VERSION ""

NS_ :

BS_:

BU_: APIM_CISM APIM ESPM DSP FCIMB RACM_RCIM HUD_ADV WCM TRM_ITRM ACM GWM _delete IPC GENERIC TSTR
VAL_TABLE_ AwdRnge_D_Actl 7 "Unknown" 6 "High_Range_2wd" 5 "High_Range_Auto" 4 "High_Range_Locked" 3 "Neutral" 2 "Low_Range_2wd" 1 "Low_Range_Auto" 0 "Low_Range_Locked" ;
VAL_TABLE_ AwdLck_D_Stat 9 "Undefined" 8 "Under_External_Torque_Ctrl" 7 "Torque_Limited_by_Cmd" 6 "Fully_Locked_by_Cmd" 5 "Disabled" 4 "Warning" 3 "Fault" 2 "Inactive" 1 "Completely_Opened_by_Cmd" 0 "OK" ;
VAL_TABLE_ Unknown_Fault_3FE_3FF 1023 "Fault" 1022 "Unknown" ;
VAL_TABLE_ LockSwStat 3 "Invalid" 2 "Unlock" 1 "Lock" 0 "Null" ;
VAL_TABLE_ Null_Override 1 "Override" 0 "Null" ;
VAL_TABLE_ Off_On_Flash 3 "Not_Used" 2 "Flash" 1 "On" 0 "Off" ;
VAL_TABLE_ BeltBuckle 3 "Unknown" 2 "Unbelted" 1 "Belted" 0 "Faulty" ;
VAL_TABLE_ RILStat 3 "Fault" 2 "Plant_Mode" 1 "On" 0 "Off" ;
VAL_TABLE_ RILReqCoding 3 "Not_Used" 2 "Plant_Mode" 1 "On" 0 "Off" ;
VAL_TABLE_ Update_Bit 1 "Fresh_data" 0 "Unchanged_data" ;
VAL_TABLE_ Tire_Pressure_Stat 4 "Alert" 15 "Not_Supported" 3 "Fault" 2 "Low" 1 "Normal" 0 "Unknown" ;
VAL_TABLE_ Tire_Pressure_System2 13 "Training_Complete" 12 "Train_InsideLeftRear_tire" 11 "Train_OutsideLeftRear_tire" 10 "Train_LeftRear_tire" 9 "Train_InsideRtRear_tire" 8 "Train_OutsideRtRear_tire" 7 "Train_RightRear_tire" 14 "Tires_not_trained" 6 "Train_RightFront_tire" 5 "Train_LeftFront_tire" 4 "Systm_Activ_Composite_Stat" 3 "Low_Composite_Stat" 2 "Sensr_Fault_Composite_Stat" 1 "Systm_Fault_Composite_Stat" 0 "Unknown_Composite_Stat" ;
VAL_TABLE_ Running_Board 3 "Unused" 2 "Manually_Deployed" 1 "All_Enabled" 0 "All_Disabled" ;
VAL_TABLE_ Turn_Seq 3 "Seq" 2 "On" 1 "Off" 0 "Null" ;
VAL_TABLE_ Invalid_Active_Inactive 3 "Not_Used" 2 "Inactive" 1 "Active" 0 "Invalid" ;
VAL_TABLE_ Rvc_Zoom 7 "Unknown" 6 "Invalid" 5 "Zoom_Level_V" 4 "Zoom_Level_IV" 3 "Zoom_Level_III" 2 "Zoom_Level_II" 1 "Zoom_Level_I" 0 "Off" ;
VAL_TABLE_ NotPark 1 "Park" 0 "Not_Park" ;
VAL_TABLE_ Electric_EOH 1 "Electric_Over_Hydraulic" 0 "Electric" ;
VAL_TABLE_ PersOptIn 1 "OPTED_IN" 0 "NOT_OPTED_IN" ;
VAL_TABLE_ PersonalSetUp 3 "Non_Moveable_Person" 2 "Moveable_Person" 1 "Vehicle" 0 "Factory" ;
VAL_TABLE_ Full_Limited 1 "Limited" 0 "Full" ;
VAL_TABLE_ NoConflict_Conflict 1 "Conflict" 0 "No_Conflict" ;
VAL_TABLE_ Assoc_Confirm 0 "None" 7 "Associate" 6 "Keycode_Rejected" 5 "Keycode_Accepted" 4 "In_Progress" 3 "Erase" 2 "Duplicate" 1 "Disassociate" ;
VAL_TABLE_ Check_KeyCode 7 "Unused_2" 6 "Cancel" 5 "Set_Keycode" 4 "RKE" 3 "Null" 2 "Key" 1 "Erase_KeyCode" 0 "Check_KeyCode" ;
VAL_TABLE_ Complete_Inprogress 3 "Unused" 2 "Null" 1 "InProgress" 0 "Complete" ;
VAL_TABLE_ Null_Pers1_4 7 "Unused_3" 6 "Unused_2" 5 "Unused_1" 4 "PERS_4" 3 "PERS_3" 2 "PERS_2" 1 "PERS_1" 0 "Null" ;
VAL_TABLE_ Pers1_4 7 "Unused_3" 6 "Unused_2" 5 "Unused_1" 4 "Vehicle" 3 "PERS_4" 2 "PERS_3" 1 "PERS_2" 0 "PERS_1" ;
VAL_TABLE_ Null_Query 7 "Unused_2" 6 "Unused_1" 5 "Copy" 4 "Restore" 3 "Upload" 2 "Set" 1 "Query" 0 "Null" ;
VAL_TABLE_ EngExhBrkMde_D_Actl 6 "ExhBrkDisable_NoError" 5 "ExhBrkActive_AUTO" 4 "ExhBrkActive_ON" 3 "ExhBrkRequest_AUTO" 2 "ExhBrkRequest_ON" 1 "ExhBrkNoRequest_OFF" 0 "ExhBrkUnavailable_Error" ;
VAL_TABLE_ UreaLvlTxt_D_RqDsply 15 "NotUsed_4" 14 "NotUsed_3" 13 "NotUsed_2" 12 "NotUsed_1" 11 "System_Error" 10 "Engine_Idled_See_Manual" 9 "Engine_Idled_Upon_Refuel" 8 "Speed_Limited_To_XX_mph" 7 "XXmph_Max_Upon_Restart" 6 "Speed_Limited_To_YY_mph" 5 "YYmph_Max_Upon_Restart" 4 "SpdLimtd_YYmph_In_XXmiles" 3 "ExFlRange_XXMiles_ScndWarn" 2 "Exh_Fluid_Range_XX_Miles" 1 "Exh_Fluid_Under_Half_Full" 0 "Exh_Fluid_Over_Half_Full" ;
VAL_TABLE_ RearDiffFalt_D_Stat 3 "Diff_Failed_Closed" 2 "Diff_Failed_Open" 1 "Fault_Non_Specific" 0 "No_Fault" ;
VAL_TABLE_ CCOverridden 1 "Cruise_Overridden" 0 "Cruise_Req_Not_Overridden" ;
VAL_TABLE_ Ign_Key_Device_Type 15 "Invalid" 14 "Unknown" 3 "Key_Not_Prgrm_Read_Failure" 2 "Key_In_Ign_My_Key" 1 "Key_In_Ign_Standard_Key" 0 "Key_Read_In_Progress" ;
VAL_TABLE_ Off_No_Eff_Unknown_Invalid 3 "Invalid" 2 "Unknown" 1 "No_Effect" 0 "Off" ;
VAL_TABLE_ Null_Out 1 "Out" 0 "Null" ;
VAL_TABLE_ FUEL_SENSORS 1 "Dual_Sensors" 0 "Single_Sensor" ;

BO_ 1204 HEV_EngineData2_HS3: 8 GWM
 SG_ DcacElPwScnd_D_Stat : 7|2@0+ (1,0) [0|3] "SED"  APIM
 SG_ DcacEngOnMsgTxt_D2_Rq : 5|4@0+ (1,0) [0|15] "SED"  APIM
 SG_ DcacOutScnd_Pw_DsplyMx : 15|10@0+ (10,0) [0|10220] "watts"  APIM
 SG_ DcacOutScnd_Pw2_Dsply : 21|13@0+ (1,0) [0|8189] "watts"  APIM
 SG_ DcacZone3Pw_B_Stat : 0|1@0+ (1,0) [0|1] "SED"  APIM
 SG_ DcacZone2Pw_B_Stat : 1|1@0+ (1,0) [0|1] "SED"  APIM

BO_ 826 Memory_Sw_StatM_HS3: 8 GWM
 SG_ Memory_3_Sw_Stat : 4|1@0+ (1,0) [0|1] "SED" Vector__XXX
 SG_ Memory_2_Sw_Stat : 5|1@0+ (1,0) [0|1] "SED" Vector__XXX
 SG_ Memory_1_Sw_Stat : 6|1@0+ (1,0) [0|1] "SED" Vector__XXX
 SG_ Mirror_Manual_Override : 0|1@0+ (1,0) [0|1] "SED"  APIM_CISM

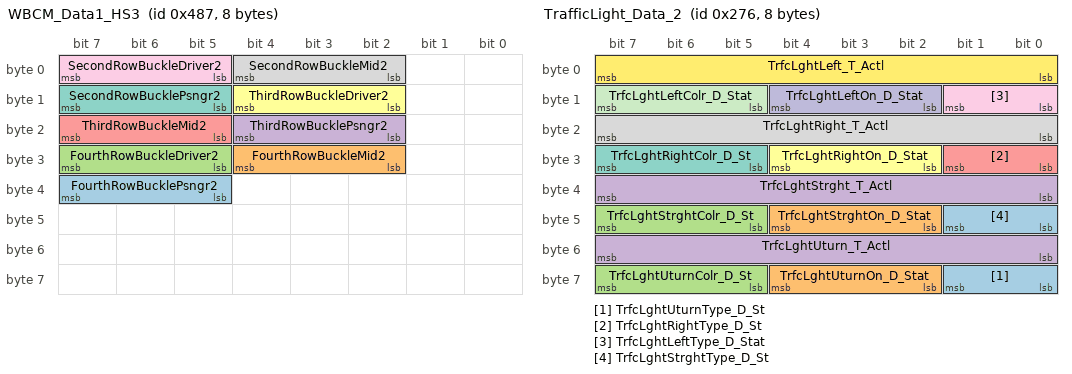
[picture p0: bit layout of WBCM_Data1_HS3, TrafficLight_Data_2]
BO_ 1159 WBCM_Data1_HS3: 8 GWM
 SG_ FourthRowBucklePsngr2 : 39|3@0+ (1,0) [0|7] "SED"  IPC
 SG_ FourthRowBuckleMid2 : 28|3@0+ (1,0) [0|7] "SED"  IPC
 SG_ FourthRowBuckleDriver2 : 31|3@0+ (1,0) [0|7] "SED"  IPC
 SG_ ThirdRowBucklePsngr2 : 20|3@0+ (1,0) [0|7] "SED"  IPC
 SG_ ThirdRowBuckleMid2 : 23|3@0+ (1,0) [0|7] "SED"  IPC
 SG_ ThirdRowBuckleDriver2 : 12|3@0+ (1,0) [0|7] "SED"  IPC
 SG_ SecondRowBucklePsngr2 : 15|3@0+ (1,0) [0|7] "SED"  IPC
 SG_ SecondRowBuckleMid2 : 4|3@0+ (1,0) [0|7] "SED"  IPC
 SG_ SecondRowBuckleDriver2 : 7|3@0+ (1,0) [0|7] "SED"  IPC

BO_ 667 APIM_NFAM_Word_Rx_HS3: 8 GWM
 SG_ APIM_NFAM_Word_Rx : 7|64@0+ (1,0) [0|1.84467440737096E+019] "unitless"  APIM,APIM_CISM

BO_ 659 APIM_NFAM_Word_Tx: 8 APIM
 SG_ APIM_NFAM_Word_Tx : 7|64@0+ (1,0) [0|1.84467440737096E+019] "unitless"  GWM

BO_ 645 ECG_Data5_HS3: 8 GWM
 SG_ VehImpactCode_No2_Actl : 7|16@0+ (1,0) [0|65535] "unitless"  APIM,APIM_CISM

BO_ 1040 AC_Compressor_Req_HS3: 8 GWM
 SG_ VehSimSnd_Pc_Rq : 33|10@0+ (0.2,-102.2) [-102.2|102.4] "percent"  APIM_CISM,ACM
 SG_ ElCmpr2Enbl_B_Rq : 36|1@0+ (1,0) [0|1] "SED" Vector__XXX
 SG_ ElCmpr2_N_Rq : 7|8@0+ (50,0) [0|12750] "RPM" Vector__XXX
 SG_ BattTrac_I2_EstVsc : 22|18@0+ (0.05,-6553.52) [-6553.52|6553.53] "ampere" Vector__XXX
 SG_ ElCmprEnbl_B_Rq : 23|1@0+ (1,0) [0|1] "SED" Vector__XXX
 SG_ ElCmpr_N_Rq : 15|8@0+ (50,0) [0|12750] "RPM" Vector__XXX

BO_ 630 TrafficLight_Data_2: 8 APIM
 SG_ TrfcLghtUturnType_D_St : 57|2@0+ (1,0) [0|3] "SED"  IPC,GWM
 SG_ TrfcLghtUturnOn_D_Stat : 60|3@0+ (1,0) [0|7] "SED"  IPC,GWM
 SG_ TrfcLghtUturnColr_D_St : 63|3@0+ (1,0) [0|7] "SED"  IPC,GWM
 SG_ TrfcLghtUturn_T_Actl : 55|8@0+ (1,0) [0|253] "second"  IPC,GWM
 SG_ TrfcLghtRightType_D_St : 25|2@0+ (1,0) [0|3] "SED"  IPC,GWM
 SG_ TrfcLghtRightOn_D_Stat : 28|3@0+ (1,0) [0|7] "SED"  IPC,GWM
 SG_ TrfcLghtRightColr_D_St : 31|3@0+ (1,0) [0|7] "SED"  IPC,GWM
 SG_ TrfcLghtRight_T_Actl : 23|8@0+ (1,0) [0|253] "second"  IPC,GWM
 SG_ TrfcLghtLeftType_D_Stat : 9|2@0+ (1,0) [0|3] "SED"  IPC,GWM
 SG_ TrfcLghtLeftOn_D_Stat : 12|3@0+ (1,0) [0|7] "SED"  IPC,GWM
 SG_ TrfcLghtLeftColr_D_Stat : 15|3@0+ (1,0) [0|7] "SED"  IPC,GWM
 SG_ TrfcLghtLeft_T_Actl : 7|8@0+ (1,0) [0|253] "second"  IPC,GWM
 SG_ TrfcLghtStrghtType_D_St : 41|2@0+ (1,0) [0|3] "SED"  IPC,GWM
 SG_ TrfcLghtStrghtOn_D_Stat : 44|3@0+ (1,0) [0|7] "SED"  IPC,GWM
 SG_ TrfcLghtStrghtColr_D_St : 47|3@0+ (1,0) [0|7] "SED"  IPC,GWM
 SG_ TrfcLghtStrght_T_Actl : 39|8@0+ (1,0) [0|253] "second"  IPC,GWM

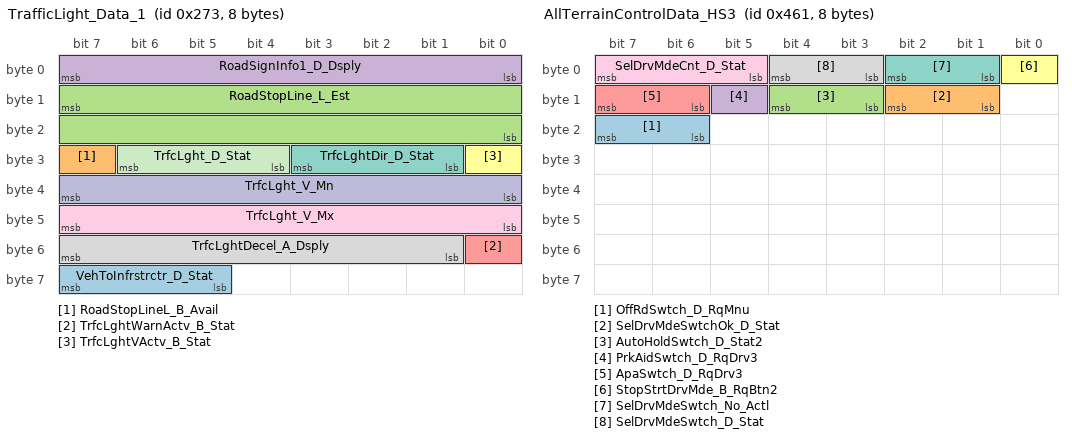
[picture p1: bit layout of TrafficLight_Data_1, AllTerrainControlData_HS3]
BO_ 627 TrafficLight_Data_1: 8 APIM
 SG_ VehToInfrstrctr_D_Stat : 63|3@0+ (1,0) [0|7] "SED"  IPC,GWM
 SG_ RoadStopLineL_B_Avail : 31|1@0+ (1,0) [0|1] "SED"  IPC,GWM
 SG_ RoadStopLine_L_Est : 15|16@0+ (1,0) [0|65533] "cm"  IPC,GWM
 SG_ RoadSignInfo1_D_Dsply : 7|8@0+ (1,0) [0|255] "SED"  IPC,GWM
 SG_ TrfcLghtWarnActv_B_Stat : 48|1@0+ (1,0) [0|1] "SED"  IPC,GWM
 SG_ TrfcLghtVActv_B_Stat : 24|1@0+ (1,0) [0|1] "SED"  IPC,GWM
 SG_ TrfcLghtDir_D_Stat : 27|3@0+ (1,0) [0|7] "SED"  IPC,GWM
 SG_ TrfcLghtDecel_A_Dsply : 55|7@0+ (1,0) [0|125] "km/hour"  IPC,GWM
 SG_ TrfcLght_V_Mx : 47|8@0+ (1,0) [0|253] "km/hour"  IPC,GWM
 SG_ TrfcLght_V_Mn : 39|8@0+ (1,0) [0|253] "km/hour"  IPC,GWM
 SG_ TrfcLght_D_Stat : 30|3@0+ (1,0) [0|7] "SED"  IPC,GWM

BO_ 874 RemoteClimate_Data_HS3: 8 FCIMB
 SG_ E_Rr_Btn_Status_2nd : 55|5@0+ (1,0) [0|31] "SED"  APIM,GWM,APIM_CISM
 SG_ E_Rr_Btn_Status_1st : 47|5@0+ (1,0) [0|31] "SED"  APIM,GWM,APIM_CISM
 SG_ E_Frt_Btn_Status_2nd : 39|6@0+ (1,0) [0|63] "SED"  APIM,GWM,APIM_CISM
 SG_ E_Frt_Btn_Status_1st : 30|6@0+ (1,0) [0|63] "SED"  APIM,GWM,APIM_CISM

BO_ 663 PowerTransferData_HS3: 8 GWM
 SG_ BptDchrg_Pw_Dsply : 49|10@0+ (0.1,0) [0|102.1] "kilowatt"  APIM,APIM_CISM
 SG_ Bpt_I_Est : 43|10@0+ (1,-510) [-510|511] "ampere"  APIM_CISM
 SG_ Bpt_Pw_Allw : 7|16@0+ (0.1,0) [0|6553.3] "kilowatt"  APIM,APIM_CISM
 SG_ BptDchrg_T_Rmng : 26|15@0+ (1,0) [0|32765] "minute"  APIM,APIM_CISM
 SG_ BptMnSoc_L_Actl : 23|13@0+ (0.1,0) [0|818.9] "kilometer"  APIM,APIM_CISM

BO_ 1161 HEV_Data_Monitor_22_HS3: 8 GWM
 SG_ BattTracUMxArry_No_Actl : 52|5@0+ (1,0) [0|30] "unitless" Vector__XXX
 SG_ BattTracCellUMx_No_Actl : 63|8@0+ (1,0) [0|253] "unitless" Vector__XXX
 SG_ BattChrgUMx_B_Falt : 53|1@0+ (1,0) [0|1] "SED" Vector__XXX
 SG_ BattTracCellUMn_No_Actl : 15|8@0+ (1,0) [0|253] "unitless" Vector__XXX
 SG_ BattTracCellCnt_No_Actl : 7|8@0+ (1,0) [0|253] "unitless" Vector__XXX
 SG_ BattChrgIsltn_B_Falt : 47|1@0+ (1,0) [0|1] "SED" Vector__XXX
 SG_ BattTracCellDiff_B_Falt : 43|1@0+ (1,0) [0|1] "SED" Vector__XXX
 SG_ BattChrgSocMx_B_Falt : 44|1@0+ (1,0) [0|1] "SED"  APIM,APIM_CISM
 SG_ BattChrgSocMn_B_Falt : 45|1@0+ (1,0) [0|1] "SED"  APIM,APIM_CISM
 SG_ BattChrgSocErrtc_B_Falt : 46|1@0+ (1,0) [0|1] "SED" Vector__XXX
 SG_ BattTracUMx_B_Falt : 54|1@0+ (1,0) [0|1] "SED" Vector__XXX
 SG_ BattTracUMn_B_Falt : 55|1@0+ (1,0) [0|1] "SED" Vector__XXX
 SG_ BattTracTeMx_No_Actl : 39|8@0+ (1,0) [0|253] "unitless" Vector__XXX
 SG_ BattTracTeMx_B_Falt : 40|1@0+ (1,0) [0|1] "SED" Vector__XXX
 SG_ BattTracTeMn_No_Actl : 31|8@0+ (1,0) [0|253] "unitless" Vector__XXX
 SG_ BattTracTeDelta_B_Falt : 41|1@0+ (1,0) [0|1] "SED" Vector__XXX
 SG_ BattTracTeCnt_No_Actl : 23|8@0+ (1,0) [0|253] "unitless" Vector__XXX
 SG_ BattTracSoftware_B_Falt : 42|1@0+ (1,0) [0|1] "SED" Vector__XXX

BO_ 1121 AllTerrainControlData_HS3: 8 GWM
 SG_ OffRdSwtch_D_RqMnu : 23|2@0+ (1,0) [0|3] "SED"  APIM,APIM_CISM
 SG_ SelDrvMdeSwtchOk_D_Stat : 10|2@0+ (1,0) [0|3] "SED" Vector__XXX
 SG_ AutoHoldSwtch_D_Stat2 : 12|2@0+ (1,0) [0|3] "SED" Vector__XXX
 SG_ PrkAidSwtch_D_RqDrv3 : 13|1@0+ (1,0) [0|1] "SED" Vector__XXX
 SG_ ApaSwtch_D_RqDrv3 : 15|2@0+ (1,0) [0|3] "SED" Vector__XXX
 SG_ StopStrtDrvMde_B_RqBtn2 : 0|1@0+ (1,0) [0|1] "SED" Vector__XXX
 SG_ SelDrvMdeSwtch_No_Actl : 2|2@0+ (1,0) [0|3] "unitless" Vector__XXX
 SG_ SelDrvMdeSwtch_D_Stat : 4|2@0+ (1,0) [0|3] "SED" Vector__XXX
 SG_ SelDrvMdeCnt_D_Stat : 7|3@0+ (1,0) [0|7] "Counts" Vector__XXX

BO_ 669 Pass_Dr_Stat2_HS3: 8 GWM
 SG_ DrHandleOuterRr_D_Stat : 4|3@0+ (1,0) [0|7] "SED"  IPC
 SG_ DrHandleOuterFr_D_Stat : 7|3@0+ (1,0) [0|7] "SED"  IPC

BO_ 571 OBS_Load_Data_HS3: 8 GWM
 SG_ VehFalr_Pc_Est : 47|7@0+ (1,0) [0|125] "percent"  APIM,APIM_CISM
 SG_ TrlrTngLoad_Pc_Est : 39|7@0+ (1,0) [0|125] "percent"  APIM,APIM_CISM
 SG_ TrlrTngLoad_M_Est : 7|11@0+ (10,-10240) [-10240|10210] "kilogram"  APIM,APIM_CISM
 SG_ VehPayloadAdd_M_Est : 12|11@0+ (5,-5115) [-5115|5110] "kilogram"  APIM,APIM_CISM
 SG_ VehPayload_Pc_Est : 55|7@0+ (1,0) [0|125] "percent"  APIM,APIM_CISM
 SG_ VehPayload_M_Est : 17|10@0+ (5,0) [0|5105] "kilogram"  APIM,APIM_CISM

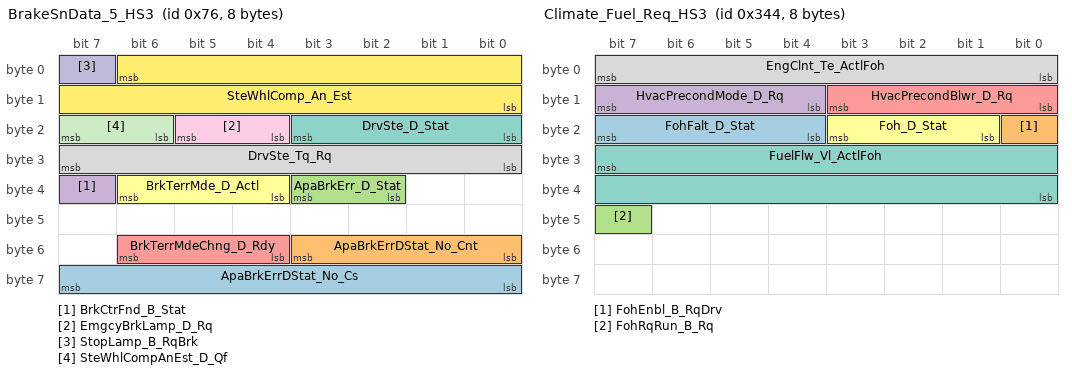
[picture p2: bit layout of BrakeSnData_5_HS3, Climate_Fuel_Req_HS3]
BO_ 118 BrakeSnData_5_HS3: 8 GWM
 SG_ ApaBrkErrDStat_No_Cs : 63|8@0+ (1,0) [0|255] "Unitless" Vector__XXX
 SG_ ApaBrkErrDStat_No_Cnt : 51|4@0+ (1,0) [0|15] "Unitless" Vector__XXX
 SG_ ApaBrkErr_D_Stat : 35|2@0+ (1,0) [0|3] "SED" Vector__XXX
 SG_ BrkCtrFnd_B_Stat : 39|1@0+ (1,0) [0|1] "SED" Vector__XXX
 SG_ BrkTerrMdeChng_D_Rdy : 54|3@0+ (1,0) [0|7] "SED" Vector__XXX
 SG_ BrkTerrMde_D_Actl : 38|3@0+ (1,0) [0|7] "SED" Vector__XXX
 SG_ DrvSte_D_Stat : 19|4@0+ (1,0) [0|15] "SED" Vector__XXX
 SG_ DrvSte_Tq_Rq : 31|8@0+ (0.0625,-8) [-8|7.8125] "Nm" Vector__XXX
 SG_ EmgcyBrkLamp_D_Rq : 21|2@0+ (1,0) [0|3] "SED" Vector__XXX
 SG_ StopLamp_B_RqBrk : 7|1@0+ (1,0) [0|1] "SED" Vector__XXX
 SG_ SteWhlCompAnEst_D_Qf : 23|2@0+ (1,0) [0|3] "SED"  APIM_CISM,IPC
 SG_ SteWhlComp_An_Est : 6|15@0+ (0.1,-1600) [-1600|1676.7] "degrees"  APIM,APIM_CISM,IPC

BO_ 868 Clmt_Button_Stat6_HS3: 8 GWM
 SG_ E_Frt_Btn_Status_2nd : 23|6@0+ (1,0) [0|63] "SED"  APIM,APIM_CISM
 SG_ E_Frt_Btn_Status_1st : 15|6@0+ (1,0) [0|63] "SED"  APIM,APIM_CISM
 SG_ Rr_Blower_Indicate_Stat : 7|4@0+ (1,0) [0|15] "SED" Vector__XXX

BO_ 836 Climate_Fuel_Req_HS3: 8 GWM
 SG_ FohFalt_D_Stat : 23|4@0+ (1,0) [0|15] "SED" Vector__XXX
 SG_ FohEnbl_B_RqDrv : 16|1@0+ (1,0) [0|1] "SED" Vector__XXX
 SG_ FohRqRun_B_Rq : 47|1@0+ (1,0) [0|1] "SED" Vector__XXX
 SG_ HvacPrecondMode_D_Rq : 15|4@0+ (1,0) [0|15] "SED" Vector__XXX
 SG_ HvacPrecondBlwr_D_Rq : 11|4@0+ (1,0) [0|15] "SED" Vector__XXX
 SG_ Foh_D_Stat : 19|3@0+ (1,0) [0|7] "SED" Vector__XXX
 SG_ FuelFlw_Vl_ActlFoh : 31|16@0+ (25,0) [0|1638375] "microlitre"  APIM,APIM_CISM,IPC
 SG_ EngClnt_Te_ActlFoh : 7|8@0+ (1,-50) [-50|204] "degC" Vector__XXX

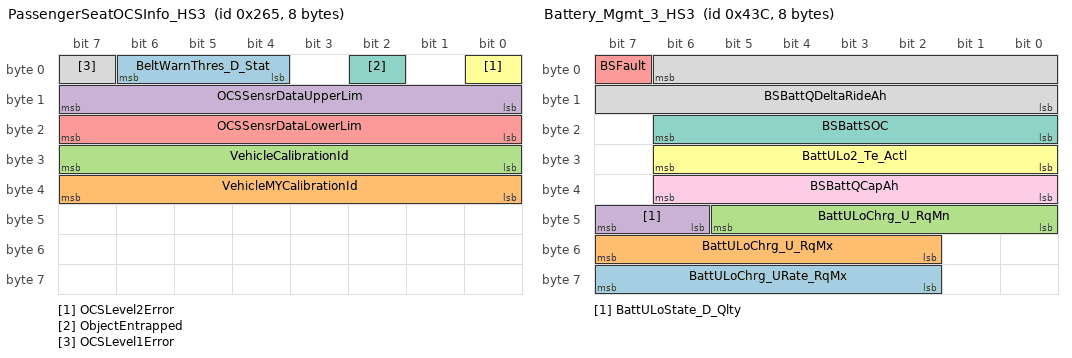
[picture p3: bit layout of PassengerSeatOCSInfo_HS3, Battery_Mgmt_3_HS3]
BO_ 613 PassengerSeatOCSInfo_HS3: 8 GWM
 SG_ BeltWarnThres_D_Stat : 6|3@0+ (1,0) [0|7] "SED" Vector__XXX
 SG_ VehicleMYCalibrationId : 39|8@0+ (1,0) [0|254] "SED" Vector__XXX
 SG_ VehicleCalibrationId : 31|8@0+ (1,0) [0|254] "SED" Vector__XXX
 SG_ OCSSensrDataUpperLim : 15|8@0+ (1,0) [0|254] "SED" Vector__XXX
 SG_ OCSSensrDataLowerLim : 23|8@0+ (1,0) [0|254] "SED" Vector__XXX
 SG_ OCSLevel2Error : 0|1@0+ (1,0) [0|1] "SED" Vector__XXX
 SG_ ObjectEntrapped : 2|1@0+ (1,0) [0|1] "SED"  IPC
 SG_ OCSLevel1Error : 7|1@0+ (1,0) [0|1] "SED" Vector__XXX

BO_ 1084 Battery_Mgmt_3_HS3: 8 GWM
 SG_ BattULoChrg_URate_RqMx : 63|6@0+ (0.1,0) [0|6.3] "volts/second" Vector__XXX
 SG_ BattULoChrg_U_RqMx : 55|6@0+ (0.1,10.6) [10.6|16.9] "volt" Vector__XXX
 SG_ BattULoChrg_U_RqMn : 45|6@0+ (0.1,10.6) [10.6|16.9] "volt" Vector__XXX
 SG_ BattULoState_D_Qlty : 47|2@0+ (1,0) [0|3] "SED" Vector__XXX
 SG_ BSFault : 7|1@0+ (1,0) [0|1] "SED" Vector__XXX
 SG_ BattULo2_Te_Actl : 30|7@0+ (1,-40) [-40|86] "degC" Vector__XXX
 SG_ BSBattSOC : 22|7@0+ (1,0) [0|127] "%"  APIM,APIM_CISM
 SG_ BSBattQDeltaRideAh : 6|15@0+ (0.0078125,-100) [-100|155.9921875] "ampere*hour" Vector__XXX
 SG_ BSBattQCapAh : 38|7@0+ (1,0) [0|127] "ampere*hour" Vector__XXX

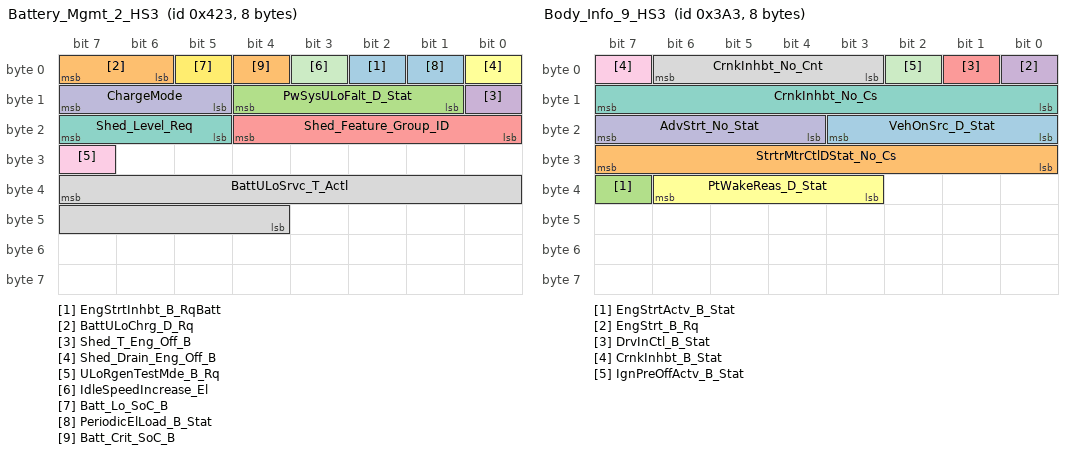
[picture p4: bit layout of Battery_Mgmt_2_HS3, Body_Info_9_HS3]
BO_ 1059 Battery_Mgmt_2_HS3: 8 GWM
 SG_ EngStrtInhbt_B_RqBatt : 2|1@0+ (1,0) [0|1] "SED" Vector__XXX
 SG_ BattULoChrg_D_Rq : 7|2@0+ (1,0) [0|3] "SED" Vector__XXX
 SG_ PwSysULoFalt_D_Stat : 12|4@0+ (1,0) [0|15] "SED"  IPC
 SG_ Shed_T_Eng_Off_B : 8|1@0+ (1,0) [0|1] "SED"  APIM,APIM_CISM,TRM_ITRM
 SG_ Shed_Feature_Group_ID : 20|5@0+ (1,0) [0|31] "SED"  TRM_ITRM
 SG_ Shed_Drain_Eng_Off_B : 0|1@0+ (1,0) [0|1] "SED"  APIM,APIM_CISM,TRM_ITRM
 SG_ Shed_Level_Req : 23|3@0+ (1,0) [0|7] "SED"  APIM,APIM_CISM,TRM_ITRM,IPC
 SG_ BattULoSrvc_T_Actl : 39|12@0+ (1,0) [0|4095] "day" Vector__XXX
 SG_ ULoRgenTestMde_B_Rq : 31|1@0+ (1,0) [0|1] "SED" Vector__XXX
 SG_ ChargeMode : 15|3@0+ (1,0) [0|7] "SED" Vector__XXX
 SG_ IdleSpeedIncrease_El : 3|1@0+ (1,0) [0|1] "SED" Vector__XXX
 SG_ Batt_Lo_SoC_B : 5|1@0+ (1,0) [0|1] "SED"  APIM,APIM_CISM,TRM_ITRM,IPC
 SG_ PeriodicElLoad_B_Stat : 1|1@0+ (1,0) [0|1] "SED" Vector__XXX
 SG_ Batt_Crit_SoC_B : 4|1@0+ (1,0) [0|1] "SED"  APIM,APIM_CISM,TRM_ITRM,IPC

BO_ 131 Steering_Data_HS3: 8 GWM
 SG_ HeadLghtHiCtrl_D_RqAhb : 43|3@0+ (1,0) [0|7] "SED" Vector__XXX
 SG_ AhbStat_B_Dsply : 33|1@0+ (1,0) [0|1] "SED"  IPC
 SG_ WiprFrontSwtch_D_Stat : 47|4@0+ (1,0) [0|15] "SED" Vector__XXX
 SG_ HeadLghtHiOn_B_StatAhb : 34|1@0+ (1,0) [0|1] "SED"  APIM,APIM_CISM,IPC
 SG_ HeadLghtHiFlash_D_Actl : 36|2@0+ (1,0) [0|3] "SED" Vector__XXX
 SG_ TjaButtnOnOffPress : 40|1@0+ (1,0) [0|1] "SED" Vector__XXX
 SG_ AccButtnGapTogglePress : 32|1@0+ (1,0) [0|1] "SED" Vector__XXX
 SG_ WiprFront_D_Stat : 3|4@0+ (1,0) [0|15] "SED"  APIM,APIM_CISM
 SG_ TurnLghtSwtch_D_Stat : 5|2@0+ (1,0) [0|3] "SED"  APIM,APIM_CISM,IPC
 SG_ LghtAmb_D_Sns : 15|3@0+ (1,0) [0|7] "SED" Vector__XXX
 SG_ AccButtnGapIncPress : 11|1@0+ (1,0) [0|1] "SED" Vector__XXX
 SG_ AccButtnGapDecPress : 12|1@0+ (1,0) [0|1] "SED" Vector__XXX
 SG_ AslButtnOnOffPress : 9|1@0+ (1,0) [0|1] "SED" Vector__XXX
 SG_ AslButtnOnOffCnclPress : 10|1@0+ (1,0) [0|1] "SED" Vector__XXX
 SG_ CcButtnOnPress : 37|1@0+ (1,0) [0|1] "SED" Vector__XXX
 SG_ CcButtnOnOffPress : 38|1@0+ (1,0) [0|1] "SED" Vector__XXX
 SG_ CcButtnOnOffCnclPress : 39|1@0+ (1,0) [0|1] "SED" Vector__XXX
 SG_ CcButtnOffPress : 24|1@0+ (1,0) [0|1] "SED" Vector__XXX
 SG_ CcAsllButtnResPress : 25|1@0+ (1,0) [0|1] "SED" Vector__XXX
 SG_ CcAslButtnSetPress : 26|1@0+ (1,0) [0|1] "SED" Vector__XXX
 SG_ CcAslButtnSetIncPress : 27|1@0+ (1,0) [0|1] "SED" Vector__XXX
 SG_ CcAslButtnSetDecPress : 28|1@0+ (1,0) [0|1] "SED" Vector__XXX
 SG_ CcAslButtnResIncPress : 29|1@0+ (1,0) [0|1] "SED" Vector__XXX
 SG_ CcAslButtnResDecPress : 30|1@0+ (1,0) [0|1] "SED" Vector__XXX
 SG_ CcAslButtnOnPress : 31|1@0+ (1,0) [0|1] "SED" Vector__XXX
 SG_ CcAslButtnOnOffCncl : 16|1@0+ (1,0) [0|1] "SED" Vector__XXX
 SG_ CcAslButtnOffCnclPress : 17|1@0+ (1,0) [0|1] "SED" Vector__XXX
 SG_ CcAslButtnIndxIncPress : 18|1@0+ (1,0) [0|1] "SED" Vector__XXX
 SG_ CcAslButtnIndxDecPress : 19|1@0+ (1,0) [0|1] "SED" Vector__XXX
 SG_ CcAslButtnDeny_B_Actl : 20|1@0+ (1,0) [0|1] "SED" Vector__XXX
 SG_ CcAslButtnCnclResPress : 21|1@0+ (1,0) [0|1] "SED" Vector__XXX
 SG_ CcAslButtnCnclPress : 8|1@0+ (1,0) [0|1] "SED" Vector__XXX
 SG_ LaSwtchPos_D_Stat : 23|2@0+ (1,0) [0|3] "SED" Vector__XXX

BO_ 931 Body_Info_9_HS3: 8 GWM
 SG_ VehOnSrc_D_Stat : 19|4@0+ (1,0) [0|15] "SED"  APIM,APIM_CISM,IPC
 SG_ StrtrMtrCtlDStat_No_Cs : 31|8@0+ (1,0) [0|255] "unitless" Vector__XXX
 SG_ EngStrtActv_B_Stat : 39|1@0+ (1,0) [0|1] "SED" Vector__XXX
 SG_ EngStrt_B_Rq : 0|1@0+ (1,0) [0|1] "SED" Vector__XXX
 SG_ DrvInCtl_B_Stat : 1|1@0+ (1,0) [0|1] "SED" Vector__XXX
 SG_ PtWakeReas_D_Stat : 38|4@0+ (1,0) [0|15] "SED" Vector__XXX
 SG_ CrnkInhbt_No_Cs : 15|8@0+ (1,0) [0|255] "unitless" Vector__XXX
 SG_ CrnkInhbt_No_Cnt : 6|4@0+ (1,0) [0|15] "unitless" Vector__XXX
 SG_ CrnkInhbt_B_Stat : 7|1@0+ (1,0) [0|1] "SED" Vector__XXX
 SG_ AdvStrt_No_Stat : 23|4@0+ (1,0) [0|15] "unitless" Vector__XXX
 SG_ IgnPreOffActv_B_Stat : 2|1@0+ (1,0) [0|1] "SED" Vector__XXX

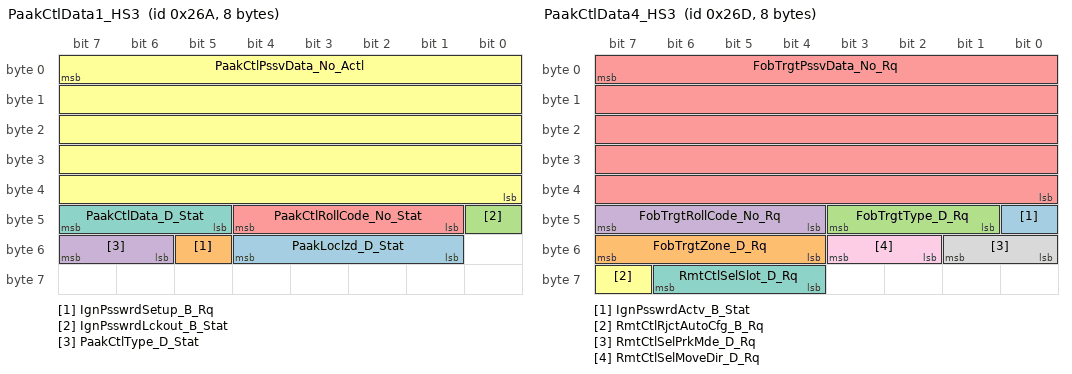
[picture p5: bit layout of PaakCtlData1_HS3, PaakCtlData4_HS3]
BO_ 618 PaakCtlData1_HS3: 8 GWM
 SG_ PaakLoclzd_D_Stat : 52|4@0+ (1,0) [0|15] "SED" Vector__XXX
 SG_ IgnPsswrdSetup_B_Rq : 53|1@0+ (1,0) [0|1] "SED"  APIM,APIM_CISM
 SG_ IgnPsswrdLckout_B_Stat : 40|1@0+ (1,0) [0|1] "SED"  APIM,APIM_CISM
 SG_ PaakCtlType_D_Stat : 55|2@0+ (1,0) [0|3] "SED" Vector__XXX
 SG_ PaakCtlRollCode_No_Stat : 44|4@0+ (1,0) [0|15] "unitless" Vector__XXX
 SG_ PaakCtlPssvData_No_Actl : 7|40@0+ (1,0) [0|1099511627775] "unitless" Vector__XXX
 SG_ PaakCtlData_D_Stat : 47|3@0+ (1,0) [0|7] "SED" Vector__XXX

BO_ 621 PaakCtlData4_HS3: 8 GWM
 SG_ IgnPsswrdActv_B_Stat : 40|1@0+ (1,0) [0|1] "SED"  APIM,APIM_CISM
 SG_ FobTrgtZone_D_Rq : 55|4@0+ (1,0) [0|15] "SED" Vector__XXX
 SG_ FobTrgtType_D_Rq : 43|3@0+ (1,0) [0|7] "SED" Vector__XXX
 SG_ FobTrgtRollCode_No_Rq : 47|4@0+ (1,0) [0|15] "unitless" Vector__XXX
 SG_ FobTrgtPssvData_No_Rq : 7|40@0+ (1,0) [0|1099511627775] "Encrypted" Vector__XXX
 SG_ RmtCtlRjctAutoCfg_B_Rq : 63|1@0+ (1,0) [0|1] "SED" Vector__XXX
 SG_ RmtCtlSelSlot_D_Rq : 62|3@0+ (1,0) [0|7] "SED" Vector__XXX
 SG_ RmtCtlSelPrkMde_D_Rq : 49|2@0+ (1,0) [0|3] "SED" Vector__XXX
 SG_ RmtCtlSelMoveDir_D_Rq : 51|2@0+ (1,0) [0|3] "SED" Vector__XXX

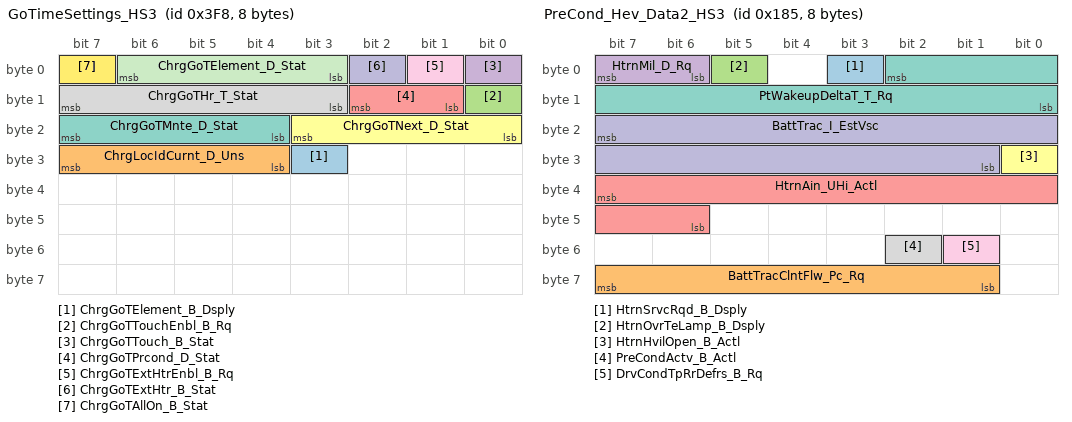
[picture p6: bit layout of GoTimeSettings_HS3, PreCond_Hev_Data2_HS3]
BO_ 1016 GoTimeSettings_HS3: 8 GWM
 SG_ ChrgGoTElement_B_Dsply : 27|1@0+ (1,0) [0|1] "SED"  APIM,APIM_CISM
 SG_ ChrgLocIdCurnt_D_Uns : 31|4@0+ (1,0) [0|15] "unitless"  APIM,APIM_CISM
 SG_ ChrgGoTTouchEnbl_B_Rq : 8|1@0+ (1,0) [0|1] "SED" Vector__XXX
 SG_ ChrgGoTTouch_B_Stat : 0|1@0+ (1,0) [0|1] "SED"  APIM,APIM_CISM
 SG_ ChrgGoTPrcond_D_Stat : 10|2@0+ (1,0) [0|3] "SED"  APIM,APIM_CISM
 SG_ ChrgGoTNext_D_Stat : 19|4@0+ (1,0) [0|15] "unitless"  APIM,APIM_CISM
 SG_ ChrgGoTMnte_D_Stat : 23|4@0+ (1,0) [0|15] "SED"  APIM,APIM_CISM
 SG_ ChrgGoTHr_T_Stat : 15|5@0+ (1,0) [0|29] "hour"  APIM,APIM_CISM
 SG_ ChrgGoTExtHtrEnbl_B_Rq : 1|1@0+ (1,0) [0|1] "SED" Vector__XXX
 SG_ ChrgGoTExtHtr_B_Stat : 2|1@0+ (1,0) [0|1] "SED"  APIM,APIM_CISM
 SG_ ChrgGoTElement_D_Stat : 6|4@0+ (1,0) [0|15] "unitless"  APIM,APIM_CISM
 SG_ ChrgGoTAllOn_B_Stat : 7|1@0+ (1,0) [0|1] "SED"  APIM,APIM_CISM

BO_ 773 PassengerSeat_Data_HS3: 8 GWM
 SG_ StmsScrnPsngrOn_B_Rq : 1|1@0+ (1,0) [0|1] "SED"  APIM,APIM_CISM
 SG_ SeatScrnPsngrOn_B_Rq : 6|1@0+ (1,0) [0|1] "SED"  APIM,APIM_CISM
 SG_ SeatPsngrMem_D_Cmd : 5|4@0+ (1,0) [0|15] "SED" Vector__XXX
 SG_ MemSwtchPsngrFdbck_B_Rq : 7|1@0+ (1,0) [0|1] "SED" Vector__XXX

BO_ 389 PreCond_Hev_Data2_HS3: 8 GWM
 SG_ HtrnSrvcRqd_B_Dsply : 3|1@0+ (1,0) [0|1] "SED"  APIM_CISM,IPC
 SG_ BattTracClntFlw_Pc_Rq : 63|7@0+ (1,0) [0|127] "percent" Vector__XXX
 SG_ HtrnOvrTeLamp_B_Dsply : 5|1@0+ (1,0) [0|1] "SED"  IPC,APIM_CISM
 SG_ HtrnMil_D_Rq : 7|2@0+ (1,0) [0|3] "SED" Vector__XXX
 SG_ HtrnAin_UHi_Actl : 39|10@0+ (0.5,0) [0|510.5] "volt" Vector__XXX
 SG_ HtrnHvilOpen_B_Actl : 24|1@0+ (1,0) [0|1] "SED" Vector__XXX
 SG_ PtWakeupDeltaT_T_Rq : 2|11@0+ (1,0) [0|2045] "minute" Vector__XXX
 SG_ PreCondActv_B_Actl : 50|1@0+ (1,0) [0|1] "SED" Vector__XXX
 SG_ DrvCondTpRrDefrs_B_Rq : 49|1@0+ (1,0) [0|1] "SED" Vector__XXX
 SG_ BattTrac_I_EstVsc : 23|15@0+ (0.05,-750) [-750|888.25] "Amps" Vector__XXX

BO_ 1128 BatteryCharge_Data2_HS3: 8 GWM
 SG_ DgtlCommGtwyMde_D_Rq : 48|4@0+ (1,0) [0|15] "SED" Vector__XXX
 SG_ ChrgrDcOvrVolt_B_Falt : 50|1@0+ (1,0) [0|1] "SED" Vector__XXX
 SG_ ChrgrDcOvrCurnt_B_Falt : 56|1@0+ (1,0) [0|1] "SED" Vector__XXX
 SG_ ExtChrgNowButtn_B_Rq : 49|1@0+ (1,0) [0|1] "SED" Vector__XXX
 SG_ CoolFanChrgr_D_Rq : 45|2@0+ (1,0) [0|3] "SED" Vector__XXX
 SG_ ChrgrPncEnbl_D_Stat : 58|2@0+ (1,0) [0|3] "SED" Vector__XXX
 SG_ ChrgrClntFlw_D_Rq : 31|2@0+ (1,0) [0|3] "SED" Vector__XXX
 SG_ PlgStatEvnt_B_Stat : 46|1@0+ (1,0) [0|1] "SED" Vector__XXX
 SG_ ChrgrCnnctPwr_B_Stat : 47|1@0+ (1,0) [0|1] "SED" Vector__XXX
 SG_ ChrgrAvailEvnt_B_Stat : 32|1@0+ (1,0) [0|1] "SED" Vector__XXX
 SG_ ChrgrSrvcRqd_B_Rq : 0|1@0+ (1,0) [0|1] "SED"  IPC
 SG_ ChrgrS2Swtch_B_Stat : 42|1@0+ (1,0) [0|1] "SED" Vector__XXX
 SG_ ChrgChngEvnt_B_Stat : 33|1@0+ (1,0) [0|1] "SED" Vector__XXX
 SG_ ChrgrCc2Cnnct_B_Falt : 59|1@0+ (1,0) [0|1] "SED" Vector__XXX
 SG_ ChrgPortDcTeMx_B_Falt : 60|1@0+ (1,0) [0|1] "SED" Vector__XXX
 SG_ ChrgCordLck_D_Stat : 7|3@0+ (1,0) [0|7] "SED"  APIM,APIM_CISM
 SG_ ChrgrInPwMde_D_Actl : 4|4@0+ (1,0) [0|15] "SED" Vector__XXX
 SG_ ChrgPortDrOpen_B_Stat : 43|1@0+ (1,0) [0|1] "SED"  IPC
 SG_ ChrgCordChlng2_No_Actl : 23|8@0+ (1,0) [0|255] "unitless" Vector__XXX
 SG_ AcChrgRdy_B_Stat : 51|1@0+ (1,0) [0|1] "SED" Vector__XXX
 SG_ BptTgl_B_Complt : 29|1@0+ (1,0) [0|1] "SED" Vector__XXX
 SG_ ChrgCordChlng1_No_Actl : 15|8@0+ (1,0) [0|255] "unitless" Vector__XXX
 SG_ ChrgCrdLck_D_Falt : 41|2@0+ (1,0) [0|3] "SED"  APIM,APIM_CISM,IPC

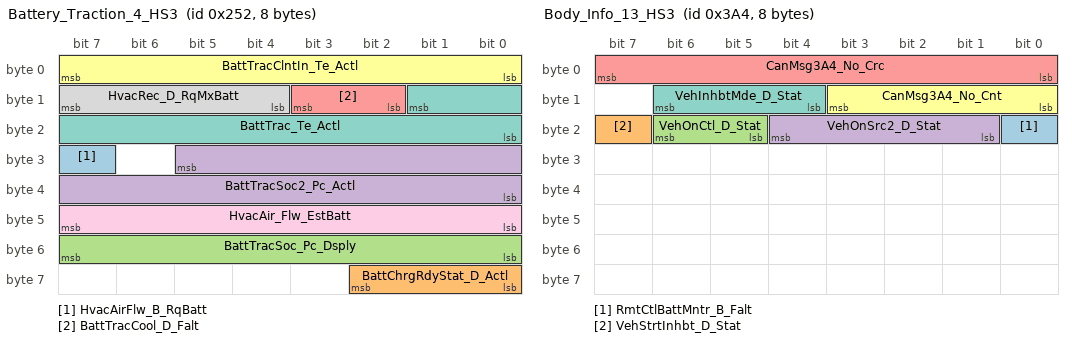
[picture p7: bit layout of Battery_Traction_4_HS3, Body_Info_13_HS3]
BO_ 594 Battery_Traction_4_HS3: 8 GWM
 SG_ HvacAirFlw_B_RqBatt : 31|1@0+ (1,0) [0|1] "SED" Vector__XXX
 SG_ BattChrgRdyStat_D_Actl : 58|3@0+ (1,0) [0|7] "SED" Vector__XXX
 SG_ BattTracSoc_Pc_Dsply : 55|8@0+ (0.5,0) [0|126.5] "Percent"  APIM,HUD_ADV,IPC,APIM_CISM
 SG_ BattTracSoc2_Pc_Actl : 29|14@0+ (0.01,0) [0|163.81] "%" Vector__XXX
 SG_ BattTracCool_D_Falt : 11|2@0+ (1,0) [0|3] "SED" Vector__XXX
 SG_ BattTracClntIn_Te_Actl : 7|8@0+ (1,-50) [-50|204] "degC" Vector__XXX
 SG_ BattTrac_Te_Actl : 9|10@0+ (0.5,-50) [-50|460.5] "degC" Vector__XXX
 SG_ HvacRec_D_RqMxBatt : 15|4@0+ (1,0) [0|15] "SED" Vector__XXX
 SG_ HvacAir_Flw_EstBatt : 47|8@0+ (0.5,0) [0|127] "liter/second" Vector__XXX

BO_ 2614099160 SymKeyFuncGWM_ECG_HS3: 8 GWM
 SG_ SymKeyFuncGWM_ECG : 7|29@0+ (1,0) [0|536870911] "unitless"  WCM,IPC,ESPM

BO_ 2610117848 OTAPhysGWM_ECGtoESPM: 8 GWM
 SG_ OTAPhysGWM_ECGtoESPM : 7|29@0+ (1,0) [0|536870911] "unitless"  ESPM

BO_ 2610127055 OTAPhysESPMtoGWM_ECG: 8 ESPM
 SG_ OTAPhysESPMtoGWM_ECG : 7|29@0+ (1,0) [0|536870911] "unitless"  GWM

BO_ 2611175631 PARSEDPhysESPMtoGWM_ECG: 8 ESPM
 SG_ PARSEDPhysESPMtoGWM_ECG : 7|29@0+ (1,0) [0|536870911] "unitless"  GWM

BO_ 2612215000 PARSEDPushFcGWM_ECGtoESPM: 8 GWM
 SG_ PARSEDPushFcGWM_ECGtoESPM : 7|29@0+ (1,0) [0|536870911] "unitless"  ESPM

BO_ 2612224207 PARSEDPushESPMoGWM_ECG: 8 ESPM
 SG_ PARSEDPushESPMoGWM_ECG : 7|29@0+ (1,0) [0|536870911] "unitless"  ESPM

BO_ 2613263576 SymKeyPhysGWM_ECGtoESPM: 8 GWM
 SG_ SymKeyPhysGWM_ECGtoESPM : 7|29@0+ (1,0) [0|536870911] "unitless"  ESPM

BO_ 2613272783 SymKeyPhysESPMtoGWM_ECG: 8 ESPM
 SG_ SymKeyPhysESPMtoGWM_ECG : 7|29@0+ (1,0) [0|536870911] "unitless"  GWM

BO_ 932 Body_Info_13_HS3: 8 GWM
 SG_ RmtCtlBattMntr_B_Falt : 16|1@0+ (1,0) [0|1] "SED" Vector__XXX
 SG_ VehStrtInhbt_D_Stat : 23|1@0+ (1,0) [0|1] "SED"  ESPM
 SG_ VehOnCtl_D_Stat : 22|2@0+ (1,0) [0|3] "SED" Vector__XXX
 SG_ VehOnSrc2_D_Stat : 20|4@0+ (1,0) [0|15] "SED"  ESPM
 SG_ CanMsg3A4_No_Crc : 7|8@0+ (1,0) [0|255] "unitless" Vector__XXX
 SG_ CanMsg3A4_No_Cnt : 11|4@0+ (1,0) [0|15] "unitless" Vector__XXX
 SG_ VehInhbtMde_D_Stat : 14|3@0+ (1,0) [0|7] "SED" Vector__XXX

BO_ 1388 ESPM_AutoSar_Network_Mgmt: 8 ESPM
 SG_ ESPM_GWOnBoardTester : 39|8@0+ (1,0) [0|255] "unitless"  GENERIC
 SG_ ESPM_GWNMProxy : 47|8@0+ (1,0) [0|255] "unitless"  GENERIC
 SG_ ESPM_AutoSarNMReserved4 : 63|8@0+ (1,0) [0|255] "unitless"  GENERIC
 SG_ ESPM_AutoSarNMReserved3 : 55|8@0+ (1,0) [0|255] "unitless"  GENERIC
 SG_ ESPM_AutoSarNMReserved2 : 31|8@0+ (1,0) [0|255] "unitless"  GENERIC
 SG_ ESPM_AutoSarNMReserved1 : 23|8@0+ (1,0) [0|255] "unitless"  GENERIC
 SG_ ESPM_AutoSarNMNodeId : 7|8@0+ (1,0) [0|255] "unitless"  GENERIC
 SG_ ESPM_AutoSarNMControl : 15|8@0+ (1,0) [0|255] "unitless"  GENERIC

BO_ 1769 TesterPhysicalResESPM: 8 ESPM
 SG_ TesterPhysicalResESPM : 7|64@0+ (1,0) [0|1.84467E+019] "unitless"  TSTR

BO_ 1761 TesterPhysicalReqESPM: 8 TSTR
 SG_ TesterPhysicalReqESPM : 7|64@0+ (1,0) [0|1.84467E+019] "unitless"  ESPM

BO_ 528 Body_Info_17_HS3: 8 GWM
 SG_ TireRear_P_OffRoad2 : 31|8@0+ (1,0) [0|255] "pounds/inch^2"  IPC
 SG_ TireRear_P_OffRoad1 : 23|8@0+ (1,0) [0|255] "pounds/inch^2"  IPC
 SG_ TireFront_P_OffRoad2 : 15|8@0+ (1,0) [0|255] "pounds/inch^2"  IPC
 SG_ TireFront_P_OffRoad1 : 7|8@0+ (1,0) [0|255] "pounds/inch^2"  IPC
 SG_ TireInflateMsgTxt_B_Rq : 39|1@0+ (1,0) [0|1] "SED"  IPC
 SG_ OffRoadMde_D_Stat : 38|3@0+ (1,0) [0|7] "SED"  IPC

BO_ 591 Battery_Traction_8_HS3: 8 GWM
 SG_ BattTrac_U_Nom : 11|10@0+ (0.5,0) [0|510.5] "volt" Vector__XXX
 SG_ BattTrac_E_Nom : 7|12@0+ (50,0) [0|204650] "watt*hr"  APIM,APIM_CISM
 SG_ BattTrac_Ah_Nom : 31|12@0+ (0.1,0) [0|409.4] "ampere*hour" Vector__XXX
 SG_ BattTracType_D_Actl : 35|4@0+ (1,0) [0|15] "SED" Vector__XXX
 SG_ BattChrgRqd_E_Actl : 47|12@0+ (50,0) [0|204650] "watt*hour" Vector__XXX

BO_ 595 APIM_Send_Signals_7: 8 APIM
 SG_ DrvIdMde_D_Rq : 7|3@0+ (1,0) [0|7] "SED"  GWM
 SG_ DrvIdDelete_No_Rq : 15|32@0+ (1,0) [0|4294967295] "Unitless"  GWM

BO_ 596 DrvStat_Data_HS3: 8 GWM
 SG_ DrvIdMde_D_Stat : 2|3@0+ (1,0) [0|7] "SED"  APIM,APIM_CISM
 SG_ DrvIdMatch_No_Actl : 31|32@0+ (1,0) [0|4294967295] "Unitless"  APIM,APIM_CISM
 SG_ DrvIdActn_D_Stat : 7|2@0+ (1,0) [0|3] "SED"  APIM,APIM_CISM
 SG_ DrvId_No_Cs : 23|8@0+ (1,0) [0|255] "unitless"  APIM,APIM_CISM
 SG_ DrvId_D_Stat : 5|3@0+ (1,0) [0|7] "SED"  APIM,APIM_CISM
 SG_ DrvExpression_D_Stat : 15|4@0+ (1,0) [0|15] "SED"  APIM,APIM_CISM

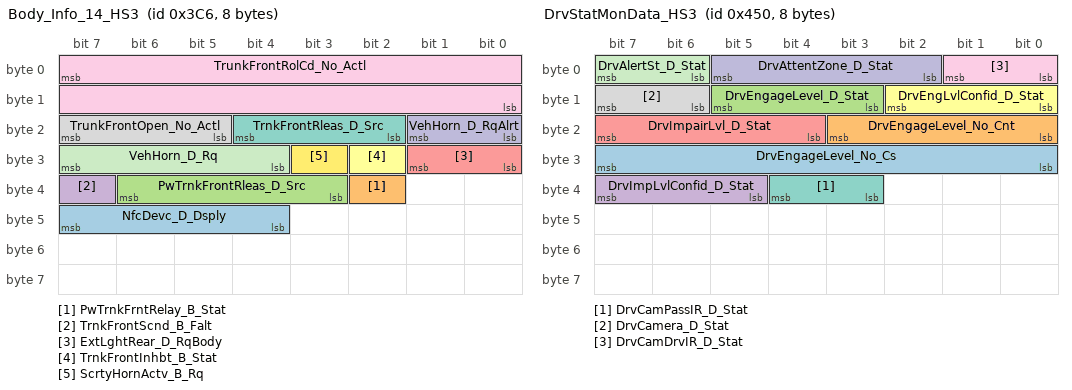
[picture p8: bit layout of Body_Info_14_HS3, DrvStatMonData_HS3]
BO_ 966 Body_Info_14_HS3: 8 GWM
 SG_ NfcDevc_D_Dsply : 47|4@0+ (1,0) [0|15] "SED"  IPC
 SG_ PwTrnkFrntRelay_B_Stat : 34|1@0+ (1,0) [0|1] "SED" Vector__XXX
 SG_ PwTrnkFrontRleas_D_Src : 38|4@0+ (1,0) [0|15] "SED" Vector__XXX
 SG_ TrnkFrontScnd_B_Falt : 39|1@0+ (1,0) [0|1] "SED"  IPC
 SG_ ExtLghtRear_D_RqBody : 25|2@0+ (1,0) [0|3] "SED" Vector__XXX
 SG_ TrnkFrontInhbt_B_Stat : 26|1@0+ (1,0) [0|1] "SED" Vector__XXX
 SG_ TrnkFrontRleas_D_Src : 20|3@0+ (1,0) [0|7] "SED" Vector__XXX
 SG_ TrunkFrontOpen_No_Actl : 23|3@0+ (1,0) [0|7] "unitless" Vector__XXX
 SG_ TrunkFrontRolCd_No_Actl : 7|16@0+ (1,0) [0|65535] "unitless" Vector__XXX
 SG_ VehHorn_D_RqAlrt : 17|2@0+ (1,0) [0|3] "SED" Vector__XXX
 SG_ VehHorn_D_Rq : 31|4@0+ (1,0) [0|15] "SED" Vector__XXX
 SG_ ScrtyHornActv_B_Rq : 27|1@0+ (1,0) [0|1] "SED" Vector__XXX

BO_ 1104 DrvStatMonData_HS3: 8 GWM
 SG_ DrvEngageLevel_No_Cs : 31|8@0+ (1,0) [0|255] "unitless" Vector__XXX
 SG_ DrvEngageLevel_No_Cnt : 19|4@0+ (1,0) [0|15] "unitless" Vector__XXX
 SG_ DrvEngageLevel_D_Stat : 13|3@0+ (1,0) [0|7] "SED" Vector__XXX
 SG_ DrvImpLvlConfid_D_Stat : 39|3@0+ (1,0) [0|7] "SED" Vector__XXX
 SG_ DrvImpairLvl_D_Stat : 23|4@0+ (1,0) [0|15] "SED" Vector__XXX
 SG_ DrvEngLvlConfid_D_Stat : 10|3@0+ (1,0) [0|7] "SED" Vector__XXX
 SG_ DrvCamPassIR_D_Stat : 36|2@0+ (1,0) [0|3] "SED"  APIM,APIM_CISM
 SG_ DrvCamera_D_Stat : 15|2@0+ (1,0) [0|3] "SED"  APIM,APIM_CISM
 SG_ DrvCamDrvIR_D_Stat : 1|2@0+ (1,0) [0|3] "SED"  APIM,APIM_CISM
 SG_ DrvAttentZone_D_Stat : 5|4@0+ (1,0) [0|15] "SED" Vector__XXX
 SG_ DrvAlertSt_D_Stat : 7|2@0+ (1,0) [0|3] "SED" Vector__XXX

BO_ 303 Body_Info_16_HS3: 8 GWM
 SG_ CanMsg12F_No_Crc : 7|8@0+ (1,0) [0|255] "Unitless" Vector__XXX
 SG_ CanMsg12F_No_Cnt : 11|4@0+ (1,0) [0|15] "Unitless" Vector__XXX
 SG_ DrStatHood_D2_Actl : 23|3@0+ (1,0) [0|7] "SED"  IPC

BO_ 2612224006 PARSEDPushHUDtoGWM_ECG: 8 HUD_ADV
 SG_ PARSEDPushHUDtoGWM_ECG : 7|29@0+ (1,0) [0|536870911] "unitless"  GWM

BO_ 2612009176 PARSEDPushFcGWM_ECGtoHUD: 8 GWM
 SG_ PARSEDPushFcGWM_ECGtoHUD : 7|29@0+ (1,0) [0|536870911] "unitless"  HUD_ADV

BO_ 2611175430 PARSEDPhysHUDtoGWM_ECG: 8 HUD_ADV
 SG_ PARSEDPhysHUDtoGWM_ECG : 7|29@0+ (1,0) [0|536870911] "Unitless"  GWM

BO_ 2610960600 PARSEDPhysGWM_ECGtoHUD: 8 GWM
 SG_ PARSEDPhysGWM_ECGtoHUD : 7|29@0+ (1,0) [0|536870911] "unitless"  HUD_ADV

BO_ 2610126854 OTAPhysHUDtoGWM_ECG: 8 HUD_ADV
 SG_ OTAPhysHUDtoGWM_ECG : 7|29@0+ (1,0) [0|536870911] "unitless"  GWM

BO_ 2609912024 OTAPhysGWM_ECGtoHUD: 8 GWM
 SG_ OTAPhysGWM_ECGtoHUD : 7|29@0+ (1,0) [0|536870911] "unitless"  HUD_ADV

BO_ 662 APIM_Send_Signals_6: 8 APIM
 SG_ Third_Rear_Set_Temp : 31|5@0+ (1,0) [0|31] "SED"  GWM
 SG_ Third_Rear_Blower_Speed : 23|4@0+ (1,0) [0|15] "SED"  GWM
 SG_ Rear_Temp : 3|4@0+ (1,0) [0|15] "SED"  GWM
 SG_ Rear_Set_Temp : 15|5@0+ (1,0) [0|31] "SED"  GWM
 SG_ Rear_Blower_Speed : 7|4@0+ (1,0) [0|15] "SED"  GWM
 SG_ Running_Board_Cmd2 : 10|2@0+ (1,0) [0|3] "SED"  GWM

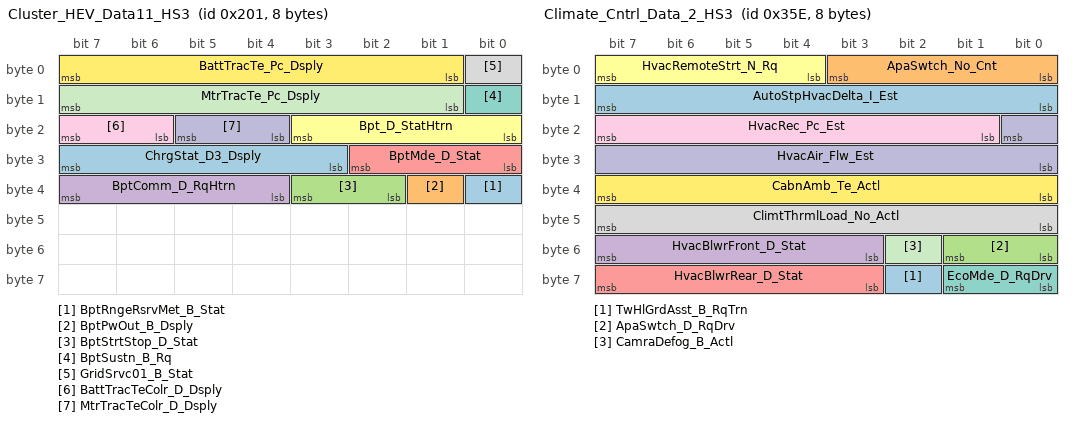
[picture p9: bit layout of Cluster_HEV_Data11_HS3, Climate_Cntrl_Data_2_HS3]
BO_ 513 Cluster_HEV_Data11_HS3: 8 GWM
 SG_ BptRngeRsrvMet_B_Stat : 32|1@0+ (1,0) [0|1] "SED"  APIM,APIM_CISM
 SG_ BptPwOut_B_Dsply : 33|1@0+ (1,0) [0|1] "SED"  APIM,APIM_CISM
 SG_ BptStrtStop_D_Stat : 35|2@0+ (1,0) [0|3] "SED"  APIM,APIM_CISM
 SG_ BptComm_D_RqHtrn : 39|4@0+ (1,0) [0|15] "SED"  APIM,APIM_CISM
 SG_ BptMde_D_Stat : 26|3@0+ (1,0) [0|7] "SED"  APIM,APIM_CISM
 SG_ Bpt_D_StatHtrn : 19|4@0+ (1,0) [0|15] "SED"  APIM,APIM_CISM
 SG_ BptSustn_B_Rq : 8|1@0+ (1,0) [0|1] "SED"  APIM,APIM_CISM
 SG_ GridSrvc01_B_Stat : 0|1@0+ (1,0) [0|1] "SED"  APIM,APIM_CISM
 SG_ BattTracTeColr_D_Dsply : 23|2@0+ (1,0) [0|3] "SED"  IPC
 SG_ MtrTracTeColr_D_Dsply : 21|2@0+ (1,0) [0|3] "SED"  IPC
 SG_ MtrTracTe_Pc_Dsply : 15|7@0+ (1,0) [0|127] "percent"  IPC
 SG_ BattTracTe_Pc_Dsply : 7|7@0+ (1,0) [0|127] "percent"  IPC
 SG_ ChrgStat_D3_Dsply : 31|5@0+ (1,0) [0|31] "SED"  APIM,IPC,APIM_CISM

BO_ 148 Yaw_Data_HS3: 8 GWM
 SG_ VehYawWActl_D_Qf : 53|2@0+ (1,0) [0|3] "SED" Vector__XXX
 SG_ VehRolWActl_D_Qf : 55|2@0+ (1,0) [0|3] "SED" Vector__XXX
 SG_ VehRollYawW_No_Cs : 39|8@0+ (1,0) [0|255] "unitless" Vector__XXX
 SG_ VehRollYaw_No_Cnt : 47|8@0+ (1,0) [0|255] "unitless" Vector__XXX
 SG_ VehYaw_W_Actl : 23|16@0+ (0.0002,-6.5) [-6.5|6.6066] "rad/s"  APIM,APIM_CISM,ACM
 SG_ VehRol_W_Actl : 7|16@0+ (0.0002,-6.5) [-6.5|6.6066] "rad/s" Vector__XXX

BO_ 1042 TrailerBrakeData_HS3: 8 GWM
 SG_ VehRol_An_Dsply : 31|7@0+ (1,-64) [-64|61] "degrees"  APIM,APIM_CISM,IPC
 SG_ RearDiffLck_Tq_RqMn : 39|12@0+ (4,0) [0|16376] "Nm" Vector__XXX
 SG_ VehPtch_An_Dsply : 23|7@0+ (1,-64) [-64|61] "degrees"  APIM,APIM_CISM,IPC
 SG_ TrlrBrk_Pc_Rq : 14|7@0+ (1,0) [0|127] "percent"  TRM_ITRM,IPC

BO_ 828 Pass_Window_Stat_HS3: 8 GWM
 SG_ DrvSpotLight_B_Rq : 15|1@0+ (1,0) [0|1] "SED" Vector__XXX
 SG_ SpotLghtRight_D_Stat : 0|1@0+ (1,0) [0|1] "SED"  APIM,APIM_CISM
 SG_ RearPassWindowPos : 4|3@0+ (1,0) [0|7] "SED"  APIM,APIM_CISM,ACM,WCM
 SG_ PassWindowPosition : 7|3@0+ (1,0) [0|7] "SED"  APIM,APIM_CISM,ACM,WCM
 SG_ SpotLghtLeft_D_Stat : 1|1@0+ (1,0) [0|1] "SED"  APIM,APIM_CISM

BO_ 330 TransData_3_HS3: 8 GWM
 SG_ TrnFaltOpenClu_B_Stat : 5|1@0+ (1,0) [0|1] "SED" Vector__XXX
 SG_ TrnAout_W_ActlUnfilt : 22|15@0+ (0.1,0) [0|3276.5] "rad/s"  APIM_CISM,ACM

BO_ 512 TorqueDataEngFlags_HS3: 8 GWM
 SG_ PtDrvMde_D_Stat : 55|4@0+ (1,0) [0|15] "SED"  APIM_CISM,ACM,IPC
 SG_ PrplWhlTotTqRq_No_Cs : 63|8@0+ (1,0) [0|255] "unitless" Vector__XXX
 SG_ PrplWhlTotTqRq_No_Cnt : 51|4@0+ (1,0) [0|15] "unitless" Vector__XXX
 SG_ EngAout_Tq_MxMxN : 2|11@0+ (1,-500) [-500|1547] "Nm" Vector__XXX
 SG_ PrplWhlTot_Tq_Rq : 39|16@0+ (4,-131072) [-131072|131068] "Nm" Vector__XXX
 SG_ PrplWhlTot_Tq_LimMn : 23|16@0+ (4,-131072) [-131072|131068] "Nm" Vector__XXX

BO_ 862 Climate_Cntrl_Data_2_HS3: 8 GWM
 SG_ TwHlGrdAsst_B_RqTrn : 58|1@0+ (1,0) [0|1] "SED" Vector__XXX
 SG_ ApaSwtch_No_Cnt : 3|4@0+ (1,0) [0|15] "unitless" Vector__XXX
 SG_ ApaSwtch_D_RqDrv : 49|2@0+ (1,0) [0|3] "SED" Vector__XXX
 SG_ HvacBlwrFront_D_Stat : 55|5@0+ (1,0) [0|31] "SED"  APIM,APIM_CISM,WCM
 SG_ HvacBlwrRear_D_Stat : 63|5@0+ (1,0) [0|31] "SED"  APIM,APIM_CISM,WCM
 SG_ HvacRemoteStrt_N_Rq : 7|4@0+ (100,450) [450|1950] "RPM" Vector__XXX
 SG_ EcoMde_D_RqDrv : 57|2@0+ (1,0) [0|3] "SED" Vector__XXX
 SG_ ClimtThrmlLoad_No_Actl : 47|8@0+ (1,0) [0|254] "unitless" Vector__XXX
 SG_ HvacRec_Pc_Est : 23|7@0+ (1,0) [0|127] "percent" Vector__XXX
 SG_ HvacAir_Flw_Est : 16|9@0+ (0.5,0) [0|255.5] "liter/second" Vector__XXX
 SG_ CamraDefog_B_Actl : 50|1@0+ (1,0) [0|1] "SED" Vector__XXX
 SG_ CabnAmb_Te_Actl : 39|8@0+ (0.5,-57) [-57|70] "degC"  APIM,APIM_CISM,GWM,ACM,WCM
 SG_ AutoStpHvacDelta_I_Est : 15|8@0+ (1,-192) [-192|62] "ampere" Vector__XXX

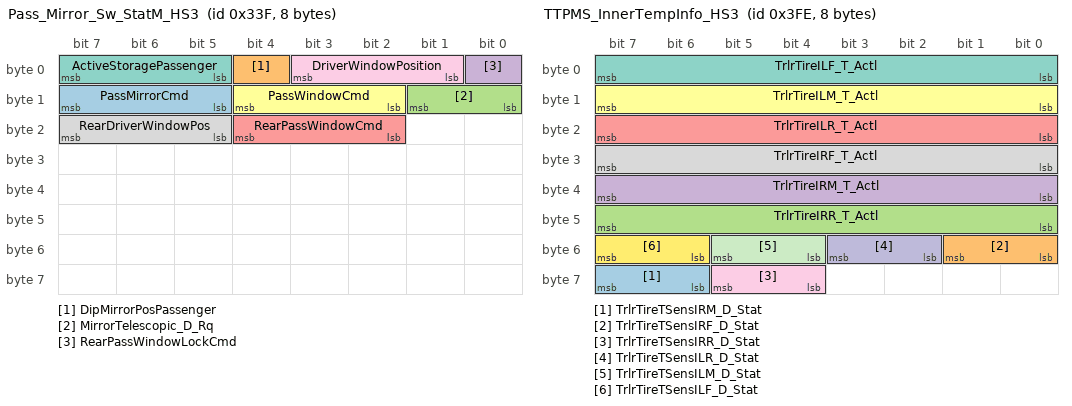
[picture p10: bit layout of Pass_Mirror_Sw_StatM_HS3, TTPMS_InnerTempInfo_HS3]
BO_ 831 Pass_Mirror_Sw_StatM_HS3: 8 GWM
 SG_ PassMirrorCmd : 15|3@0+ (1,0) [0|7] "SED" Vector__XXX
 SG_ DipMirrorPosPassenger : 4|1@0+ (1,0) [0|1] "SED" Vector__XXX
 SG_ MirrorTelescopic_D_Rq : 9|2@0+ (1,0) [0|3] "SED" Vector__XXX
 SG_ RearPassWindowLockCmd : 0|1@0+ (1,0) [0|1] "SED" Vector__XXX
 SG_ RearPassWindowCmd : 20|3@0+ (1,0) [0|7] "SED" Vector__XXX
 SG_ PassWindowCmd : 12|3@0+ (1,0) [0|7] "SED" Vector__XXX
 SG_ ActiveStoragePassenger : 7|3@0+ (1,0) [0|7] "SED" Vector__XXX
 SG_ RearDriverWindowPos : 23|3@0+ (1,0) [0|7] "SED"  APIM,APIM_CISM,ACM,WCM
 SG_ DriverWindowPosition : 3|3@0+ (1,0) [0|7] "SED"  APIM,APIM_CISM,ACM,WCM

BO_ 331 HEV_Powertrain_Data5_HS3: 8 GWM
 SG_ TrnAout2ActUflt_No_Cnt : 15|4@0+ (1,0) [0|15] "unitless" Vector__XXX
 SG_ TrnAout2ActlUflt_No_Cs : 7|8@0+ (1,0) [0|255] "unitless" Vector__XXX
 SG_ TrnAout2_W_ActlUnfilt : 23|16@0+ (0.1,-3276.5) [-3276.5|3276.8] "rad/s"  APIM_CISM,ACM
 SG_ HtrnAin_N_RqMnPrtct : 36|13@0+ (2,0) [0|16382] "RPM" Vector__XXX
 SG_ CmbbEngTqMn_B_ActlHtrn : 37|1@0+ (1,0) [0|1] "SED" Vector__XXX
 SG_ CmbbDeny_B_ActlHtrn : 38|1@0+ (1,0) [0|1] "SED" Vector__XXX

BO_ 965 FrontTrunk_Data_HS3: 8 GWM
 SG_ TrnkFrontPrim_B_Falt : 18|1@0+ (1,0) [0|1] "SED"  IPC
 SG_ TrnkFrontEmgcy_D_Stat : 20|2@0+ (1,0) [0|0] "SED"  IPC
 SG_ PtWakeupActv4_B_Rq : 21|1@0+ (1,0) [0|1] "SED" Vector__XXX
 SG_ TrunkFrontOpen_D_Stat : 23|2@0+ (1,0) [0|3] "SED"  APIM,APIM_CISM
 SG_ TrunkFrontRolCd_No_Locl : 7|16@0+ (1,0) [0|65535] "unitless" Vector__XXX

BO_ 1242 PowertrainCstmData_HS3: 8 GWM
 SG_ EngExhMdeQuietCstm_D_Rq : 7|3@0+ (1,0) [0|7] "SED"  IPC
 SG_ StopStrtCstm_D_Rq : 15|2@0+ (1,0) [0|3] "SED"  IPC
 SG_ SelDrvMdeCstmPt_D_Rq : 4|5@0+ (1,0) [0|31] "SED" Vector__XXX

BO_ 1245 DrivelineCstmFeatures_HS3: 8 GWM
 SG_ RearDiffLckLamp_D_Cstm : 13|2@0+ (1,0) [0|3] "SED"  IPC
 SG_ FrontDiffLckLamp_D_Cstm : 15|2@0+ (1,0) [0|3] "SED"  IPC
 SG_ AwdMdeCstm_D_RqDrv : 7|3@0+ (1,0) [0|7] "SED"  IPC
 SG_ SelDrvMdeAwd2_D_Cstm : 4|5@0+ (1,0) [0|31] "SED" Vector__XXX

BO_ 781 TrailerTire_Status_HS3: 8 GWM
 SG_ TrlrTireDual_D_Stat : 31|4@0+ (1,0) [0|15] "SED"  APIM,APIM_CISM,IPC
 SG_ TrlrTireThresh_D_Stat : 7|8@0+ (1,0) [0|255] "unitless"  APIM,APIM_CISM,IPC
 SG_ TrlrTireSys_D_Stat : 15|4@0+ (1,0) [0|15] "SED"  APIM,APIM_CISM,IPC
 SG_ TrlrTireCnt_D_Stat : 23|3@0+ (1,0) [0|6] "SED"  APIM,APIM_CISM,IPC
 SG_ ChirpRq_No_ActlTrlr : 11|4@0+ (1,0) [0|15] "unitless"  APIM_CISM,IPC
 SG_ Chirp_D_RqTrlr : 20|2@0+ (1,0) [0|3] "SED"  APIM_CISM,IPC

BO_ 1022 TTPMS_InnerTempInfo_HS3: 8 GWM
 SG_ TrlrTireTSensIRM_D_Stat : 63|2@0+ (1,0) [0|3] "SED"  APIM,APIM_CISM,IPC
 SG_ TrlrTireTSensIRF_D_Stat : 49|2@0+ (1,0) [0|3] "SED"  APIM,APIM_CISM,IPC
 SG_ TrlrTireIRR_T_Actl : 47|8@0+ (1,-60) [-60|193] "degC"  APIM,APIM_CISM,IPC
 SG_ TrlrTireIRM_T_Actl : 39|8@0+ (1,-60) [-60|193] "degC"  APIM,APIM_CISM,IPC
 SG_ TrlrTireILR_T_Actl : 23|8@0+ (1,-60) [-60|193] "degC"  APIM,APIM_CISM,IPC
 SG_ TrlrTireILM_T_Actl : 15|8@0+ (1,-60) [-60|193] "degC"  APIM,APIM_CISM,IPC
 SG_ TrlrTireILF_T_Actl : 7|8@0+ (1,-60) [-60|193] "degC"  APIM,APIM_CISM,IPC
 SG_ TrlrTireIRF_T_Actl : 31|8@0+ (1,-60) [-60|193] "degC"  APIM,APIM_CISM,IPC
 SG_ TrlrTireTSensIRR_D_Stat : 61|2@0+ (1,0) [0|3] "SED"  APIM,APIM_CISM,IPC
 SG_ TrlrTireTSensILR_D_Stat : 51|2@0+ (1,0) [0|3] "SED"  APIM,APIM_CISM,IPC
 SG_ TrlrTireTSensILM_D_Stat : 53|2@0+ (1,0) [0|3] "SED"  APIM,APIM_CISM,IPC
 SG_ TrlrTireTSensILF_D_Stat : 55|2@0+ (1,0) [0|3] "SED"  APIM,APIM_CISM,IPC

BO_ 903 Av_RDAPM_Data2_HS3: 8 GWM
 SG_ AprSnd_D_Rq : 7|6@0+ (1,0) [0|63] "SED"  APIM,APIM_CISM

BO_ 901 Av_LDAPM_Data2_HS3: 8 GWM
 SG_ AplSnd_D_Rq : 7|6@0+ (1,0) [0|63] "SED"  APIM,APIM_CISM

BO_ 1112 Battery_Traction_6_HS3: 8 GWM
 SG_ BattTracIsoDis_B_Stat : 0|1@0+ (1,0) [0|1] "SED" Vector__XXX
 SG_ BattTrac2_E_Max : 47|12@0+ (50,0) [0|204650] "watt*hour"  APIM,APIM_CISM
 SG_ BattTracHeat_D_Rq : 35|2@0+ (1,0) [0|3] "SED" Vector__XXX
 SG_ BattTracDcFstSustn_B_Rq : 51|1@0+ (1,0) [0|1] "SED" Vector__XXX
 SG_ BattDcCnnct_D_Cmd : 14|3@0+ (1,0) [0|7] "SED" Vector__XXX
 SG_ BattTrac2_E_Avail : 31|12@0+ (50,0) [0|204650] "watt*hour"  APIM,APIM_CISM
 SG_ BattTracCnnct_D_Cmd : 18|3@0+ (1,0) [0|7] "SED" Vector__XXX
 SG_ BattTracHvilOpen_B_Stat : 8|1@0+ (1,0) [0|1] "SED" Vector__XXX
 SG_ BattTracCoolLvl_D_Rq : 11|3@0+ (1,0) [0|7] "SED" Vector__XXX
 SG_ CoolFanBatt_D_Rq : 23|5@0+ (1,0) [0|31] "unitless" Vector__XXX
 SG_ BattTracTeSustn_B_Rq : 1|1@0+ (1,0) [0|1] "SED" Vector__XXX
 SG_ BattTracTeEvnt_B_Stat : 2|1@0+ (1,0) [0|1] "SED" Vector__XXX
 SG_ BattTracDcdcDis_B_Rq : 7|1@0+ (1,0) [0|1] "SED" Vector__XXX
 SG_ BattChrgTrgtEvnt_B_Stat : 3|1@0+ (1,0) [0|1] "SED" Vector__XXX
 SG_ BattTracDiagClr_B_Rq : 15|1@0+ (1,0) [0|1] "SED" Vector__XXX
 SG_ BattTracChrgSustn_B_Rq : 4|1@0+ (1,0) [0|1] "SED" Vector__XXX
 SG_ HtrnClntPump_D_Stat : 6|2@0+ (1,0) [0|3] "SED" Vector__XXX
 SG_ BattTracDelta_Te_Actl : 63|8@0+ (0.5,-60) [-60|66.5] "degC" Vector__XXX
 SG_ BattTracClntPmp_D_Stat : 33|2@0+ (1,0) [0|3] "SED" Vector__XXX
 SG_ BattTracHazrd_D_Stat : 50|3@0+ (1,0) [0|7] "SED"  IPC

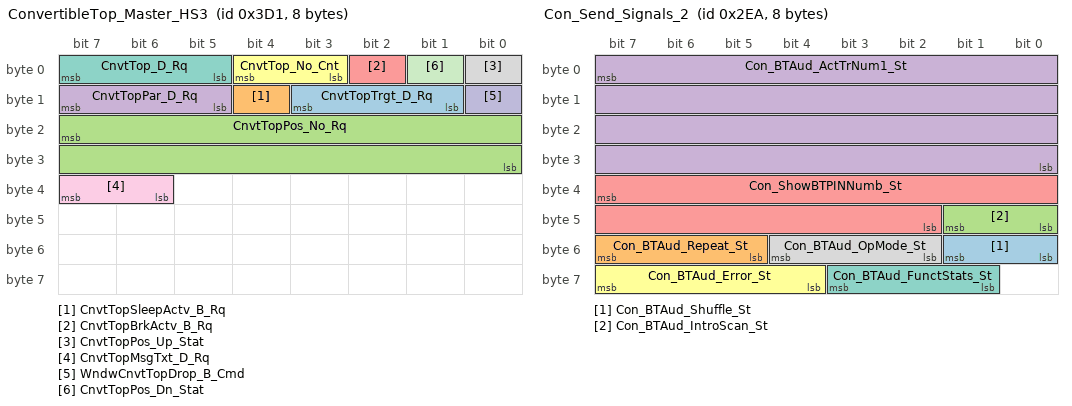
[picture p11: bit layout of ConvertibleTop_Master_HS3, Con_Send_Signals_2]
BO_ 977 ConvertibleTop_Master_HS3: 8 GWM
 SG_ CnvtTopTrgt_D_Rq : 11|3@0+ (1,0) [0|7] "SED" Vector__XXX
 SG_ CnvtTopSleepActv_B_Rq : 12|1@0+ (1,0) [0|1] "SED" Vector__XXX
 SG_ CnvtTopPos_No_Rq : 23|16@0+ (1,0) [0|65535] "unitless" Vector__XXX
 SG_ CnvtTopPar_D_Rq : 15|3@0+ (1,0) [0|7] "SED" Vector__XXX
 SG_ CnvtTopBrkActv_B_Rq : 2|1@0+ (1,0) [0|1] "SED" Vector__XXX
 SG_ CnvtTop_No_Cnt : 4|2@0+ (1,0) [0|3] "unitless" Vector__XXX
 SG_ CnvtTop_D_Rq : 7|3@0+ (1,0) [0|7] "SED" Vector__XXX
 SG_ CnvtTopPos_Up_Stat : 0|1@0+ (1,0) [0|1] "SED"  APIM_CISM,ACM,DSP
 SG_ CnvtTopMsgTxt_D_Rq : 39|2@0+ (1,0) [0|3] "SED"  IPC
 SG_ WndwCnvtTopDrop_B_Cmd : 8|1@0+ (1,0) [0|1] "SED" Vector__XXX
 SG_ CnvtTopPos_Dn_Stat : 1|1@0+ (1,0) [0|1] "SED"  APIM_CISM,ACM

BO_ 530 APIM_Request_Signals_6: 8 APIM
 SG_ PiCode_No_Rq : 39|16@0+ (1,0) [0|65535] "unitless"  ACM
 SG_ StationTypeSel_D_Rq : 61|2@0+ (1,0) [0|3] "SED"  ACM
 SG_ DabExtndCntryCode_No_Rq : 55|8@0+ (1,0) [0|255] "unitless"  ACM
 SG_ DabStationCodeId_No_Rq : 23|16@0+ (1,0) [0|65535] "unitless"  ACM
 SG_ DabStationId_No_Rq : 7|16@0+ (1,0) [0|65535] "unitless"  ACM

BO_ 746 Con_Send_Signals_2: 8 ACM
 SG_ Con_BTAud_Shuffle_St : 49|2@0+ (1,0) [0|3] "SED"  IPC
 SG_ Con_BTAud_Repeat_St : 55|3@0+ (1,0) [0|7] "SED"  IPC
 SG_ Con_BTAud_IntroScan_St : 41|2@0+ (1,0) [0|3] "SED"  IPC
 SG_ Con_BTAud_ActTrNum1_St : 7|32@0+ (1,0) [0|4294967295] "unitless"  IPC
 SG_ Con_ShowBTPINNumb_St : 39|14@0+ (1,0) [0|16383] "unitless"  IPC
 SG_ Con_BTAud_Error_St : 63|4@0+ (1,0) [0|15] "SED"  IPC
 SG_ Con_BTAud_FunctStats_St : 59|3@0+ (1,0) [0|7] "SED"  IPC
 SG_ Con_BTAud_OpMode_St : 52|3@0+ (1,0) [0|7] "SED"  IPC

BO_ 479 DISP_Request_Sig: 8 APIM
 SG_ DISP_SetVolume_Rq : 5|6@0+ (1,-30) [-30|33] "steps"  DSP,ACM,GWM
 SG_ DISP_SetVol_Source_Rq : 19|4@0+ (1,0) [0|15] "SED"  IPC,DSP,ACM,GWM
 SG_ DISP_SetVol_Level_Rq : 13|6@0+ (1,0) [0|63] "unitless"  DSP,GWM,ACM
 SG_ DISP_Setshaker_Rq : 21|2@0+ (1,0) [0|3] "SED"  DSP,GWM,ACM

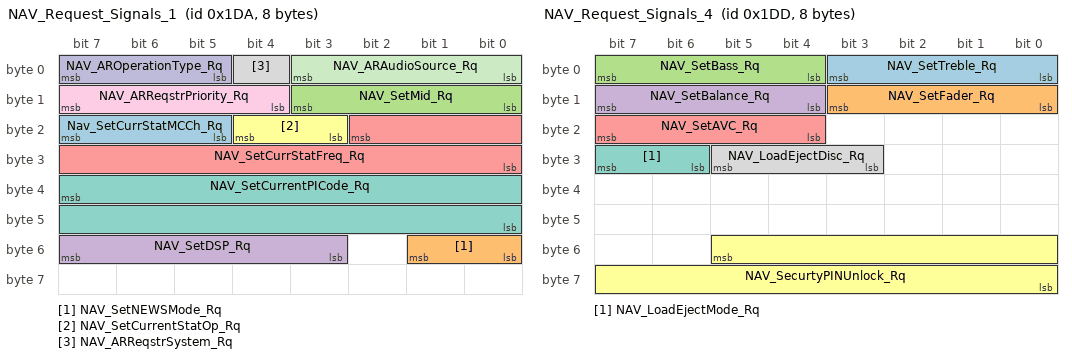
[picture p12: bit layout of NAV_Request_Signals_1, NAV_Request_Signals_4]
BO_ 474 NAV_Request_Signals_1: 8 APIM
 SG_ Nav_SetCurrStatMCCh_Rq : 23|3@0+ (1,0) [0|7] "SED"  ACM
 SG_ NAV_SetNEWSMode_Rq : 49|2@0+ (1,0) [0|3] "SED"  ACM
 SG_ NAV_SetMid_Rq : 11|4@0+ (1,-7) [-7|8] "SED"  DSP,ACM
 SG_ NAV_SetDSP_Rq : 55|5@0+ (1,0) [0|31] "SED"  ACM
 SG_ NAV_SetCurrStatFreq_Rq : 18|11@0+ (1,0) [0|1557] "unitless"  ACM
 SG_ NAV_SetCurrentStatOp_Rq : 20|2@0+ (1,0) [0|3] "SED"  ACM
 SG_ NAV_SetCurrentPICode_Rq : 39|16@0+ (1,0) [0|65535] "unitless"  ACM
 SG_ NAV_ARReqstrSystem_Rq : 4|1@0+ (1,0) [0|1] "SED"  DSP,ACM
 SG_ NAV_ARReqstrPriority_Rq : 15|4@0+ (1,0) [0|15] "SED"  DSP,ACM
 SG_ NAV_AROperationType_Rq : 7|3@0+ (1,0) [0|7] "SED"  DSP,ACM
 SG_ NAV_ARAudioSource_Rq : 3|4@0+ (1,0) [0|15] "SED"  DSP,ACM

BO_ 477 NAV_Request_Signals_4: 8 APIM
 SG_ NAV_SetTreble_Rq : 3|4@0+ (1,-7) [-7|8] "SED"  ACM,DSP
 SG_ NAV_SetFader_Rq : 11|4@0+ (1,-7) [-7|8] "SED"  ACM,DSP
 SG_ NAV_SetBass_Rq : 7|4@0+ (1,-7) [-7|8] "SED"  ACM,DSP
 SG_ NAV_SetBalance_Rq : 15|4@0+ (1,-7) [-7|8] "SED"  ACM,DSP
 SG_ NAV_SetAVC_Rq : 23|4@0+ (1,0) [0|15] "SED"  ACM,DSP
 SG_ NAV_SecurtyPINUnlock_Rq : 53|14@0+ (1,0) [0|16383] "unitless"  ACM
 SG_ NAV_LoadEjectMode_Rq : 31|2@0+ (1,0) [0|3] "SED"  ACM
 SG_ NAV_LoadEjectDisc_Rq : 29|3@0+ (1,0) [0|7] "SED"  ACM

BO_ 260 MFD_Request_Signals3: 8 APIM
 SG_ MFD_SDARS_SetOpMode_Rq : 23|3@0+ (1,0) [0|7] "SED"  ACM
 SG_ MFD_SDARS_DirectTune_Rq : 31|8@0+ (1,0) [0|255] "unitless"  ACM
 SG_ SDARS_GetESN_Rq : 47|1@0+ (1,0) [0|1] "SED"  ACM
 SG_ SDARS_SRReplay_Rq : 15|2@0+ (1,0) [0|3] "SED"  ACM
 SG_ SDARS_SelectCategory_Rq : 7|8@0+ (1,0) [0|255] "unitless"  ACM
 SG_ SDARS_InfoRefChanNum_Rq : 55|8@0+ (1,0) [0|255] "unitless"  ACM
 SG_ SDARS_FactoryReset_Rq : 39|2@0+ (1,0) [0|3] "SED"  DSP,ACM

BO_ 476 NAV_Request_Signals_3: 8 APIM
 SG_ Nav_SetAudioMixRatio_Rq : 31|5@0+ (1,0) [0|20] "decibel"  ACM
 SG_ NAV_SkipCatalouge_Rq : 7|2@0+ (1,0) [0|3] "SED"  ACM
 SG_ NAV_SetOperationMode_Rq : 26|3@0+ (1,0) [0|7] "SED"  ACM
 SG_ NAV_SetDSPProgram_Rq : 13|3@0+ (1,0) [0|7] "SED"  ACM

BO_ 490 HMI_Request_Signals_2: 8 APIM
 SG_ HMI_SetCompression_Rq : 9|2@0+ (1,0) [0|3] "SED"  APIM,ACM
 SG_ HMI_SkipTrack_Rq : 35|2@0+ (1,0) [0|3] "SED"  ACM

BO_ 1916 TesterPhysicalResRACM: 8 RACM_RCIM
 SG_ TesterPhysicalResRACM : 7|64@0+ (1,0) [0|1.84467E+019] "unitless"  TSTR

BO_ 1908 TesterPhysicalReqRACM: 8 TSTR
 SG_ TesterPhysicalReqRACM : 7|64@0+ (1,0) [0|1.84467E+019] "unitless"  RACM_RCIM

BO_ 1432 RACM_AutoSar_Network_Mgmt: 8 RACM_RCIM
 SG_ RACM_GWOnBoardTester : 39|8@0+ (1,0) [0|255] "unitless"  GWM
 SG_ RACM_GWNMProxy : 47|8@0+ (1,0) [0|255] "unitless"  GWM
 SG_ RACM_AutoSarNMReserved4 : 63|8@0+ (1,0) [0|255] "unitless"  GWM
 SG_ RACM_AutoSarNMReserved3 : 55|8@0+ (1,0) [0|255] "unitless"  GWM
 SG_ RACM_AutoSarNMReserved2 : 31|8@0+ (1,0) [0|255] "unitless"  GWM
 SG_ RACM_AutoSarNMReserved1 : 23|8@0+ (1,0) [0|255] "unitless"  GWM
 SG_ RACM_AutoSarNMNodeId : 7|8@0+ (1,0) [0|255] "unitless"  GWM
 SG_ RACM_AutoSarNMControl : 15|8@0+ (1,0) [0|255] "unitless"  GWM

BO_ 1923 TesterPhysicalReqDSP: 8 TSTR
 SG_ TesterPhysicalReqDSP : 7|64@0+ (1,0) [0|1.84467E+019] "unitless"  DSP

BO_ 1931 TesterPhysicalResDSP: 8 DSP
 SG_ TesterPhysicalResDSP : 7|64@0+ (1,0) [0|1.84467E+019] "unitless"  TSTR

BO_ 896 TripInfo_Data_HS3: 8 GWM
 SG_ BptDly_T_Actl : 55|6@0+ (0.5,0) [0|30.5] "minute"  APIM,APIM_CISM
 SG_ VehElAvgTrip1_Eff_Dsply : 47|7@0+ (10,-100) [-100|1150] "wattHr/km"  APIM,IPC,APIM_CISM
 SG_ Trip1SumDrvE_Pc_Dsply : 25|10@0+ (0.1,0) [0|102.1] "percent"  APIM,APIM_CISM
 SG_ Trip1ExtFctrE_Pc_Dsply : 19|10@0+ (0.1,0) [0|102.1] "percent"  APIM,APIM_CISM
 SG_ Trip1ClimE_Pc_Dsply : 13|10@0+ (0.1,0) [0|102.1] "percent"  APIM,APIM_CISM
 SG_ Trip1BattULoE_Pc_Dsply : 7|10@0+ (0.1,0) [0|102.1] "percent"  APIM,APIM_CISM

BO_ 897 TripInfo_Data2_HS3: 8 GWM
 SG_ VehElAvgTrip2_Eff_Dsply : 47|7@0+ (10,-100) [-100|1150] "wattHr/km"  APIM,IPC,APIM_CISM
 SG_ Trip2SumDrvE_Pc_Dsply : 25|10@0+ (0.1,0) [0|102.1] "percent"  APIM,APIM_CISM
 SG_ Trip2ExtFctrE_Pc_Dsply : 19|10@0+ (0.1,0) [0|102.1] "percent"  APIM,APIM_CISM
 SG_ Trip2ClimE_Pc_Dsply : 13|10@0+ (0.1,0) [0|102.1] "percent"  APIM,APIM_CISM
 SG_ Trip2BattULoE_Pc_Dsply : 7|10@0+ (0.1,0) [0|102.1] "percent"  APIM,APIM_CISM

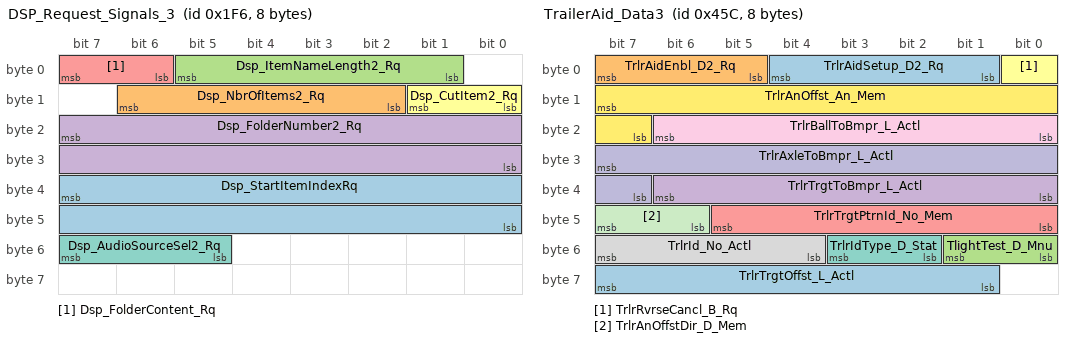
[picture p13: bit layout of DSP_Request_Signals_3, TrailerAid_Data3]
BO_ 502 DSP_Request_Signals_3: 8 APIM
 SG_ Dsp_StartItemIndexRq : 39|16@0+ (1,0) [0|65535] "unitless"  ACM
 SG_ Dsp_NbrOfItems2_Rq : 14|5@0+ (1,0) [0|20] "SED"  ACM
 SG_ Dsp_ItemNameLength2_Rq : 5|5@0+ (1,0) [0|20] "SED"  ACM
 SG_ Dsp_FolderNumber2_Rq : 23|16@0+ (1,0) [0|65535] "unitless"  ACM
 SG_ Dsp_FolderContent_Rq : 7|2@0+ (1,0) [0|3] "SED"  ACM
 SG_ Dsp_CutItem2_Rq : 9|2@0+ (1,0) [0|3] "SED"  ACM
 SG_ Dsp_AudioSourceSel2_Rq : 55|3@0+ (1,0) [0|7] "SED"  ACM

BO_ 955 Tire_Temp_Data_HS3: 8 GWM
 SG_ Tire_Temp_RF_Data : 47|8@0+ (1,-60) [-60|193] "degC"  APIM,APIM_CISM,IPC
 SG_ Tire_Temp_ORR_Data : 39|8@0+ (1,-60) [-60|193] "degC"  APIM,APIM_CISM,IPC
 SG_ Tire_Temp_OLR_Data : 31|8@0+ (1,-60) [-60|193] "degC"  APIM,APIM_CISM,IPC
 SG_ Tire_Temp_LF_Data : 23|8@0+ (1,-60) [-60|193] "degC"  APIM,APIM_CISM,IPC
 SG_ Tire_Temp_IRR_Data : 15|8@0+ (1,-60) [-60|193] "degC"  APIM,APIM_CISM,IPC
 SG_ Tire_Temp_ILR_Data : 7|8@0+ (1,-60) [-60|193] "degC"  APIM,APIM_CISM,IPC

BO_ 1116 TrailerAid_Data3: 8 APIM
 SG_ TrlrAidSetup_D2_Rq : 4|4@0+ (1,0) [0|15] "SED"  GWM
 SG_ TrlrAidEnbl_D2_Rq : 7|3@0+ (1,0) [0|7] "SED"  GWM
 SG_ TlightTest_D_Mnu : 49|2@0+ (1,0) [0|3] "SED"  GWM
 SG_ TrlrTrgtToBmpr_L_Actl : 38|7@0+ (0.0127,0) [0|1.6129] "meter"  GWM
 SG_ TrlrTrgtPtrnId_No_Mem : 45|6@0+ (1,0) [0|63] "unitless"  GWM
 SG_ TrlrRvrseCancl_B_Rq : 0|1@0+ (1,0) [0|1] "SED"  GWM
 SG_ TrlrIdType_D_Stat : 51|2@0+ (1,0) [0|3] "SED"  GWM
 SG_ TrlrId_No_Actl : 55|4@0+ (1,0) [0|15] "unitless"  GWM
 SG_ TrlrBallToBmpr_L_Actl : 22|7@0+ (0.0127,0) [0|1.6129] "meter"  GWM
 SG_ TrlrAxleToBmpr_L_Actl : 31|9@0+ (0.0254,0) [0|12.9794] "meter"  GWM
 SG_ TrlrAnOffstDir_D_Mem : 47|2@0+ (1,0) [0|3] "SED"  GWM
 SG_ TrlrAnOffst_An_Mem : 15|9@0+ (0.1,0) [0|51.1] "degrees"  GWM
 SG_ TrlrTrgtOffst_L_Actl : 63|7@0+ (0.0127,0) [0|1.6129] "meter"  GWM

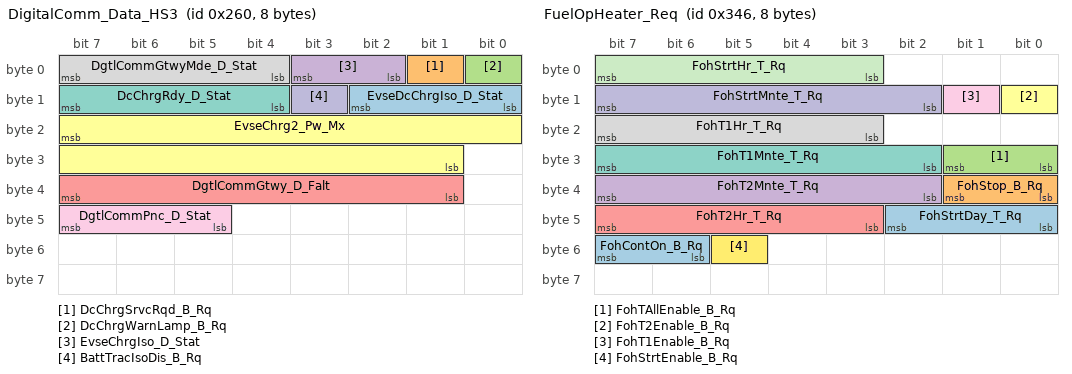
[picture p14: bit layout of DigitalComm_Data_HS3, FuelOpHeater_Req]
BO_ 608 DigitalComm_Data_HS3: 8 GWM
 SG_ EvseDcChrgIso_D_Stat : 10|3@0+ (1,0) [0|7] "SED" Vector__XXX
 SG_ DcChrgSrvcRqd_B_Rq : 1|1@0+ (1,0) [0|1] "SED"  IPC
 SG_ DcChrgWarnLamp_B_Rq : 0|1@0+ (1,0) [0|1] "SED" Vector__XXX
 SG_ EvseChrgIso_D_Stat : 3|2@0+ (1,0) [0|3] "SED" Vector__XXX
 SG_ DgtlCommGtwy_D_Falt : 39|7@0+ (1,0) [0|63] "SED" Vector__XXX
 SG_ EvseChrg2_Pw_Mx : 23|15@0+ (50,0) [0|1638250] "watts" Vector__XXX
 SG_ DcChrgRdy_D_Stat : 15|4@0+ (1,0) [0|15] "SED" Vector__XXX
 SG_ DgtlCommGtwyMde_D_Stat : 7|4@0+ (1,0) [0|15] "SED" Vector__XXX
 SG_ DgtlCommPnc_D_Stat : 47|3@0+ (1,0) [0|7] "SED" Vector__XXX
 SG_ BattTracIsoDis_B_Rq : 11|1@0+ (1,0) [0|1] "SED" Vector__XXX

BO_ 1237 Active_Park_Assist3_HS3: 8 GWM
 SG_ ApaSlotRef2Y_L_Actl : 31|11@0+ (0.02,-20.96) [-20.96|19.98] "meter"  APIM,APIM_CISM
 SG_ ApaSlotRef2X_L_Actl : 12|11@0+ (0.02,-20.96) [-20.96|19.98] "meter"  APIM,APIM_CISM
 SG_ ApaSlotRef1Y_L_Actl : 36|11@0+ (0.02,-20.96) [-20.96|19.98] "meter"  APIM,APIM_CISM
 SG_ ApaSlotRef1X_L_Actl : 7|11@0+ (0.02,-20.96) [-20.96|19.98] "meter"  APIM,APIM_CISM

BO_ 838 FuelOpHeater_Req: 8 IPC
 SG_ FohStrtDay_T_Rq : 42|3@0+ (1,0) [0|7] "SED"  GWM
 SG_ FohStop_B_Rq : 33|2@0+ (1,0) [0|3] "SED"  GWM
 SG_ FohTAllEnable_B_Rq : 25|2@0+ (1,0) [0|3] "SED"  GWM
 SG_ FohT2Mnte_T_Rq : 39|6@0+ (1,0) [0|63] "minute"  GWM
 SG_ FohT2Hr_T_Rq : 47|5@0+ (1,0) [0|31] "hour"  GWM
 SG_ FohT2Enable_B_Rq : 8|1@0+ (1,0) [0|1] "SED"  GWM
 SG_ FohT1Mnte_T_Rq : 31|6@0+ (1,0) [0|63] "minute"  GWM
 SG_ FohT1Hr_T_Rq : 23|5@0+ (1,0) [0|31] "hour"  GWM
 SG_ FohT1Enable_B_Rq : 9|1@0+ (1,0) [0|1] "SED"  GWM
 SG_ FohStrtMnte_T_Rq : 15|6@0+ (1,0) [0|63] "minute"  GWM
 SG_ FohStrtHr_T_Rq : 7|5@0+ (1,0) [0|31] "hour"  GWM
 SG_ FohStrtEnable_B_Rq : 53|1@0+ (1,0) [0|1] "SED"  GWM
 SG_ FohContOn_B_Rq : 55|2@0+ (1,0) [0|3] "SED"  GWM

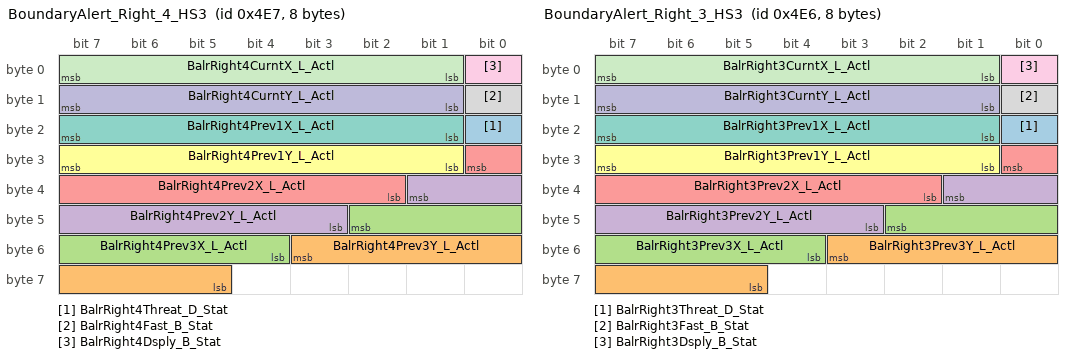
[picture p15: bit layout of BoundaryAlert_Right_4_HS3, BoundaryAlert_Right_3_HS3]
BO_ 1255 BoundaryAlert_Right_4_HS3: 8 GWM
 SG_ BalrRight4Threat_D_Stat : 16|1@0+ (1,0) [0|1] "SED"  IPC
 SG_ BalrRight4Prev3Y_L_Actl : 51|7@0+ (0.5,-32) [-32|31.5] "meter"  IPC
 SG_ BalrRight4Prev3X_L_Actl : 42|7@0+ (0.5,-32) [-32|31.5] "meter"  IPC
 SG_ BalrRight4Prev2Y_L_Actl : 33|7@0+ (0.5,-32) [-32|31.5] "meter"  IPC
 SG_ BalrRight4Prev2X_L_Actl : 24|7@0+ (0.5,-32) [-32|31.5] "meter"  IPC
 SG_ BalrRight4Prev1Y_L_Actl : 31|7@0+ (0.5,-32) [-32|31.5] "meter"  IPC
 SG_ BalrRight4Prev1X_L_Actl : 23|7@0+ (0.5,-32) [-32|31.5] "meter"  IPC
 SG_ BalrRight4Fast_B_Stat : 8|1@0+ (1,0) [0|1] "SED"  IPC
 SG_ BalrRight4Dsply_B_Stat : 0|1@0+ (1,0) [0|1] "SED"  IPC
 SG_ BalrRight4CurntY_L_Actl : 15|7@0+ (0.5,-32) [-32|31.5] "meter"  IPC
 SG_ BalrRight4CurntX_L_Actl : 7|7@0+ (0.5,-32) [-32|31.5] "meter"  IPC

BO_ 1254 BoundaryAlert_Right_3_HS3: 8 GWM
 SG_ BalrRight3Threat_D_Stat : 16|1@0+ (1,0) [0|1] "SED"  IPC
 SG_ BalrRight3Prev3Y_L_Actl : 51|7@0+ (0.5,-32) [-32|31.5] "meter"  IPC
 SG_ BalrRight3Prev3X_L_Actl : 42|7@0+ (0.5,-32) [-32|31.5] "meter"  IPC
 SG_ BalrRight3Prev2Y_L_Actl : 33|7@0+ (0.5,-32) [-32|31.5] "meter"  IPC
 SG_ BalrRight3Prev2X_L_Actl : 24|7@0+ (0.5,-32) [-32|31.5] "meter"  IPC
 SG_ BalrRight3Prev1Y_L_Actl : 31|7@0+ (0.5,-32) [-32|31.5] "meter"  IPC
 SG_ BalrRight3Prev1X_L_Actl : 23|7@0+ (0.5,-32) [-32|31.5] "meter"  IPC
 SG_ BalrRight3Fast_B_Stat : 8|1@0+ (1,0) [0|1] "SED"  IPC
 SG_ BalrRight3Dsply_B_Stat : 0|1@0+ (1,0) [0|1] "SED"  IPC
 SG_ BalrRight3CurntY_L_Actl : 15|7@0+ (0.5,-32) [-32|31.5] "meter"  IPC
 SG_ BalrRight3CurntX_L_Actl : 7|7@0+ (0.5,-32) [-32|31.5] "meter"  IPC

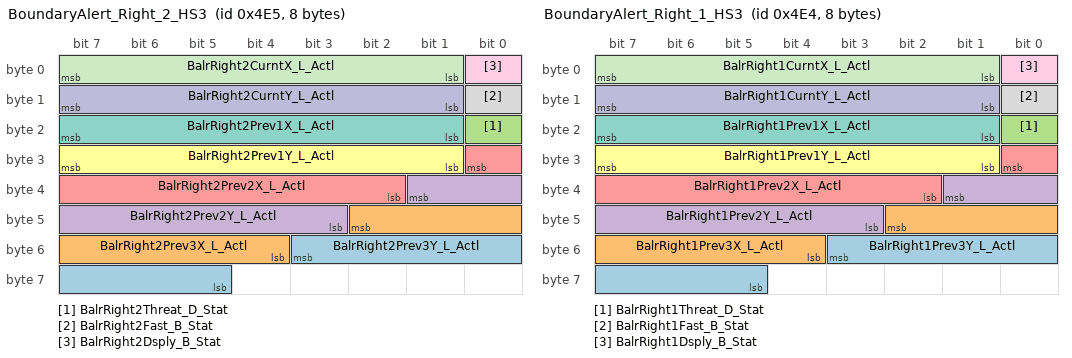
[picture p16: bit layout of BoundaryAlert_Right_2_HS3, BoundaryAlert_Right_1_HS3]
BO_ 1253 BoundaryAlert_Right_2_HS3: 8 GWM
 SG_ BalrRight2Prev3Y_L_Actl : 51|7@0+ (0.5,-32) [-32|31.5] "meter"  IPC
 SG_ BalrRight2Prev3X_L_Actl : 42|7@0+ (0.5,-32) [-32|31.5] "meter"  IPC
 SG_ BalrRight2Threat_D_Stat : 16|1@0+ (1,0) [0|1] "SED"  IPC
 SG_ BalrRight2Prev2Y_L_Actl : 33|7@0+ (0.5,-32) [-32|31.5] "meter"  IPC
 SG_ BalrRight2Prev2X_L_Actl : 24|7@0+ (0.5,-32) [-32|31.5] "meter"  IPC
 SG_ BalrRight2Prev1Y_L_Actl : 31|7@0+ (0.5,-32) [-32|31.5] "meter"  IPC
 SG_ BalrRight2Prev1X_L_Actl : 23|7@0+ (0.5,-32) [-32|31.5] "meter"  IPC
 SG_ BalrRight2Fast_B_Stat : 8|1@0+ (1,0) [0|1] "SED"  IPC
 SG_ BalrRight2Dsply_B_Stat : 0|1@0+ (1,0) [0|1] "SED"  IPC
 SG_ BalrRight2CurntY_L_Actl : 15|7@0+ (0.5,-32) [-32|31.5] "meter"  IPC
 SG_ BalrRight2CurntX_L_Actl : 7|7@0+ (0.5,-32) [-32|31.5] "meter"  IPC

BO_ 1252 BoundaryAlert_Right_1_HS3: 8 GWM
 SG_ BalrRight1Prev3Y_L_Actl : 51|7@0+ (0.5,-32) [-32|31.5] "meter"  IPC
 SG_ BalrRight1Prev3X_L_Actl : 42|7@0+ (0.5,-32) [-32|31.5] "meter"  IPC
 SG_ BalrRight1Threat_D_Stat : 16|1@0+ (1,0) [0|1] "SED"  IPC
 SG_ BalrRight1Prev2Y_L_Actl : 33|7@0+ (0.5,-32) [-32|31.5] "meter"  IPC
 SG_ BalrRight1Prev2X_L_Actl : 24|7@0+ (0.5,-32) [-32|31.5] "meter"  IPC
 SG_ BalrRight1Prev1Y_L_Actl : 31|7@0+ (0.5,-32) [-32|31.5] "meter"  IPC
 SG_ BalrRight1Prev1X_L_Actl : 23|7@0+ (0.5,-32) [-32|31.5] "meter"  IPC
 SG_ BalrRight1Fast_B_Stat : 8|1@0+ (1,0) [0|1] "SED"  IPC
 SG_ BalrRight1Dsply_B_Stat : 0|1@0+ (1,0) [0|1] "SED"  IPC
 SG_ BalrRight1CurntY_L_Actl : 15|7@0+ (0.5,-32) [-32|31.5] "meter"  IPC
 SG_ BalrRight1CurntX_L_Actl : 7|7@0+ (0.5,-32) [-32|31.5] "meter"  IPC

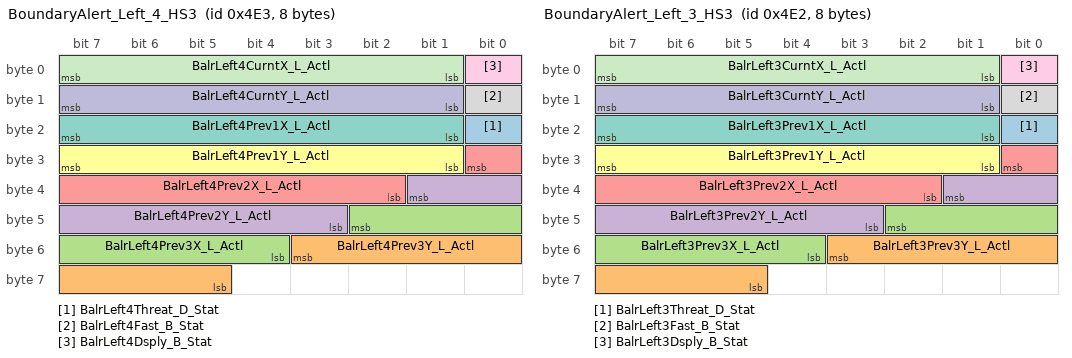
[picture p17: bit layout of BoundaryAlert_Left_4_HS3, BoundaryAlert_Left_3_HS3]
BO_ 1251 BoundaryAlert_Left_4_HS3: 8 GWM
 SG_ BalrLeft4Threat_D_Stat : 16|1@0+ (1,0) [0|1] "SED"  IPC
 SG_ BalrLeft4Prev3Y_L_Actl : 51|7@0+ (0.5,-32) [-32|31.5] "meter"  IPC
 SG_ BalrLeft4Prev3X_L_Actl : 42|7@0+ (0.5,-32) [-32|31.5] "meter"  IPC
 SG_ BalrLeft4Prev2Y_L_Actl : 33|7@0+ (0.5,-32) [-32|31.5] "meter"  IPC
 SG_ BalrLeft4Prev2X_L_Actl : 24|7@0+ (0.5,-32) [-32|31.5] "meter"  IPC
 SG_ BalrLeft4Prev1Y_L_Actl : 31|7@0+ (0.5,-32) [-32|31.5] "meter"  IPC
 SG_ BalrLeft4Prev1X_L_Actl : 23|7@0+ (0.5,-32) [-32|31.5] "meter"  IPC
 SG_ BalrLeft4Fast_B_Stat : 8|1@0+ (1,0) [0|1] "SED"  IPC
 SG_ BalrLeft4Dsply_B_Stat : 0|1@0+ (1,0) [0|1] "SED"  IPC
 SG_ BalrLeft4CurntY_L_Actl : 15|7@0+ (0.5,-32) [-32|31.5] "meter"  IPC
 SG_ BalrLeft4CurntX_L_Actl : 7|7@0+ (0.5,-32) [-32|31.5] "meter"  IPC

BO_ 1250 BoundaryAlert_Left_3_HS3: 8 GWM
 SG_ BalrLeft3Threat_D_Stat : 16|1@0+ (1,0) [0|1] "SED"  IPC
 SG_ BalrLeft3Prev3Y_L_Actl : 51|7@0+ (0.5,-32) [-32|31.5] "meter"  IPC
 SG_ BalrLeft3Prev3X_L_Actl : 42|7@0+ (0.5,-32) [-32|31.5] "meter"  IPC
 SG_ BalrLeft3Prev2Y_L_Actl : 33|7@0+ (0.5,-32) [-32|31.5] "meter"  IPC
 SG_ BalrLeft3Prev2X_L_Actl : 24|7@0+ (0.5,-32) [-32|31.5] "meter"  IPC
 SG_ BalrLeft3Prev1Y_L_Actl : 31|7@0+ (0.5,-32) [-32|31.5] "meter"  IPC
 SG_ BalrLeft3Prev1X_L_Actl : 23|7@0+ (0.5,-32) [-32|31.5] "meter"  IPC
 SG_ BalrLeft3Fast_B_Stat : 8|1@0+ (1,0) [0|1] "SED"  IPC
 SG_ BalrLeft3Dsply_B_Stat : 0|1@0+ (1,0) [0|1] "SED"  IPC
 SG_ BalrLeft3CurntY_L_Actl : 15|7@0+ (0.5,-32) [-32|31.5] "meter"  IPC
 SG_ BalrLeft3CurntX_L_Actl : 7|7@0+ (0.5,-32) [-32|31.5] "meter"  IPC

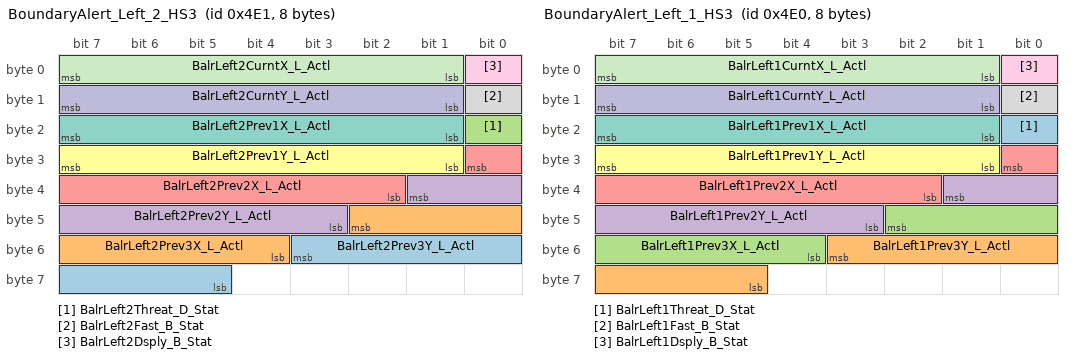
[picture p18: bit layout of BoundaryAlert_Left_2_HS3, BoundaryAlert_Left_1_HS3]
BO_ 1249 BoundaryAlert_Left_2_HS3: 8 GWM
 SG_ BalrLeft2Prev3Y_L_Actl : 51|7@0+ (0.5,-32) [-32|31.5] "meter"  IPC
 SG_ BalrLeft2Prev3X_L_Actl : 42|7@0+ (0.5,-32) [-32|31.5] "meter"  IPC
 SG_ BalrLeft2Threat_D_Stat : 16|1@0+ (1,0) [0|1] "SED"  IPC
 SG_ BalrLeft2Prev2Y_L_Actl : 33|7@0+ (0.5,-32) [-32|31.5] "meter"  IPC
 SG_ BalrLeft2Prev2X_L_Actl : 24|7@0+ (0.5,-32) [-32|31.5] "meter"  IPC
 SG_ BalrLeft2Prev1Y_L_Actl : 31|7@0+ (0.5,-32) [-32|31.5] "meter"  IPC
 SG_ BalrLeft2Prev1X_L_Actl : 23|7@0+ (0.5,-32) [-32|31.5] "meter"  IPC
 SG_ BalrLeft2Fast_B_Stat : 8|1@0+ (1,0) [0|1] "SED"  IPC
 SG_ BalrLeft2Dsply_B_Stat : 0|1@0+ (1,0) [0|1] "SED"  IPC
 SG_ BalrLeft2CurntY_L_Actl : 15|7@0+ (0.5,-32) [-32|31.5] "meter"  IPC
 SG_ BalrLeft2CurntX_L_Actl : 7|7@0+ (0.5,-32) [-32|31.5] "meter"  IPC

BO_ 1248 BoundaryAlert_Left_1_HS3: 8 GWM
 SG_ BalrLeft1Threat_D_Stat : 16|1@0+ (1,0) [0|1] "SED"  IPC
 SG_ BalrLeft1Prev3Y_L_Actl : 51|7@0+ (0.5,-32) [-32|31.5] "meter"  IPC
 SG_ BalrLeft1Prev3X_L_Actl : 42|7@0+ (0.5,-32) [-32|31.5] "meter"  IPC
 SG_ BalrLeft1Prev2Y_L_Actl : 33|7@0+ (0.5,-32) [-32|31.5] "meter"  IPC
 SG_ BalrLeft1Prev2X_L_Actl : 24|7@0+ (0.5,-32) [-32|31.5] "meter"  IPC
 SG_ BalrLeft1Prev1Y_L_Actl : 31|7@0+ (0.5,-32) [-32|31.5] "meter"  IPC
 SG_ BalrLeft1Prev1X_L_Actl : 23|7@0+ (0.5,-32) [-32|31.5] "meter"  IPC
 SG_ BalrLeft1Fast_B_Stat : 8|1@0+ (1,0) [0|1] "SED"  IPC
 SG_ BalrLeft1Dsply_B_Stat : 0|1@0+ (1,0) [0|1] "SED"  IPC
 SG_ BalrLeft1CurntY_L_Actl : 15|7@0+ (0.5,-32) [-32|31.5] "meter"  IPC
 SG_ BalrLeft1CurntX_L_Actl : 7|7@0+ (0.5,-32) [-32|31.5] "meter"  IPC

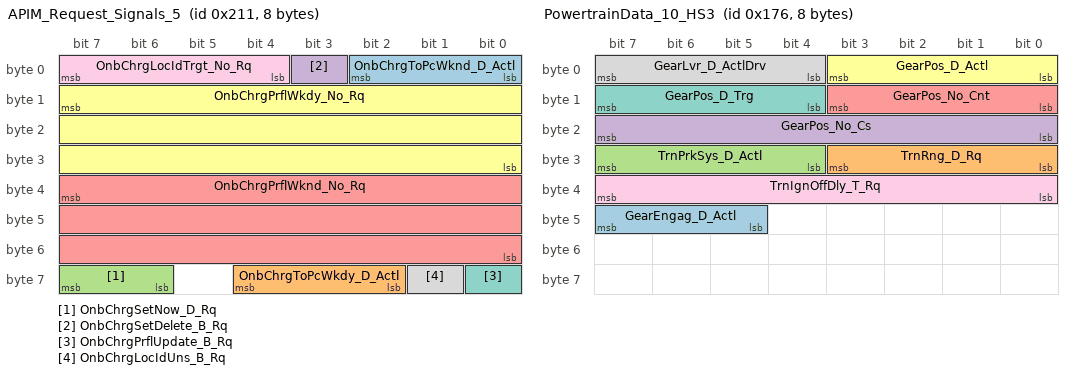
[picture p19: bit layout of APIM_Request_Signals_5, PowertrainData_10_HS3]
BO_ 529 APIM_Request_Signals_5: 8 APIM
 SG_ OnbChrgToPcWknd_D_Actl : 2|3@0+ (1,0) [0|7] "percent"  GWM
 SG_ OnbChrgToPcWkdy_D_Actl : 60|3@0+ (1,0) [0|7] "percent"  GWM
 SG_ OnbChrgSetNow_D_Rq : 63|2@0+ (1,0) [0|3] "SED"  GWM
 SG_ OnbChrgSetDelete_B_Rq : 3|1@0+ (1,0) [0|1] "SED"  GWM
 SG_ OnbChrgPrflWknd_No_Rq : 39|24@0+ (1,0) [0|16777215] "unitless"  GWM
 SG_ OnbChrgPrflWkdy_No_Rq : 15|24@0+ (1,0) [0|16777215] "unitless"  GWM
 SG_ OnbChrgPrflUpdate_B_Rq : 56|1@0+ (1,0) [0|1] "SED"  GWM
 SG_ OnbChrgLocIdUns_B_Rq : 57|1@0+ (1,0) [0|1] "SED"  GWM
 SG_ OnbChrgLocIdTrgt_No_Rq : 7|4@0+ (1,0) [0|15] "unitless"  GWM

BO_ 374 PowertrainData_10_HS3: 8 GWM
 SG_ GearEngag_D_Actl : 47|3@0+ (1,0) [0|7] "SED"  IPC
 SG_ TrnRng_D_Rq : 27|4@0+ (1,0) [0|15] "SED"  APIM,APIM_CISM
 SG_ TrnPrkSys_D_Actl : 31|4@0+ (1,0) [0|15] "SED" Vector__XXX
 SG_ GearPos_No_Cs : 23|8@0+ (1,0) [0|255] "unitless" Vector__XXX
 SG_ GearPos_No_Cnt : 11|4@0+ (1,0) [0|15] "unitless" Vector__XXX
 SG_ GearPos_D_Actl : 3|4@0+ (1,0) [0|15] "SED"  APIM,APIM_CISM
 SG_ GearPos_D_Trg : 15|4@0+ (1,0) [0|15] "SED"  APIM,APIM_CISM
 SG_ GearLvr_D_ActlDrv : 7|4@0+ (1,0) [0|15] "SED" Vector__XXX
 SG_ TrnIgnOffDly_T_Rq : 39|8@0+ (4,0) [0|1020] "ms" Vector__XXX

BO_ 500 DSP_Request_Signals_1: 8 APIM
 SG_ Dsp_SourceSetTrack_Rq : 39|32@0+ (1,0) [0|4294967295] "unitless"  ACM
 SG_ Dsp_ItemNameLength_Rq : 14|5@0+ (1,0) [0|20] "SED"  ACM
 SG_ Dsp_GetCDTOCDData_Rq : 0|2@0+ (1,0) [0|3] "SED"  ACM
 SG_ Dsp_FolderNumber_Rq : 23|16@0+ (1,0) [0|65535] "unitless"  ACM
 SG_ Dsp_CutItem_Rq : 9|2@0+ (1,0) [0|3] "SED"  ACM
 SG_ Dsp_AudioSourceSel_Rq : 3|3@0+ (1,0) [0|7] "SED"  ACM

BO_ 503 DSP_Request_Signals_4: 8 APIM
 SG_ Dsp_PlayFrstTrInFldr_Rq : 39|16@0+ (1,0) [0|65535] "unitless"  ACM
 SG_ Dsp_ItemIndex_Rq : 23|16@0+ (1,0) [0|65535] "unitless"  APIM,ACM
 SG_ Dsp_FolderNumber3_Rq : 7|16@0+ (1,0) [0|65535] "unitless"  APIM,ACM
 SG_ Dsp_AudioSourceSel3_Rq : 55|3@0+ (1,0) [0|7] "SED"  ACM

BO_TX_BU_ 659 : APIM_CISM,APIM;
BO_TX_BU_ 630 : APIM_CISM,APIM;
BO_TX_BU_ 627 : APIM_CISM,APIM;
BO_TX_BU_ 595 : APIM_CISM,APIM;
BO_TX_BU_ 662 : APIM_CISM,APIM;
BO_TX_BU_ 479 : APIM_CISM,APIM;
BO_TX_BU_ 474 : APIM_CISM,APIM;
BO_TX_BU_ 477 : APIM_CISM,APIM;
BO_TX_BU_ 260 : APIM_CISM,APIM;
BO_TX_BU_ 1116 : APIM_CISM,APIM;
BO_TX_BU_ 529 : APIM_CISM,APIM;

CM_ "FNV3 HS3 CAN";
CM_ BU_ APIM_CISM "Accessory Protocol Interface Module 4.0";
CM_ BU_ APIM "Accessory Protocol Interface Module 4.0";
CM_ BU_ ESPM "Ethernet Switch Port Module";
CM_ BU_ DSP "Audio Digital Signal Processing Module";
CM_ BU_ FCIMB "Front Controls Interface Module B";
CM_ BU_ RACM_RCIM "Rear Audio Control Module - Rear Controls Interface Module";
CM_ BU_ HUD_ADV "Advanced HUD";
CM_ BU_ WCM "Wireless Charging Module";
CM_ BU_ TRM_ITRM "Integrated Trailer Module with TBM on HS2 for FNV2.5";
CM_ BU_ ACM "Audio Control Module";
CM_ BU_ GWM "Gateway Module";
CM_ BU_ IPC "Instrument Panel Cluster Control Module";
CM_ BU_ GENERIC "Holding pattern ECU for developmental messages";
CM_ BU_ TSTR "Diagnostic Tester";
CM_ SG_ 667 APIM_NFAM_Word_Rx "MM ISO 15765-2 Message Catalogue
Section CONMP - RDISP";
CM_ SG_ 659 APIM_NFAM_Word_Tx "MM ISO 15765-2 Message Catalogue
Section RDISP - CONMP";
CM_ SG_ 118 SteWhlCompAnEst_D_Qf "Legacy signal not supported, reserving bit locations for commodity BCM, PAM, RCM, APIM dbc files.  GWM to Tx Init value, no valid data. ";
CM_ SG_ 118 SteWhlComp_An_Est "Legacy signal not supported, reserving bit locations for commodity BCM, PAM, RCM, APIM dbc files.  GWM to Tx Init value, no valid data. ";
CM_ SG_ 836 FohFalt_D_Stat "Signal not transmitted on vehicles that do not have the Fuel operated heater feature.";
CM_ SG_ 836 FohEnbl_B_RqDrv "Signal not transmitted on vehicles that do not have the Fuel operated heater feature.";
CM_ SG_ 836 FohRqRun_B_Rq "Signal not transmitted on vehicles that do not have the Fuel operated heater feature.";
CM_ SG_ 836 HvacPrecondMode_D_Rq "Signal not transmitted on vehicles that do not have the Fuel operated heater feature.";
CM_ SG_ 836 HvacPrecondBlwr_D_Rq "Signal not transmitted on vehicles that do not have the Fuel operated heater feature.";
CM_ SG_ 836 Foh_D_Stat "Signal not transmitted on vehicles that do not have the Fuel operated heater feature.";
CM_ SG_ 836 FuelFlw_Vl_ActlFoh "Signal not transmitted on vehicles that do not have the Fuel operated heater feature.";
CM_ SG_ 836 EngClnt_Te_ActlFoh "Signal not transmitted on vehicles that do not have the Fuel operated heater feature.";
CM_ SG_ 931 CrnkInhbt_No_Cs "Signal not transmitted on gas and HEV variants.";
CM_ SG_ 931 CrnkInhbt_No_Cnt "Signal not transmitted on gas and HEV variants.";
CM_ SG_ 618 IgnPsswrdSetup_B_Rq "ABSGenSigTimeoutTime=1000";
CM_ SG_ 618 IgnPsswrdLckout_B_Stat "ABSGenSigTimeoutTime=1000";
CM_ SG_ 618 PaakCtlPssvData_No_Actl "Not transmitted on all vehicle variants";
CM_ SG_ 773 MemSwtchPsngrFdbck_B_Rq "Updated to 1 bit for CGEA, Not backwards compatible";
CM_ BO_ 932 "NOTE: START BITS 8-11 MUST BE OPEN SPEC REQUIREMENT";
CM_ SG_ 932 CanMsg3A4_No_Crc "Signal not transmitted on gas and HEV variants.";
CM_ SG_ 932 CanMsg3A4_No_Cnt "Signal not transmitted on gas and HEV variants.";
CM_ SG_ 1104 DrvEngageLevel_No_Cs "Signal not transmitted on gas variants.";
CM_ SG_ 1104 DrvEngageLevel_No_Cnt "Signal not transmitted on gas variants.";
CM_ SG_ 148 VehYaw_W_Actl "CCMGenSigTimeoutTime=1000";
CM_ BO_ 828 "Set GenSigSendType = NoSigSendType (Cyclic) for the following signals, D.Card 3/31/08
Driver_Lock_Sw_Stat
";
CM_ SG_ 512 PrplWhlTotTqRq_No_Cs "Signal not transmitted on gas variants.";
CM_ SG_ 512 PrplWhlTotTqRq_No_Cnt "Signal not transmitted on gas variants.";
CM_ SG_ 512 EngAout_Tq_MxMxN "Signal not transmitted on gas variants.";
CM_ SG_ 1112 BattTracClntPmp_D_Stat "48V mHEV: ECM_HEVDSL is Tx,  MHT HEV: PCM_HEV is Tx,  Powersplit HEV: SOBDMC_HPCM is Tx";
CM_ SG_ 977 CnvtTopSleepActv_B_Rq "Signal not transmitted on gas and HEV variants.";
CM_ SG_ 977 CnvtTopBrkActv_B_Rq "Signal not transmitted on gas and HEV variants.";
CM_ SG_ 977 CnvtTopPos_Up_Stat "Signal not transmitted on vehicles without convertible tops.";
CM_ SG_ 977 CnvtTopPos_Dn_Stat "Signal not transmitted on vehicles without convertible tops.";
CM_ SG_ 746 Con_BTAud_Shuffle_St "Object MediaPlayer BTAudio.Shuffle";
CM_ SG_ 746 Con_BTAud_Repeat_St "Object Media Player BTAudio.Repeat";
CM_ SG_ 746 Con_BTAud_IntroScan_St "Object Media Player BTAudio.IntroScan";
CM_ SG_ 746 Con_BTAud_ActTrNum1_St "Object Media Player BTAudio.ActiveTrackNum1
";
CM_ SG_ 746 Con_ShowBTPINNumb_St "Object BT Device.ShowBTPINNumb

PIN value range (dec): 0000 - 9999

Inactive: $3FFD
Invalid: $3FFE";
CM_ SG_ 746 Con_BTAud_Error_St "Object Media Player BTAudio.BTAudioError";
CM_ SG_ 746 Con_BTAud_FunctStats_St "Object Media Player BTAudio.FunctionStatus";
CM_ SG_ 746 Con_BTAud_OpMode_St "Object Media Player BTAudio.OperationMode";
CM_ SG_ 479 DISP_SetVol_Source_Rq "Object.VolumeControl.MFD_SetVol_Source.Rq

SetVol_Source.Rq";
CM_ SG_ 479 DISP_SetVol_Level_Rq "Object.VolumeControl.MFD_SetVol_Level.Rq 

0x0 Inactive/NoChange
0x1 No Volume
0x2 Vol_Step1
0x3 Vol_Step2
0x4 Vol_Step3
Cont.
0x1F Vol_Step30

Object.VolumeControl.SetPointVolume

Object.VolumeControl.SetVol_Level.Rq";
CM_ SG_ 479 DISP_Setshaker_Rq "Object.AudioSettings.SetShaker.Rq
";
CM_ SG_ 474 Nav_SetCurrStatMCCh_Rq "Object Audio.SetDSPProgram
";
CM_ SG_ 474 NAV_SetNEWSMode_Rq "Object Tuner.SetNEWSMode";
CM_ SG_ 474 NAV_SetMid_Rq "Object Audio Settings.SetMid

Level -7..0..7
$F: Inactive

Method: SetMidRange.Rq";
CM_ SG_ 474 NAV_SetDSP_Rq "Object Audio.SetDSP

Object.AudioSettings.SetOccupancy_Mode.Rq";
CM_ SG_ 474 NAV_SetCurrStatFreq_Rq "Object Tuner.SetCurrentStat.Request.Frequency

AM: Freq = 153+ Offset kHz.
Offset 0..1557

FM: Freq = 76+ Offset*0.05 MHz. Offset 0..640
Selected tuned band determine frequency (kHz or MHz).";
CM_ SG_ 474 NAV_SetCurrentStatOp_Rq "Object Tuner.SetCurrentStat.Request.Operation";
CM_ SG_ 474 NAV_SetCurrentPICode_Rq "Object Tuner.SetCurrentStat.Request.PI Code

16 bit hex coded PI Code

";
CM_ SG_ 474 NAV_ARReqstrSystem_Rq "Object Audio Management AudioClient.AudioRequest.Requester System

AudioRequest.Rq : RequesterSystem";
CM_ SG_ 474 NAV_ARReqstrPriority_Rq "Object Audio Management AudioClient.AudioRequest.Requester Priority

AudioRequest.Rq : RequesterPriority";
CM_ SG_ 474 NAV_AROperationType_Rq "Object Audio Management Audio Client.AudioRequest.Operation Type

AudioRequest.Rq : OperationType";
CM_ SG_ 474 NAV_ARAudioSource_Rq "Object Audio Management Audio Client.AudioRequest.Requested Audio Source

$8 interpreted as APIM or Navigation

AudioRequest.Rq : RequestedAudioSource";
CM_ SG_ 477 NAV_SetTreble_Rq "Object Audio.SetTreble.Rq



Level -7..0..7
$F: Inactive";
CM_ SG_ 477 NAV_SetFader_Rq "Object Audio.SetFader

.Rq

Level -7..0..7

$F: Inactive";
CM_ SG_ 477 NAV_SetBass_Rq "Object Audio.SetBass.Rq



Level -7..0..7
$F: Inactive";
CM_ SG_ 477 NAV_SetBalance_Rq "Object Audio.SetBalance.Rq



Level -7..0..7
$F: Inactive";
CM_ SG_ 477 NAV_SetAVC_Rq "Object Audio.SetAVC
Object. Audio.SetSpeed_Comp_Vol.Rq

$F: Inactive";
CM_ SG_ 477 NAV_SecurtyPINUnlock_Rq "Object ACU System Master.SecurityPINUnlock
PIN: from 0000 - 9999
$3FFF: Inactive";
CM_ SG_ 477 NAV_LoadEjectMode_Rq "Object Single CD.LoadEject.Mode";
CM_ SG_ 477 NAV_LoadEjectDisc_Rq "Object Indash CD Changer.LoadEject(Disc Number)
Object Single CD.LoadEject(Action)
";
CM_ SG_ 260 SDARS_GetESN_Rq "Object Tuner.SDARS Tuner.GetESN";
CM_ SG_ 260 SDARS_SRReplay_Rq "Object Tuner.SDARS Tuner.SR-ReplayStatus";
CM_ SG_ 260 SDARS_SelectCategory_Rq "Object Tuner.SDARS Tuner.SetCategory
0x00: All
0x01: Category1
0x02: Category2
....
0xF9: Category249
0xFA: Reserved
....
0xFE: Reserved
0xFF: Invalid
";
CM_ SG_ 260 SDARS_InfoRefChanNum_Rq "Object Tuner.SDARS Tuner.InfoRefresh.Rq
$0: Channel_0
$1: Channel_1
$2: Channel_2
$FE: Channel_254
$FF: Inactive";
CM_ SG_ 260 SDARS_FactoryReset_Rq "Object Tuner.SDARS Tuner.FactoryReset

Object VehicleSettings.FactoryReset.Rq

Object StationManagement.FactoryReset.Rq

Enhanced Memory: FactoryReset_Rq";
CM_ SG_ 476 NAV_SkipCatalouge_Rq "Object Single CD.SkipFolder";
CM_ SG_ 476 NAV_SetOperationMode_Rq "Object Rear CD Changer.SetOperationMode
Object Indash CD Changer.SetOperationMode
Object Single CD.SetOperationMode";
CM_ SG_ 476 NAV_SetDSPProgram_Rq "Object Audio.SetDSPProgram
";
CM_ SG_ 502 Dsp_StartItemIndexRq "Object Media Player BT SDCard.GetMPInfo.StartItemIndex
USB.GetMPInfo.StartItemIndex
SingleCD.GetMPInfo.StartItemIndex

$FFFF: Inactive";
CM_ SG_ 502 Dsp_NbrOfItems2_Rq "Object Media Player 
BT Audio.GetMPInfo.NbrOfItems
SDCard.GetMPInfo.NbrOfItems
USB.GetMPInfo.NbrOfItems
SingleCD.GetMPInfo.NbrOfItems";
CM_ SG_ 502 Dsp_ItemNameLength2_Rq "Object Media Player 
BT Audio.GetMPInfo.ItemNameLength
SDCard.GetMPInfo.ItemNameLength
USB.GetMPInfo.ItemNameLength
SingleCD.GetMPInfo.ItemNameLength";
CM_ SG_ 502 Dsp_FolderNumber2_Rq "Object Media Player 
BT Audio.GetMPInfo.FolderNumber
USB.GetMPInfo.FolderNumber
SDCard.GetMPInfo.FolderNumber
SingleCD.GetMPInfo.FolderNumber

$FFFF: Inactive";
CM_ SG_ 502 Dsp_FolderContent_Rq "Object Media Player 
BT Audio.GetMPInfo.FolderContent
SDCard.GetMPInfo.FolderContent
USB.GetMPInfo.FolderContent
SingleCD.GetMPinfo.Foldercontent

Note: Value table entries were truncated from:
$0: ..FolderNumber
$1: ..OfParameterFolderNumber";
CM_ SG_ 502 Dsp_CutItem2_Rq "Object Media Player 
BT Audio.GetMPInfo.CutItemName
SDCard.GetMPInfo.CutItemName
USB.GetMPInfo.CutItemName
SingleCD.GetMPInfo.CutItemName

Note: value table entry for value $2 was truncated from:
OneQuarterFromTheBeginningThreeQuarterFromTheEnd";
CM_ SG_ 502 Dsp_AudioSourceSel2_Rq "Object Media Player 
BT Audio.GetMPInfo.AudioSource
SDCard.GetMPInfo.AudioSource
USB.GetMPInfo.AudioSource
SingleCD.GetMPInfo.AudioSource";
CM_ SG_ 374 TrnRng_D_Rq "Powersplit HEVs with HF45, HPCM will Tx  this message.  For all other programs it will be Tx by PCM or TCM. ";
CM_ SG_ 374 TrnPrkSys_D_Actl "Powersplit HEVs with HF45, HPCM will Tx  this message.  For all other programs it will be Tx by PCM or TCM. ";
CM_ SG_ 374 GearPos_No_Cs "Powersplit HEVs with HF45, HPCM will Tx  this message.  For all other programs it will be Tx by PCM or TCM. ";
CM_ SG_ 374 GearPos_No_Cnt "Powersplit HEVs with HF45, HPCM will Tx  this message.  For all other programs it will be Tx by PCM or TCM. ";
CM_ SG_ 374 GearPos_D_Actl "Powersplit HEVs with HF45, HPCM will Tx  this message.  For all other programs it will be Tx by PCM or TCM. ";
CM_ SG_ 374 GearPos_D_Trg "Powersplit HEVs with HF45, HPCM will Tx  this message.  For all other programs it will be Tx by PCM or TCM. ";
CM_ SG_ 374 GearLvr_D_ActlDrv "Powersplit HEVs with HF45, HPCM will Tx  this message.  For all other programs it will be Tx by PCM or TCM. ";
CM_ SG_ 500 Dsp_SourceSetTrack_Rq "Object Media Player BTAudio.SetTrack
Object Media Player USB.SetTrack
Object Single CD.SetTrack.AudioSource
";
CM_ SG_ 500 Dsp_ItemNameLength_Rq "Object Media Player BTAudio.GetFolderName.ItemNameLength
Object Media Player USB.GetFolderName.ItemNameLength
Object Single CD.GetFolderName.ItemNameLength";
CM_ SG_ 500 Dsp_GetCDTOCDData_Rq "GetCDTOCData";
CM_ SG_ 500 Dsp_FolderNumber_Rq "Object Media Player BTAudio.GetFolderName.FolderNumber
Object Media Player USB.GetFolderName.FolderNumber
Object Single CD.GetFolderName.FolderNumber";
CM_ SG_ 500 Dsp_CutItem_Rq "Object Media Player BTAudio.GetFolderName.CutItemName
Object Media Player USB.GetFolderName.CutItemName
Object Single CD.GetFolderName.CutItemName

Note: value table entry for value $2 was truncated from:
OneQuarterFromTheBeginningThreeQuarterFromTheEnd";
CM_ SG_ 500 Dsp_AudioSourceSel_Rq "Object Media Player 
{ BTAudio.GetFolderName, 
SDCard.GetFolderName,
USB.GetFolderName,
BTAudio.SetTrack,
SD Card.SetTrack}.AudioSource
USB.SetTrack.AudioSource
Object Single CD.GetFolderName.AudioSource
Object Single CD.SetTrack.AudioSource";
CM_ SG_ 503 Dsp_PlayFrstTrInFldr_Rq "Object Single CD.PlayFirstTrackInFolder
Object Media Player BTAudio.PlayFirstTrackInFolder.FolderNumber
Object Media Player USB.PlayFirstTrackInFolder.FolderNumber

$FFFF: Inactive";
CM_ SG_ 503 Dsp_ItemIndex_Rq "Object Media Player BTAudio.GetDetailedMPInfo.ItemIndex
Object Media Player USB.GetDetailedMPInfo.ItemIndex

$FFFF: Inactive";
CM_ SG_ 503 Dsp_FolderNumber3_Rq "Object Media Player BTAudio.GetDetailedMPInfo.FolderNumber
Object Media Player USB.GetDetailedMPInfo.FolderNumber

$FFFF: Inactive";
CM_ SG_ 503 Dsp_AudioSourceSel3_Rq "Objects Media Player  {BTAudio, USB}.GetDetailedMPInfo.AudioSource

Objects Media Player {Single CD, BTAudio, USB}.PlayFirstTrackInFolder.AudioSource";
BA_DEF_  "BusType" STRING ;
BA_DEF_ BO_  "FrameRouting" STRING ;
BA_DEF_ BO_  "NetworkInitialization" ENUM  "No","Yes";
BA_DEF_ BO_  "GenMsgStartDelayTime" INT 0 10000;
BA_DEF_ BO_  "GenMsgNrOfRepetition" INT 0 100;
BA_DEF_ BO_  "GenMsgDelayTime" INT 0 1000;
BA_DEF_ BO_  "GenMsgCycleTime" INT 0 100000;
BA_DEF_ BO_  "GenMsgSendType" ENUM  "FixedPeriodic","Event","EnabledPeriodic","NotUsed","NotUsed","EventPeriodic","NotUsed","NotUsed","NoMsgSendType";
BA_DEF_ SG_  "U_V710_MY2023_Tx" ENUM  "No","Yes";
BA_DEF_ SG_  "U_P708_MY2023_Tx" ENUM  "No","Yes";
BA_DEF_ SG_  "U_V713AV_MY2022_Tx" ENUM  "No","Yes";
BA_DEF_ SG_  "U_V713N_MY2022_Tx" ENUM  "No","Yes";
BA_DEF_ SG_  "ECGUsedTxSignal" ENUM  "No","Yes";
BA_DEF_ SG_  "U_V710_MY2023_Rx" ENUM  "No","Yes";
BA_DEF_ SG_  "U_P708_MY2023_Rx" ENUM  "No","Yes";
BA_DEF_ SG_  "U_V713AV_MY2022_Rx" ENUM  "No","Yes";
BA_DEF_ SG_  "U_V713N_MY2022_Rx" ENUM  "No","Yes";
BA_DEF_ SG_  "ECGUsedRxSignal" ENUM  "No","Yes";
BA_DEF_ SG_  "UsedOnPgmDBC" ENUM  "No","Yes";
BA_DEF_ SG_  "ContentDependant" ENUM  "No","Yes";
BA_DEF_ SG_  "GenSigStartValue" HEX 0 268435455;
BA_DEF_ SG_  "MetaData" ENUM  "No","Yes";
BA_DEF_ SG_  "WakeupSignal" ENUM  "No","Yes";
BA_DEF_ SG_  "GenSigInactiveValue" INT 0 100000;
BA_DEF_ SG_  "GenSigSendType" ENUM  "Cyclic","OnWrite","vector_leerstring","OnChange","vector_leerstring","IfActive","vector_leerstring","NoSigSendType";
BA_DEF_ BO_  "TpTxIndex" INT 0 536870911;
BA_DEF_ BO_  "OvtpPushApplication" ENUM  "FALSE","TRUE";
BA_DEF_ BO_  "SCP_FreshnessValueLength" INT 0 512;
BA_DEF_ BO_  "SCP_DataId" INT 0 17663;
BA_DEF_ BO_  "SCP_FreshnessValueTxLength" INT 0 512;
BA_DEF_ BO_  "SCP_AuthInfoTxLength" INT 0 512;
BA_DEF_ BO_  "SC_Message" ENUM  "No","Yes";
BA_DEF_ BO_  "GenMsgRoutingTimeoutTime" INT 0 5000;
BA_DEF_ BO_  "MessageGateway" ENUM  "No","Yes";
BA_DEF_ BO_  "NmAsrMessage" ENUM  "No","Yes";
BA_DEF_ BO_  "DiagState" ENUM  "No","Yes";
BA_DEF_ BO_  "DiagRequest" ENUM  "No","Yes";
BA_DEF_ BO_  "DiagResponse" ENUM  "No","Yes";
BA_DEF_ BO_  "GenMsgILSupport" ENUM  "No","Yes";
BA_DEF_ BU_  "OvtpOperationMode" ENUM  "SERVER","CLIENT";
BA_DEF_ BU_  "OvtpEcuAddress" INT 0 1022;
BA_DEF_ BU_  "ILUsed" ENUM  "No","Yes";
BA_DEF_ BU_  "Terminator" ENUM  "No","Yes";
BA_DEF_ BU_  "NodeWakeUpTime" INT 0 10000;
BA_DEF_ BU_  "NodeStartUpTime" INT 0 10000;
BA_DEF_ BU_  "NmAsrNodeIdentifier" HEX 0 255;
BA_DEF_ BU_  "NmAsrNode" ENUM  "No","Yes";
BA_DEF_ BU_  "PowerType" ENUM  "Switched","Latched","Sleep","vector_leerstring","vector_leerstring";
BA_DEF_ BU_  "NmStationAddress" INT 0 255;
BA_DEF_ BU_  "NosPackage" ENUM  "None","I3_1","I3_2","1.0.1","RP","EuCD","Volcano","I3_3","FNOS_Autosar";
BA_DEF_ BU_  "PackageID" STRING ;
BA_DEF_ BU_  "GatewayECU" ENUM  "No","Yes";
BA_DEF_  "NetworkSpeed" ENUM  "500kBits/s","125kBit/s";
BA_DEF_  "VersionNumber" INT 0 10000;
BA_DEF_  "StarNetworkGwType" ENUM  "0=NotDefined","1=HS1","2=HS2","3=HS3","4=HS4","5=HS5","6=MS1","7=HS6","8=HS7","9=MS2","10=FD1","11=FD2","12=FD3","13=FD4","14=FD5","15=FD6","16=FD7","17=FD8";
BA_DEF_  "CMDB_Version" STRING ;
BA_DEF_  "NmType" STRING ;
BA_DEF_  "NmAsrMessageCount" INT 128 256;
BA_DEF_  "NmAsrBaseAddress" HEX 1280 1408;
BA_DEF_  "DBName" STRING ;
BA_DEF_  "VersionDay" INT 1 31;
BA_DEF_  "Manufacturer" STRING ;
BA_DEF_  "VersionMonth" INT 1 12;
BA_DEF_  "VersionYear" INT 2000 3000;
BA_DEF_  "NmBaseAddress" HEX 1280 1280;
BA_DEF_  "NmMessageCount" INT 0 128;
BA_DEF_DEF_  "BusType" "";
BA_DEF_DEF_  "FrameRouting" "";
BA_DEF_DEF_  "NetworkInitialization" "Yes";
BA_DEF_DEF_  "GenMsgStartDelayTime" 0;
BA_DEF_DEF_  "GenMsgNrOfRepetition" 1;
BA_DEF_DEF_  "GenMsgDelayTime" 20;
BA_DEF_DEF_  "GenMsgCycleTime" 0;
BA_DEF_DEF_  "GenMsgSendType" "NoMsgSendType";
BA_DEF_DEF_  "U_V710_MY2023_Tx" "No";
BA_DEF_DEF_  "U_P708_MY2023_Tx" "No";
BA_DEF_DEF_  "U_V713AV_MY2022_Tx" "No";
BA_DEF_DEF_  "U_V713N_MY2022_Tx" "No";
BA_DEF_DEF_  "ECGUsedTxSignal" "No";
BA_DEF_DEF_  "U_V710_MY2023_Rx" "No";
BA_DEF_DEF_  "U_P708_MY2023_Rx" "No";
BA_DEF_DEF_  "U_V713AV_MY2022_Rx" "No";
BA_DEF_DEF_  "U_V713N_MY2022_Rx" "No";
BA_DEF_DEF_  "ECGUsedRxSignal" "No";
BA_DEF_DEF_  "UsedOnPgmDBC" "Yes";
BA_DEF_DEF_  "ContentDependant" "No";
BA_DEF_DEF_  "GenSigStartValue" 0;
BA_DEF_DEF_  "MetaData" "No";
BA_DEF_DEF_  "WakeupSignal" "No";
BA_DEF_DEF_  "GenSigInactiveValue" 0;
BA_DEF_DEF_  "GenSigSendType" "NoSigSendType";
BA_DEF_DEF_  "TpTxIndex" 0;
BA_DEF_DEF_  "OvtpPushApplication" "FALSE";
BA_DEF_DEF_  "SCP_FreshnessValueLength" 64;
BA_DEF_DEF_  "SCP_DataId" 0;
BA_DEF_DEF_  "SCP_FreshnessValueTxLength" 11;
BA_DEF_DEF_  "SCP_AuthInfoTxLength" 53;
BA_DEF_DEF_  "SC_Message" "No";
BA_DEF_DEF_  "GenMsgRoutingTimeoutTime" 0;
BA_DEF_DEF_  "MessageGateway" "No";
BA_DEF_DEF_  "NmAsrMessage" "No";
BA_DEF_DEF_  "DiagState" "No";
BA_DEF_DEF_  "DiagRequest" "No";
BA_DEF_DEF_  "DiagResponse" "No";
BA_DEF_DEF_  "GenMsgILSupport" "Yes";
BA_DEF_DEF_  "OvtpOperationMode" "SERVER";
BA_DEF_DEF_  "OvtpEcuAddress" 0;
BA_DEF_DEF_  "ILUsed" "Yes";
BA_DEF_DEF_  "Terminator" "No";
BA_DEF_DEF_  "NodeWakeUpTime" 10;
BA_DEF_DEF_  "NodeStartUpTime" 250;
BA_DEF_DEF_  "NmAsrNodeIdentifier" 128;
BA_DEF_DEF_  "NmAsrNode" "No";
BA_DEF_DEF_  "PowerType" "Switched";
BA_DEF_DEF_  "NmStationAddress" 0;
BA_DEF_DEF_  "NosPackage" "I3_3";
BA_DEF_DEF_  "PackageID" "08.05.00.00.71.xx.xx.rr.00.00";
BA_DEF_DEF_  "GatewayECU" "No";
BA_DEF_DEF_  "NetworkSpeed" "500kBits/s";
BA_DEF_DEF_  "VersionNumber" 1;
BA_DEF_DEF_  "StarNetworkGwType" "0=NotDefined";
BA_DEF_DEF_  "CMDB_Version" "v11.01";
BA_DEF_DEF_  "NmType" "Ford-OSEK";
BA_DEF_DEF_  "NmAsrMessageCount" 128;
BA_DEF_DEF_  "NmAsrBaseAddress" 1408;
BA_DEF_DEF_  "DBName" "";
BA_DEF_DEF_  "VersionDay" 1;
BA_DEF_DEF_  "Manufacturer" "Ford";
BA_DEF_DEF_  "VersionMonth" 1;
BA_DEF_DEF_  "VersionYear" 2011;
BA_DEF_DEF_  "NmBaseAddress" 1280;
BA_DEF_DEF_  "NmMessageCount" 128;
BA_ "StarNetworkGwType" 3;
BA_ "CMDB_Version" "FNV3_v21.01";
BA_ "VersionDay" 22;
BA_ "VersionYear" 2021;
BA_ "BusType" "CAN";
BA_ "DBName" "HS3_CAN";
BA_ "NosPackage" BU_ APIM_CISM 4;
BA_ "PackageID" BU_ APIM_CISM "19.06.07.01.70.02.74.02.00.00";
BA_ "NodeWakeUpTime" BU_ APIM_CISM 150;
BA_ "NodeStartUpTime" BU_ APIM_CISM 1000;
BA_ "NmAsrNodeIdentifier" BU_ APIM_CISM 226;
BA_ "NmAsrNode" BU_ APIM_CISM 1;
BA_ "PowerType" BU_ APIM_CISM 2;
BA_ "NmStationAddress" BU_ APIM_CISM 98;
BA_ "NosPackage" BU_ APIM 4;
BA_ "PackageID" BU_ APIM "19.06.07.01.70.02.74.02.00.00";
BA_ "NodeWakeUpTime" BU_ APIM 150;
BA_ "NodeStartUpTime" BU_ APIM 1000;
BA_ "NmAsrNodeIdentifier" BU_ APIM 226;
BA_ "NmAsrNode" BU_ APIM 1;
BA_ "PowerType" BU_ APIM 2;
BA_ "NmStationAddress" BU_ APIM 98;
BA_ "OvtpEcuAddress" BU_ ESPM 207;
BA_ "NodeWakeUpTime" BU_ ESPM 100;
BA_ "NodeStartUpTime" BU_ ESPM 100;
BA_ "NmAsrNodeIdentifier" BU_ ESPM 108;
BA_ "NmAsrNode" BU_ ESPM 1;
BA_ "PowerType" BU_ ESPM 2;
BA_ "NmStationAddress" BU_ ESPM 108;
BA_ "OvtpEcuAddress" BU_ DSP 9;
BA_ "NodeWakeUpTime" BU_ DSP 150;
BA_ "NmAsrNodeIdentifier" BU_ DSP 198;
BA_ "NmAsrNode" BU_ DSP 1;
BA_ "PowerType" BU_ DSP 2;
BA_ "NmStationAddress" BU_ DSP 70;
BA_ "OvtpEcuAddress" BU_ FCIMB 71;
BA_ "NodeWakeUpTime" BU_ FCIMB 100;
BA_ "NmStationAddress" BU_ FCIMB 210;
BA_ "NodeWakeUpTime" BU_ RACM_RCIM 150;
BA_ "NodeStartUpTime" BU_ RACM_RCIM 1000;
BA_ "NmAsrNodeIdentifier" BU_ RACM_RCIM 152;
BA_ "NmAsrNode" BU_ RACM_RCIM 1;
BA_ "PowerType" BU_ RACM_RCIM 2;
BA_ "NmStationAddress" BU_ RACM_RCIM 24;
BA_ "NodeWakeUpTime" BU_ HUD_ADV 37;
BA_ "NodeStartUpTime" BU_ HUD_ADV 74;
BA_ "NmAsrNodeIdentifier" BU_ HUD_ADV 155;
BA_ "NmAsrNode" BU_ HUD_ADV 1;
BA_ "PowerType" BU_ HUD_ADV 2;
BA_ "NmStationAddress" BU_ HUD_ADV 27;
BA_ "NodeWakeUpTime" BU_ WCM 150;
BA_ "NodeStartUpTime" BU_ WCM 1000;
BA_ "NmAsrNodeIdentifier" BU_ WCM 159;
BA_ "NmAsrNode" BU_ WCM 1;
BA_ "PowerType" BU_ WCM 2;
BA_ "NmStationAddress" BU_ WCM 31;
BA_ "NodeWakeUpTime" BU_ TRM_ITRM 50;
BA_ "NodeStartUpTime" BU_ TRM_ITRM 1000;
BA_ "NmAsrNodeIdentifier" BU_ TRM_ITRM 212;
BA_ "NmAsrNode" BU_ TRM_ITRM 1;
BA_ "PowerType" BU_ TRM_ITRM 2;
BA_ "NmStationAddress" BU_ TRM_ITRM 84;
BA_ "NodeWakeUpTime" BU_ ACM 150;
BA_ "NodeStartUpTime" BU_ ACM 1000;
BA_ "NmAsrNodeIdentifier" BU_ ACM 140;
BA_ "NmAsrNode" BU_ ACM 1;
BA_ "PowerType" BU_ ACM 2;
BA_ "NmStationAddress" BU_ ACM 12;
BA_ "NosPackage" BU_ GWM 4;
BA_ "GatewayECU" BU_ GWM 1;
BA_ "OvtpOperationMode" BU_ GWM 1;
BA_ "OvtpEcuAddress" BU_ GWM 216;
BA_ "Terminator" BU_ GWM 1;
BA_ "NodeWakeUpTime" BU_ GWM 100;
BA_ "NodeStartUpTime" BU_ GWM 100;
BA_ "NmAsrNodeIdentifier" BU_ GWM 158;
BA_ "NmAsrNode" BU_ GWM 1;
BA_ "PowerType" BU_ GWM 2;
BA_ "NmStationAddress" BU_ GWM 30;
BA_ "NodeWakeUpTime" BU_ _delete 100;
BA_ "NosPackage" BU_ IPC 4;
BA_ "OvtpEcuAddress" BU_ IPC 96;
BA_ "Terminator" BU_ IPC 1;
BA_ "NodeWakeUpTime" BU_ IPC 100;
BA_ "NodeStartUpTime" BU_ IPC 1000;
BA_ "NmAsrNodeIdentifier" BU_ IPC 145;
BA_ "NmAsrNode" BU_ IPC 1;
BA_ "PowerType" BU_ IPC 2;
BA_ "NmStationAddress" BU_ IPC 17;
BA_ "NodeWakeUpTime" BU_ GENERIC 100;
BA_ "NodeWakeUpTime" BU_ TSTR 100;
BA_ "FrameRouting" BO_ 1204 "FD1_CAN,0x4B4;";
BA_ "FrameRouting" BO_ 826 "FD3_CAN,0x33A;";
BA_ "FrameRouting" BO_ 1159 "FD2_CAN,0x487;";
BA_ "FrameRouting" BO_ 667 "FD2_CAN,0x29B;";
BA_ "TpTxIndex" BO_ 667 125;
BA_ "TpTxIndex" BO_ 659 125;
BA_ "GenMsgCycleTime" BO_ 645 100;
BA_ "GenMsgSendType" BO_ 645 0;
BA_ "FrameRouting" BO_ 1040 "FD1_CAN,0x410;";
BA_ "GenMsgCycleTime" BO_ 630 100;
BA_ "GenMsgSendType" BO_ 630 0;
BA_ "GenMsgCycleTime" BO_ 627 100;
BA_ "GenMsgSendType" BO_ 627 0;
BA_ "GenMsgCycleTime" BO_ 874 1000;
BA_ "GenMsgSendType" BO_ 874 5;
BA_ "FrameRouting" BO_ 663 "FD1_CAN,0x297;";
BA_ "FrameRouting" BO_ 1161 "HS2_CAN,0x489;";
BA_ "FrameRouting" BO_ 1121 "HS2_CAN,0x461;";
BA_ "FrameRouting" BO_ 669 "FD3_CAN,0x29D;";
BA_ "FrameRouting" BO_ 571 "FD1_CAN,0x23B;";
BA_ "FrameRouting" BO_ 118 "FD1_CAN,0x76;";
BA_ "FrameRouting" BO_ 868 "MS1_CAN,0x364;";
BA_ "FrameRouting" BO_ 836 "MS1_CAN,0x344;";
BA_ "FrameRouting" BO_ 613 "HS2_CAN,0x265;";
BA_ "FrameRouting" BO_ 1084 "FD1_CAN,0x43C;";
BA_ "FrameRouting" BO_ 1059 "FD1_CAN,0x42C;";
BA_ "FrameRouting" BO_ 131 "FD3_CAN,0x83;";
BA_ "FrameRouting" BO_ 931 "FD1_CAN,0x3A3;";
BA_ "FrameRouting" BO_ 618 "FD2_CAN,0x26A;";
BA_ "FrameRouting" BO_ 621 "FD2_CAN,0x26D;";
BA_ "FrameRouting" BO_ 1016 "FD1_CAN,0x3F8;";
BA_ "FrameRouting" BO_ 773 "MS1_CAN,0x305;";
BA_ "FrameRouting" BO_ 389 "FD1_CAN,0x185;";
BA_ "FrameRouting" BO_ 1128 "HS2_CAN,0x45E;";
BA_ "FrameRouting" BO_ 594 "HS2_CAN,0x24C;";
BA_ "NetworkInitialization" BO_ 2614099160 0;
BA_ "GenMsgDelayTime" BO_ 2614099160 0;
BA_ "GenMsgSendType" BO_ 2614099160 1;
BA_ "TpTxIndex" BO_ 2614099160 466615512;
BA_ "NetworkInitialization" BO_ 2610117848 0;
BA_ "GenMsgDelayTime" BO_ 2610117848 0;
BA_ "GenMsgSendType" BO_ 2610117848 1;
BA_ "TpTxIndex" BO_ 2610117848 462634200;
BA_ "NetworkInitialization" BO_ 2610127055 0;
BA_ "GenMsgDelayTime" BO_ 2610127055 0;
BA_ "GenMsgSendType" BO_ 2610127055 1;
BA_ "TpTxIndex" BO_ 2610127055 462634200;
BA_ "NetworkInitialization" BO_ 2611175631 0;
BA_ "GenMsgDelayTime" BO_ 2611175631 0;
BA_ "GenMsgSendType" BO_ 2611175631 1;
BA_ "TpTxIndex" BO_ 2611175631 463682776;
BA_ "NetworkInitialization" BO_ 2612215000 0;
BA_ "GenMsgDelayTime" BO_ 2612215000 0;
BA_ "GenMsgSendType" BO_ 2612215000 1;
BA_ "TpTxIndex" BO_ 2612215000 464731352;
BA_ "OvtpPushApplication" BO_ 2612215000 1;
BA_ "NetworkInitialization" BO_ 2612224207 0;
BA_ "GenMsgDelayTime" BO_ 2612224207 0;
BA_ "GenMsgSendType" BO_ 2612224207 1;
BA_ "TpTxIndex" BO_ 2612224207 464731352;
BA_ "OvtpPushApplication" BO_ 2612224207 1;
BA_ "NetworkInitialization" BO_ 2613263576 0;
BA_ "GenMsgDelayTime" BO_ 2613263576 0;
BA_ "GenMsgSendType" BO_ 2613263576 1;
BA_ "TpTxIndex" BO_ 2613263576 465779928;
BA_ "NetworkInitialization" BO_ 2613272783 0;
BA_ "GenMsgDelayTime" BO_ 2613272783 0;
BA_ "GenMsgSendType" BO_ 2613272783 1;
BA_ "TpTxIndex" BO_ 2613272783 465779928;
BA_ "FrameRouting" BO_ 932 "FD1_CAN,0x3A4;";
BA_ "NetworkInitialization" BO_ 1388 0;
BA_ "GenMsgCycleTime" BO_ 1388 1000;
BA_ "GenMsgSendType" BO_ 1388 0;
BA_ "NmAsrMessage" BO_ 1388 1;
BA_ "GenMsgILSupport" BO_ 1388 0;
BA_ "NetworkInitialization" BO_ 1769 0;
BA_ "GenMsgDelayTime" BO_ 1769 0;
BA_ "GenMsgSendType" BO_ 1769 1;
BA_ "DiagResponse" BO_ 1769 1;
BA_ "NetworkInitialization" BO_ 1761 0;
BA_ "GenMsgDelayTime" BO_ 1761 0;
BA_ "GenMsgSendType" BO_ 1761 1;
BA_ "DiagRequest" BO_ 1761 1;
BA_ "FrameRouting" BO_ 528 "FD1_CAN,0x210;";
BA_ "FrameRouting" BO_ 591 "HS2_CAN,0x24F;";
BA_ "GenMsgCycleTime" BO_ 595 500;
BA_ "GenMsgSendType" BO_ 595 5;
BA_ "FrameRouting" BO_ 596 "FD3_CAN,0x254;";
BA_ "FrameRouting" BO_ 966 "FD1_CAN,0x3C6;";
BA_ "FrameRouting" BO_ 1104 "FD3_CAN,0x450;";
BA_ "FrameRouting" BO_ 303 "FD1_CAN,0x12F;";
BA_ "NetworkInitialization" BO_ 2612224006 0;
BA_ "GenMsgDelayTime" BO_ 2612224006 0;
BA_ "GenMsgSendType" BO_ 2612224006 1;
BA_ "TpTxIndex" BO_ 2612224006 464525528;
BA_ "OvtpPushApplication" BO_ 2612224006 1;
BA_ "NetworkInitialization" BO_ 2612009176 0;
BA_ "GenMsgDelayTime" BO_ 2612009176 0;
BA_ "GenMsgSendType" BO_ 2612009176 1;
BA_ "TpTxIndex" BO_ 2612009176 464525528;
BA_ "OvtpPushApplication" BO_ 2612009176 1;
BA_ "NetworkInitialization" BO_ 2611175430 0;
BA_ "GenMsgDelayTime" BO_ 2611175430 0;
BA_ "GenMsgSendType" BO_ 2611175430 1;
BA_ "TpTxIndex" BO_ 2611175430 463476952;
BA_ "NetworkInitialization" BO_ 2610960600 0;
BA_ "GenMsgDelayTime" BO_ 2610960600 0;
BA_ "GenMsgSendType" BO_ 2610960600 1;
BA_ "TpTxIndex" BO_ 2610960600 463476952;
BA_ "NetworkInitialization" BO_ 2610126854 0;
BA_ "GenMsgDelayTime" BO_ 2610126854 0;
BA_ "GenMsgSendType" BO_ 2610126854 1;
BA_ "TpTxIndex" BO_ 2610126854 462428376;
BA_ "NetworkInitialization" BO_ 2609912024 0;
BA_ "GenMsgDelayTime" BO_ 2609912024 0;
BA_ "GenMsgSendType" BO_ 2609912024 1;
BA_ "TpTxIndex" BO_ 2609912024 462428376;
BA_ "GenMsgCycleTime" BO_ 662 1000;
BA_ "GenMsgSendType" BO_ 662 5;
BA_ "FrameRouting" BO_ 513 "FD1_CAN,0x201;";
BA_ "FrameRouting" BO_ 148 "HS2_CAN,0x91;";
BA_ "FrameRouting" BO_ 1042 "FD1_CAN,0x412;";
BA_ "FrameRouting" BO_ 828 "FD3_CAN,0x33C;";
BA_ "FrameRouting" BO_ 330 "FD1_CAN,0x14A;";
BA_ "FrameRouting" BO_ 512 "FD1_CAN,0x200;";
BA_ "FrameRouting" BO_ 862 "MS1_CAN,0x35E;";
BA_ "FrameRouting" BO_ 831 "FD3_CAN,0x33F;";
BA_ "FrameRouting" BO_ 331 "FD1_CAN,0x14B;";
BA_ "FrameRouting" BO_ 965 "MS1_CAN,0x3C5;";
BA_ "GenMsgCycleTime" BO_ 1242 1000;
BA_ "GenMsgSendType" BO_ 1242 5;
BA_ "GenMsgCycleTime" BO_ 1245 1000;
BA_ "GenMsgSendType" BO_ 1245 5;
BA_ "FrameRouting" BO_ 781 "MS2_CAN,0x30D;";
BA_ "FrameRouting" BO_ 1022 "MS2_CAN,0x3FE;";
BA_ "FrameRouting" BO_ 903 "FD2_CAN,0x387;";
BA_ "FrameRouting" BO_ 901 "FD2_CAN,0x385;";
BA_ "FrameRouting" BO_ 1112 "HS2_CAN,0x458;";
BA_ "FrameRouting" BO_ 977 "MS1_CAN,0x3D1;";
BA_ "GenMsgSendType" BO_ 530 1;
BA_ "GenMsgCycleTime" BO_ 746 1000;
BA_ "GenMsgSendType" BO_ 746 5;
BA_ "GenMsgSendType" BO_ 479 1;
BA_ "GenMsgSendType" BO_ 474 1;
BA_ "GenMsgSendType" BO_ 477 1;
BA_ "GenMsgSendType" BO_ 260 1;
BA_ "GenMsgSendType" BO_ 476 1;
BA_ "GenMsgSendType" BO_ 490 1;
BA_ "NetworkInitialization" BO_ 1916 0;
BA_ "GenMsgDelayTime" BO_ 1916 0;
BA_ "GenMsgSendType" BO_ 1916 1;
BA_ "DiagResponse" BO_ 1916 1;
BA_ "GenMsgILSupport" BO_ 1916 0;
BA_ "NetworkInitialization" BO_ 1908 0;
BA_ "GenMsgDelayTime" BO_ 1908 0;
BA_ "GenMsgSendType" BO_ 1908 1;
BA_ "DiagRequest" BO_ 1908 1;
BA_ "GenMsgILSupport" BO_ 1908 0;
BA_ "NetworkInitialization" BO_ 1432 0;
BA_ "GenMsgCycleTime" BO_ 1432 1000;
BA_ "GenMsgSendType" BO_ 1432 0;
BA_ "NmAsrMessage" BO_ 1432 1;
BA_ "GenMsgILSupport" BO_ 1432 0;
BA_ "NetworkInitialization" BO_ 1923 0;
BA_ "GenMsgDelayTime" BO_ 1923 0;
BA_ "GenMsgSendType" BO_ 1923 1;
BA_ "DiagRequest" BO_ 1923 1;
BA_ "GenMsgILSupport" BO_ 1923 0;
BA_ "NetworkInitialization" BO_ 1931 0;
BA_ "GenMsgDelayTime" BO_ 1931 0;
BA_ "GenMsgSendType" BO_ 1931 1;
BA_ "DiagResponse" BO_ 1931 1;
BA_ "GenMsgILSupport" BO_ 1931 0;
BA_ "FrameRouting" BO_ 896 "FD1_CAN,0x380;";
BA_ "FrameRouting" BO_ 897 "FD1_CAN,0x381;";
BA_ "GenMsgSendType" BO_ 502 1;
BA_ "FrameRouting" BO_ 955 "FD1_CAN,0x3BB;";
BA_ "GenMsgCycleTime" BO_ 1116 1000;
BA_ "GenMsgSendType" BO_ 1116 5;
BA_ "FrameRouting" BO_ 608 "HS2_CAN,0x25F;";
BA_ "FrameRouting" BO_ 1237 "FD1_CAN,0x4D5;FD3_CAN,0x4D5";
BA_ "GenMsgCycleTime" BO_ 838 100;
BA_ "GenMsgSendType" BO_ 838 0;
BA_ "FrameRouting" BO_ 1255 "FD1_CAN,0x4E7;FD3_CAN,0x4E7";
BA_ "FrameRouting" BO_ 1254 "FD1_CAN,0x4E6;FD3_CAN,0x4E6";
BA_ "FrameRouting" BO_ 1253 "FD1_CAN,0x4E5;FD3_CAN,0x4E5";
BA_ "FrameRouting" BO_ 1252 "FD1_CAN,0x4E4;FD3_CAN,0x4E4";
BA_ "FrameRouting" BO_ 1251 "FD1_CAN,0x4E3;FD3_CAN,0x4E3";
BA_ "FrameRouting" BO_ 1250 "FD1_CAN,0x4E2;FD3_CAN,0x4E2";
BA_ "FrameRouting" BO_ 1249 "FD1_CAN,0x4E1;FD3_CAN,0x4E1";
BA_ "FrameRouting" BO_ 1248 "FD1_CAN,0x4E0;FD3_CAN,0x4E0";
BA_ "GenMsgCycleTime" BO_ 529 1000;
BA_ "GenMsgSendType" BO_ 529 5;
BA_ "FrameRouting" BO_ 374 "FD1_CAN,0x176;";
BA_ "GenMsgSendType" BO_ 500 1;
BA_ "GenMsgSendType" BO_ 503 1;
BA_ "WakeupSignal" SG_ 826 Memory_3_Sw_Stat 1;
BA_ "WakeupSignal" SG_ 826 Memory_2_Sw_Stat 1;
BA_ "WakeupSignal" SG_ 826 Memory_1_Sw_Stat 1;
BA_ "WakeupSignal" SG_ 826 Mirror_Manual_Override 1;
BA_ "GenSigStartValue" SG_ 1159 FourthRowBucklePsngr2 4;
BA_ "GenSigStartValue" SG_ 1159 FourthRowBuckleMid2 4;
BA_ "GenSigStartValue" SG_ 1159 FourthRowBuckleDriver2 4;
BA_ "GenSigStartValue" SG_ 1159 ThirdRowBucklePsngr2 4;
BA_ "GenSigStartValue" SG_ 1159 ThirdRowBuckleMid2 4;
BA_ "GenSigStartValue" SG_ 1159 ThirdRowBuckleDriver2 4;
BA_ "GenSigStartValue" SG_ 1159 SecondRowBucklePsngr2 4;
BA_ "GenSigStartValue" SG_ 1159 SecondRowBuckleMid2 4;
BA_ "GenSigStartValue" SG_ 1159 SecondRowBuckleDriver2 4;
BA_ "U_V710_MY2023_Tx" SG_ 645 VehImpactCode_No2_Actl 1;
BA_ "ECGUsedTxSignal" SG_ 645 VehImpactCode_No2_Actl 1;
BA_ "U_P708_MY2023_Rx" SG_ 1040 VehSimSnd_Pc_Rq 1;
BA_ "GenSigStartValue" SG_ 1040 VehSimSnd_Pc_Rq 511;
BA_ "GenSigStartValue" SG_ 1040 BattTrac_I2_EstVsc 262142;
BA_ "GenSigStartValue" SG_ 630 TrfcLghtRight_T_Actl 254;
BA_ "GenSigStartValue" SG_ 630 TrfcLghtLeft_T_Actl 254;
BA_ "GenSigStartValue" SG_ 627 VehToInfrstrctr_D_Stat 6;
BA_ "GenSigStartValue" SG_ 627 RoadStopLine_L_Est 65534;
BA_ "GenSigStartValue" SG_ 627 TrfcLghtDecel_A_Dsply 126;
BA_ "GenSigStartValue" SG_ 627 TrfcLght_V_Mx 254;
BA_ "GenSigStartValue" SG_ 627 TrfcLght_V_Mn 254;
BA_ "GenSigSendType" SG_ 874 E_Rr_Btn_Status_2nd 3;
BA_ "GenSigSendType" SG_ 874 E_Rr_Btn_Status_1st 3;
BA_ "GenSigSendType" SG_ 874 E_Frt_Btn_Status_2nd 3;
BA_ "GenSigSendType" SG_ 874 E_Frt_Btn_Status_1st 3;
BA_ "GenSigStartValue" SG_ 663 BptDchrg_Pw_Dsply 1022;
BA_ "GenSigStartValue" SG_ 663 Bpt_I_Est 1022;
BA_ "GenSigStartValue" SG_ 663 Bpt_Pw_Allw 65534;
BA_ "GenSigStartValue" SG_ 663 BptDchrg_T_Rmng 32766;
BA_ "GenSigStartValue" SG_ 663 BptMnSoc_L_Actl 8190;
BA_ "GenSigStartValue" SG_ 1161 BattTracUMxArry_No_Actl 31;
BA_ "GenSigStartValue" SG_ 1161 BattTracCellUMx_No_Actl 254;
BA_ "GenSigStartValue" SG_ 1161 BattTracCellUMn_No_Actl 254;
BA_ "GenSigStartValue" SG_ 1161 BattTracCellCnt_No_Actl 254;
BA_ "GenSigStartValue" SG_ 1161 BattTracTeMx_No_Actl 254;
BA_ "GenSigStartValue" SG_ 1161 BattTracTeMn_No_Actl 254;
BA_ "GenSigStartValue" SG_ 1161 BattTracTeCnt_No_Actl 254;
BA_ "GenSigStartValue" SG_ 1121 OffRdSwtch_D_RqMnu 2;
BA_ "U_P708_MY2023_Rx" SG_ 669 DrHandleOuterRr_D_Stat 1;
BA_ "U_P708_MY2023_Rx" SG_ 669 DrHandleOuterFr_D_Stat 1;
BA_ "GenSigStartValue" SG_ 571 VehFalr_Pc_Est 126;
BA_ "GenSigStartValue" SG_ 571 TrlrTngLoad_Pc_Est 126;
BA_ "GenSigStartValue" SG_ 571 TrlrTngLoad_M_Est 2046;
BA_ "GenSigStartValue" SG_ 571 VehPayloadAdd_M_Est 2046;
BA_ "GenSigStartValue" SG_ 571 VehPayload_Pc_Est 126;
BA_ "GenSigStartValue" SG_ 571 VehPayload_M_Est 1022;
BA_ "MetaData" SG_ 118 ApaBrkErrDStat_No_Cs 1;
BA_ "MetaData" SG_ 118 ApaBrkErrDStat_No_Cnt 1;
BA_ "GenSigStartValue" SG_ 118 ApaBrkErr_D_Stat 2;
BA_ "U_P708_MY2023_Rx" SG_ 118 SteWhlCompAnEst_D_Qf 1;
BA_ "U_V713AV_MY2022_Rx" SG_ 118 SteWhlCompAnEst_D_Qf 1;
BA_ "U_V713N_MY2022_Rx" SG_ 118 SteWhlCompAnEst_D_Qf 1;
BA_ "MetaData" SG_ 118 SteWhlCompAnEst_D_Qf 1;
BA_ "U_P708_MY2023_Rx" SG_ 118 SteWhlComp_An_Est 1;
BA_ "U_V713AV_MY2022_Rx" SG_ 118 SteWhlComp_An_Est 1;
BA_ "U_V713N_MY2022_Rx" SG_ 118 SteWhlComp_An_Est 1;
BA_ "GenSigStartValue" SG_ 868 Rr_Blower_Indicate_Stat 15;
BA_ "WakeupSignal" SG_ 836 HvacPrecondMode_D_Rq 1;
BA_ "WakeupSignal" SG_ 836 HvacPrecondBlwr_D_Rq 1;
BA_ "WakeupSignal" SG_ 836 Foh_D_Stat 1;
BA_ "U_V710_MY2023_Rx" SG_ 836 FuelFlw_Vl_ActlFoh 1;
BA_ "U_P708_MY2023_Rx" SG_ 836 FuelFlw_Vl_ActlFoh 1;
BA_ "U_V713AV_MY2022_Rx" SG_ 836 FuelFlw_Vl_ActlFoh 1;
BA_ "U_V713N_MY2022_Rx" SG_ 836 FuelFlw_Vl_ActlFoh 1;
BA_ "GenSigStartValue" SG_ 613 BeltWarnThres_D_Stat 6;
BA_ "U_V710_MY2023_Rx" SG_ 613 ObjectEntrapped 1;
BA_ "U_P708_MY2023_Rx" SG_ 613 ObjectEntrapped 1;
BA_ "U_V713AV_MY2022_Rx" SG_ 613 ObjectEntrapped 1;
BA_ "U_V713N_MY2022_Rx" SG_ 613 ObjectEntrapped 1;
BA_ "GenSigStartValue" SG_ 1084 BattULoChrg_URate_RqMx 5;
BA_ "GenSigStartValue" SG_ 1084 BattULoChrg_U_RqMx 34;
BA_ "GenSigStartValue" SG_ 1084 BattULo2_Te_Actl 127;
BA_ "U_V710_MY2023_Rx" SG_ 1059 PwSysULoFalt_D_Stat 1;
BA_ "U_P708_MY2023_Rx" SG_ 1059 PwSysULoFalt_D_Stat 1;
BA_ "U_V713AV_MY2022_Rx" SG_ 1059 PwSysULoFalt_D_Stat 1;
BA_ "U_V713N_MY2022_Rx" SG_ 1059 PwSysULoFalt_D_Stat 1;
BA_ "WakeupSignal" SG_ 1059 PwSysULoFalt_D_Stat 1;
BA_ "U_V710_MY2023_Rx" SG_ 1059 Shed_Feature_Group_ID 1;
BA_ "U_P708_MY2023_Rx" SG_ 1059 Shed_Feature_Group_ID 1;
BA_ "WakeupSignal" SG_ 1059 Shed_Feature_Group_ID 1;
BA_ "U_V710_MY2023_Rx" SG_ 1059 Shed_Level_Req 1;
BA_ "U_P708_MY2023_Rx" SG_ 1059 Shed_Level_Req 1;
BA_ "U_V713AV_MY2022_Rx" SG_ 1059 Shed_Level_Req 1;
BA_ "U_V713N_MY2022_Rx" SG_ 1059 Shed_Level_Req 1;
BA_ "WakeupSignal" SG_ 1059 Shed_Level_Req 1;
BA_ "U_P708_MY2023_Rx" SG_ 1059 Batt_Lo_SoC_B 1;
BA_ "U_V713AV_MY2022_Rx" SG_ 1059 Batt_Lo_SoC_B 1;
BA_ "U_V713N_MY2022_Rx" SG_ 1059 Batt_Lo_SoC_B 1;
BA_ "U_V710_MY2023_Rx" SG_ 1059 Batt_Crit_SoC_B 1;
BA_ "U_P708_MY2023_Rx" SG_ 1059 Batt_Crit_SoC_B 1;
BA_ "U_V713AV_MY2022_Rx" SG_ 1059 Batt_Crit_SoC_B 1;
BA_ "U_V713N_MY2022_Rx" SG_ 1059 Batt_Crit_SoC_B 1;
BA_ "WakeupSignal" SG_ 131 HeadLghtHiCtrl_D_RqAhb 1;
BA_ "U_V710_MY2023_Rx" SG_ 131 AhbStat_B_Dsply 1;
BA_ "U_P708_MY2023_Rx" SG_ 131 AhbStat_B_Dsply 1;
BA_ "U_V713AV_MY2022_Rx" SG_ 131 AhbStat_B_Dsply 1;
BA_ "U_V713N_MY2022_Rx" SG_ 131 AhbStat_B_Dsply 1;
BA_ "GenSigStartValue" SG_ 131 WiprFrontSwtch_D_Stat 9;
BA_ "U_V710_MY2023_Rx" SG_ 131 HeadLghtHiOn_B_StatAhb 1;
BA_ "U_P708_MY2023_Rx" SG_ 131 HeadLghtHiOn_B_StatAhb 1;
BA_ "U_V713AV_MY2022_Rx" SG_ 131 HeadLghtHiOn_B_StatAhb 1;
BA_ "U_V713N_MY2022_Rx" SG_ 131 HeadLghtHiOn_B_StatAhb 1;
BA_ "WakeupSignal" SG_ 131 HeadLghtHiOn_B_StatAhb 1;
BA_ "GenSigStartValue" SG_ 131 WiprFront_D_Stat 15;
BA_ "U_V710_MY2023_Rx" SG_ 131 TurnLghtSwtch_D_Stat 1;
BA_ "U_P708_MY2023_Rx" SG_ 131 TurnLghtSwtch_D_Stat 1;
BA_ "U_V713AV_MY2022_Rx" SG_ 131 TurnLghtSwtch_D_Stat 1;
BA_ "U_V713N_MY2022_Rx" SG_ 131 TurnLghtSwtch_D_Stat 1;
BA_ "WakeupSignal" SG_ 131 TurnLghtSwtch_D_Stat 1;
BA_ "GenSigStartValue" SG_ 131 LghtAmb_D_Sns 7;
BA_ "U_P708_MY2023_Rx" SG_ 931 VehOnSrc_D_Stat 1;
BA_ "MetaData" SG_ 931 StrtrMtrCtlDStat_No_Cs 1;
BA_ "MetaData" SG_ 931 CrnkInhbt_No_Cs 1;
BA_ "MetaData" SG_ 931 CrnkInhbt_No_Cnt 1;
BA_ "GenSigStartValue" SG_ 931 CrnkInhbt_B_Stat 1;
BA_ "WakeupSignal" SG_ 618 PaakLoclzd_D_Stat 1;
BA_ "WakeupSignal" SG_ 618 PaakCtlType_D_Stat 1;
BA_ "WakeupSignal" SG_ 618 PaakCtlRollCode_No_Stat 1;
BA_ "WakeupSignal" SG_ 618 PaakCtlPssvData_No_Actl 1;
BA_ "WakeupSignal" SG_ 618 PaakCtlData_D_Stat 1;
BA_ "MetaData" SG_ 1016 ChrgGoTNext_D_Stat 1;
BA_ "MetaData" SG_ 1016 ChrgGoTMnte_D_Stat 1;
BA_ "GenSigStartValue" SG_ 1016 ChrgGoTHr_T_Stat 30;
BA_ "MetaData" SG_ 1016 ChrgGoTElement_D_Stat 1;
BA_ "U_V710_MY2023_Rx" SG_ 389 HtrnSrvcRqd_B_Dsply 1;
BA_ "U_V713AV_MY2022_Rx" SG_ 389 HtrnSrvcRqd_B_Dsply 1;
BA_ "U_V713N_MY2022_Rx" SG_ 389 HtrnSrvcRqd_B_Dsply 1;
BA_ "U_V710_MY2023_Rx" SG_ 389 HtrnOvrTeLamp_B_Dsply 1;
BA_ "U_V713AV_MY2022_Rx" SG_ 389 HtrnOvrTeLamp_B_Dsply 1;
BA_ "U_V713N_MY2022_Rx" SG_ 389 HtrnOvrTeLamp_B_Dsply 1;
BA_ "GenSigStartValue" SG_ 1128 ChrgrPncEnbl_D_Stat 3;
BA_ "U_V710_MY2023_Rx" SG_ 1128 ChrgrSrvcRqd_B_Rq 1;
BA_ "U_P708_MY2023_Rx" SG_ 1128 ChrgrSrvcRqd_B_Rq 1;
BA_ "U_V713AV_MY2022_Rx" SG_ 1128 ChrgrSrvcRqd_B_Rq 1;
BA_ "U_V713N_MY2022_Rx" SG_ 1128 ChrgrSrvcRqd_B_Rq 1;
BA_ "U_V710_MY2023_Rx" SG_ 1128 ChrgPortDrOpen_B_Stat 1;
BA_ "U_P708_MY2023_Rx" SG_ 1128 ChrgPortDrOpen_B_Stat 1;
BA_ "U_V713AV_MY2022_Rx" SG_ 1128 ChrgPortDrOpen_B_Stat 1;
BA_ "U_V713N_MY2022_Rx" SG_ 1128 ChrgPortDrOpen_B_Stat 1;
BA_ "U_P708_MY2023_Rx" SG_ 1128 ChrgCrdLck_D_Falt 1;
BA_ "U_V713AV_MY2022_Rx" SG_ 1128 ChrgCrdLck_D_Falt 1;
BA_ "U_V713N_MY2022_Rx" SG_ 1128 ChrgCrdLck_D_Falt 1;
BA_ "WakeupSignal" SG_ 594 HvacAirFlw_B_RqBatt 1;
BA_ "U_V710_MY2023_Rx" SG_ 594 BattTracSoc_Pc_Dsply 1;
BA_ "U_P708_MY2023_Rx" SG_ 594 BattTracSoc_Pc_Dsply 1;
BA_ "U_V713AV_MY2022_Rx" SG_ 594 BattTracSoc_Pc_Dsply 1;
BA_ "U_V713N_MY2022_Rx" SG_ 594 BattTracSoc_Pc_Dsply 1;
BA_ "GenSigStartValue" SG_ 594 BattTracSoc_Pc_Dsply 254;
BA_ "GenSigStartValue" SG_ 594 BattTracSoc2_Pc_Actl 16382;
BA_ "GenSigStartValue" SG_ 594 BattTracClntIn_Te_Actl 75;
BA_ "GenSigStartValue" SG_ 594 BattTrac_Te_Actl 150;
BA_ "GenSigStartValue" SG_ 594 HvacRec_D_RqMxBatt 10;
BA_ "U_V710_MY2023_Tx" SG_ 2614099160 SymKeyFuncGWM_ECG 1;
BA_ "U_P708_MY2023_Tx" SG_ 2614099160 SymKeyFuncGWM_ECG 1;
BA_ "ECGUsedTxSignal" SG_ 2614099160 SymKeyFuncGWM_ECG 1;
BA_ "U_P708_MY2023_Rx" SG_ 2614099160 SymKeyFuncGWM_ECG 1;
BA_ "U_V713AV_MY2022_Rx" SG_ 2614099160 SymKeyFuncGWM_ECG 1;
BA_ "GenSigSendType" SG_ 2614099160 SymKeyFuncGWM_ECG 3;
BA_ "ECGUsedTxSignal" SG_ 2610117848 OTAPhysGWM_ECGtoESPM 1;
BA_ "U_V713AV_MY2022_Rx" SG_ 2610117848 OTAPhysGWM_ECGtoESPM 1;
BA_ "GenSigSendType" SG_ 2610117848 OTAPhysGWM_ECGtoESPM 3;
BA_ "U_V713AV_MY2022_Tx" SG_ 2610127055 OTAPhysESPMtoGWM_ECG 1;
BA_ "ECGUsedRxSignal" SG_ 2610127055 OTAPhysESPMtoGWM_ECG 1;
BA_ "GenSigSendType" SG_ 2610127055 OTAPhysESPMtoGWM_ECG 3;
BA_ "U_V713AV_MY2022_Tx" SG_ 2611175631 PARSEDPhysESPMtoGWM_ECG 1;
BA_ "ECGUsedRxSignal" SG_ 2611175631 PARSEDPhysESPMtoGWM_ECG 1;
BA_ "GenSigSendType" SG_ 2611175631 PARSEDPhysESPMtoGWM_ECG 3;
BA_ "ECGUsedTxSignal" SG_ 2612215000 PARSEDPushFcGWM_ECGtoESPM 1;
BA_ "U_V713AV_MY2022_Rx" SG_ 2612215000 PARSEDPushFcGWM_ECGtoESPM 1;
BA_ "GenSigSendType" SG_ 2612215000 PARSEDPushFcGWM_ECGtoESPM 3;
BA_ "U_V713AV_MY2022_Tx" SG_ 2612224207 PARSEDPushESPMoGWM_ECG 1;
BA_ "U_V713AV_MY2022_Rx" SG_ 2612224207 PARSEDPushESPMoGWM_ECG 1;
BA_ "GenSigSendType" SG_ 2612224207 PARSEDPushESPMoGWM_ECG 3;
BA_ "ECGUsedTxSignal" SG_ 2613263576 SymKeyPhysGWM_ECGtoESPM 1;
BA_ "U_V713AV_MY2022_Rx" SG_ 2613263576 SymKeyPhysGWM_ECGtoESPM 1;
BA_ "GenSigSendType" SG_ 2613263576 SymKeyPhysGWM_ECGtoESPM 3;
BA_ "U_V713AV_MY2022_Tx" SG_ 2613272783 SymKeyPhysESPMtoGWM_ECG 1;
BA_ "ECGUsedRxSignal" SG_ 2613272783 SymKeyPhysESPMtoGWM_ECG 1;
BA_ "GenSigSendType" SG_ 2613272783 SymKeyPhysESPMtoGWM_ECG 3;
BA_ "U_V713AV_MY2022_Rx" SG_ 932 VehStrtInhbt_D_Stat 1;
BA_ "U_V713AV_MY2022_Rx" SG_ 932 VehOnSrc2_D_Stat 1;
BA_ "MetaData" SG_ 932 CanMsg3A4_No_Crc 1;
BA_ "MetaData" SG_ 932 CanMsg3A4_No_Cnt 1;
BA_ "U_V713AV_MY2022_Tx" SG_ 1388 ESPM_GWOnBoardTester 1;
BA_ "GenSigStartValue" SG_ 1388 ESPM_GWOnBoardTester 255;
BA_ "U_V713AV_MY2022_Tx" SG_ 1388 ESPM_GWNMProxy 1;
BA_ "GenSigStartValue" SG_ 1388 ESPM_GWNMProxy 255;
BA_ "U_V713AV_MY2022_Tx" SG_ 1388 ESPM_AutoSarNMReserved4 1;
BA_ "GenSigStartValue" SG_ 1388 ESPM_AutoSarNMReserved4 255;
BA_ "U_V713AV_MY2022_Tx" SG_ 1388 ESPM_AutoSarNMReserved3 1;
BA_ "GenSigStartValue" SG_ 1388 ESPM_AutoSarNMReserved3 255;
BA_ "U_V713AV_MY2022_Tx" SG_ 1388 ESPM_AutoSarNMReserved2 1;
BA_ "GenSigStartValue" SG_ 1388 ESPM_AutoSarNMReserved2 255;
BA_ "U_V713AV_MY2022_Tx" SG_ 1388 ESPM_AutoSarNMReserved1 1;
BA_ "GenSigStartValue" SG_ 1388 ESPM_AutoSarNMReserved1 255;
BA_ "U_V713AV_MY2022_Tx" SG_ 1388 ESPM_AutoSarNMNodeId 1;
BA_ "GenSigStartValue" SG_ 1388 ESPM_AutoSarNMNodeId 108;
BA_ "U_V713AV_MY2022_Tx" SG_ 1388 ESPM_AutoSarNMControl 1;
BA_ "U_V713AV_MY2022_Tx" SG_ 1769 TesterPhysicalResESPM 1;
BA_ "GenSigSendType" SG_ 1769 TesterPhysicalResESPM 3;
BA_ "U_V713AV_MY2022_Rx" SG_ 1761 TesterPhysicalReqESPM 1;
BA_ "GenSigSendType" SG_ 1761 TesterPhysicalReqESPM 3;
BA_ "GenSigStartValue" SG_ 528 TireRear_P_OffRoad2 255;
BA_ "GenSigStartValue" SG_ 528 TireRear_P_OffRoad1 255;
BA_ "GenSigStartValue" SG_ 528 TireFront_P_OffRoad2 255;
BA_ "GenSigStartValue" SG_ 528 TireFront_P_OffRoad1 255;
BA_ "GenSigStartValue" SG_ 591 BattTrac_U_Nom 1022;
BA_ "GenSigStartValue" SG_ 591 BattTrac_E_Nom 4094;
BA_ "GenSigStartValue" SG_ 591 BattTrac_Ah_Nom 4093;
BA_ "GenSigStartValue" SG_ 591 BattTracType_D_Actl 8;
BA_ "GenSigStartValue" SG_ 591 BattChrgRqd_E_Actl 4094;
BA_ "GenSigSendType" SG_ 595 DrvIdMde_D_Rq 3;
BA_ "GenSigStartValue" SG_ 595 DrvIdMde_D_Rq 1;
BA_ "GenSigSendType" SG_ 595 DrvIdDelete_No_Rq 3;
BA_ "MetaData" SG_ 596 DrvId_No_Cs 1;
BA_ "WakeupSignal" SG_ 966 TrunkFrontOpen_No_Actl 1;
BA_ "WakeupSignal" SG_ 966 TrunkFrontRolCd_No_Actl 1;
BA_ "WakeupSignal" SG_ 966 VehHorn_D_RqAlrt 1;
BA_ "WakeupSignal" SG_ 966 VehHorn_D_Rq 1;
BA_ "WakeupSignal" SG_ 966 ScrtyHornActv_B_Rq 1;
BA_ "MetaData" SG_ 1104 DrvEngageLevel_No_Cs 1;
BA_ "MetaData" SG_ 1104 DrvEngageLevel_No_Cnt 1;
BA_ "ContentDependant" SG_ 303 CanMsg12F_No_Crc 1;
BA_ "MetaData" SG_ 303 CanMsg12F_No_Crc 1;
BA_ "ContentDependant" SG_ 303 CanMsg12F_No_Cnt 1;
BA_ "MetaData" SG_ 303 CanMsg12F_No_Cnt 1;
BA_ "U_V710_MY2023_Rx" SG_ 303 DrStatHood_D2_Actl 1;
BA_ "U_P708_MY2023_Rx" SG_ 303 DrStatHood_D2_Actl 1;
BA_ "WakeupSignal" SG_ 303 DrStatHood_D2_Actl 1;
BA_ "U_P708_MY2023_Tx" SG_ 2612224006 PARSEDPushHUDtoGWM_ECG 1;
BA_ "U_P708_MY2023_Rx" SG_ 2612224006 PARSEDPushHUDtoGWM_ECG 1;
BA_ "ECGUsedRxSignal" SG_ 2612224006 PARSEDPushHUDtoGWM_ECG 1;
BA_ "GenSigSendType" SG_ 2612224006 PARSEDPushHUDtoGWM_ECG 3;
BA_ "U_P708_MY2023_Tx" SG_ 2612009176 PARSEDPushFcGWM_ECGtoHUD 1;
BA_ "ECGUsedTxSignal" SG_ 2612009176 PARSEDPushFcGWM_ECGtoHUD 1;
BA_ "U_P708_MY2023_Rx" SG_ 2612009176 PARSEDPushFcGWM_ECGtoHUD 1;
BA_ "GenSigSendType" SG_ 2612009176 PARSEDPushFcGWM_ECGtoHUD 3;
BA_ "U_P708_MY2023_Tx" SG_ 2611175430 PARSEDPhysHUDtoGWM_ECG 1;
BA_ "U_P708_MY2023_Rx" SG_ 2611175430 PARSEDPhysHUDtoGWM_ECG 1;
BA_ "ECGUsedRxSignal" SG_ 2611175430 PARSEDPhysHUDtoGWM_ECG 1;
BA_ "GenSigSendType" SG_ 2611175430 PARSEDPhysHUDtoGWM_ECG 3;
BA_ "U_P708_MY2023_Tx" SG_ 2610960600 PARSEDPhysGWM_ECGtoHUD 1;
BA_ "ECGUsedTxSignal" SG_ 2610960600 PARSEDPhysGWM_ECGtoHUD 1;
BA_ "U_P708_MY2023_Rx" SG_ 2610960600 PARSEDPhysGWM_ECGtoHUD 1;
BA_ "GenSigSendType" SG_ 2610960600 PARSEDPhysGWM_ECGtoHUD 3;
BA_ "U_P708_MY2023_Tx" SG_ 2610126854 OTAPhysHUDtoGWM_ECG 1;
BA_ "U_P708_MY2023_Rx" SG_ 2610126854 OTAPhysHUDtoGWM_ECG 1;
BA_ "ECGUsedRxSignal" SG_ 2610126854 OTAPhysHUDtoGWM_ECG 1;
BA_ "GenSigSendType" SG_ 2610126854 OTAPhysHUDtoGWM_ECG 3;
BA_ "U_P708_MY2023_Tx" SG_ 2609912024 OTAPhysGWM_ECGtoHUD 1;
BA_ "ECGUsedTxSignal" SG_ 2609912024 OTAPhysGWM_ECGtoHUD 1;
BA_ "U_P708_MY2023_Rx" SG_ 2609912024 OTAPhysGWM_ECGtoHUD 1;
BA_ "GenSigSendType" SG_ 2609912024 OTAPhysGWM_ECGtoHUD 3;
BA_ "GenSigSendType" SG_ 662 Third_Rear_Set_Temp 3;
BA_ "GenSigSendType" SG_ 662 Third_Rear_Blower_Speed 3;
BA_ "GenSigSendType" SG_ 662 Rear_Temp 3;
BA_ "GenSigSendType" SG_ 662 Rear_Set_Temp 3;
BA_ "GenSigSendType" SG_ 662 Rear_Blower_Speed 3;
BA_ "GenSigSendType" SG_ 662 Running_Board_Cmd2 3;
BA_ "U_V710_MY2023_Rx" SG_ 513 BattTracTeColr_D_Dsply 1;
BA_ "U_V710_MY2023_Rx" SG_ 513 MtrTracTeColr_D_Dsply 1;
BA_ "U_V710_MY2023_Rx" SG_ 513 MtrTracTe_Pc_Dsply 1;
BA_ "U_V710_MY2023_Rx" SG_ 513 BattTracTe_Pc_Dsply 1;
BA_ "U_V710_MY2023_Rx" SG_ 513 ChrgStat_D3_Dsply 1;
BA_ "WakeupSignal" SG_ 513 ChrgStat_D3_Dsply 1;
BA_ "GenSigStartValue" SG_ 148 VehYawWActl_D_Qf 1;
BA_ "MetaData" SG_ 148 VehYawWActl_D_Qf 1;
BA_ "GenSigStartValue" SG_ 148 VehRolWActl_D_Qf 1;
BA_ "MetaData" SG_ 148 VehRolWActl_D_Qf 1;
BA_ "MetaData" SG_ 148 VehRollYawW_No_Cs 1;
BA_ "MetaData" SG_ 148 VehRollYaw_No_Cnt 1;
BA_ "U_P708_MY2023_Rx" SG_ 148 VehYaw_W_Actl 1;
BA_ "U_V713AV_MY2022_Rx" SG_ 148 VehYaw_W_Actl 1;
BA_ "U_V713N_MY2022_Rx" SG_ 148 VehYaw_W_Actl 1;
BA_ "GenSigStartValue" SG_ 148 VehYaw_W_Actl 65534;
BA_ "GenSigStartValue" SG_ 148 VehRol_W_Actl 65534;
BA_ "U_P708_MY2023_Rx" SG_ 1042 VehRol_An_Dsply 1;
BA_ "U_V713AV_MY2022_Rx" SG_ 1042 VehRol_An_Dsply 1;
BA_ "U_V713N_MY2022_Rx" SG_ 1042 VehRol_An_Dsply 1;
BA_ "U_P708_MY2023_Rx" SG_ 1042 VehPtch_An_Dsply 1;
BA_ "U_V713AV_MY2022_Rx" SG_ 1042 VehPtch_An_Dsply 1;
BA_ "U_V713N_MY2022_Rx" SG_ 1042 VehPtch_An_Dsply 1;
BA_ "U_P708_MY2023_Rx" SG_ 1042 TrlrBrk_Pc_Rq 1;
BA_ "U_V713AV_MY2022_Rx" SG_ 1042 TrlrBrk_Pc_Rq 1;
BA_ "U_V713N_MY2022_Rx" SG_ 1042 TrlrBrk_Pc_Rq 1;
BA_ "U_V710_MY2023_Rx" SG_ 828 RearPassWindowPos 1;
BA_ "U_P708_MY2023_Rx" SG_ 828 RearPassWindowPos 1;
BA_ "U_V713AV_MY2022_Rx" SG_ 828 RearPassWindowPos 1;
BA_ "U_V713N_MY2022_Rx" SG_ 828 RearPassWindowPos 1;
BA_ "WakeupSignal" SG_ 828 RearPassWindowPos 1;
BA_ "U_V713AV_MY2022_Rx" SG_ 828 PassWindowPosition 1;
BA_ "U_V710_MY2023_Rx" SG_ 828 PassWindowPosition 1;
BA_ "U_P708_MY2023_Rx" SG_ 828 PassWindowPosition 1;
BA_ "U_V713N_MY2022_Rx" SG_ 828 PassWindowPosition 1;
BA_ "WakeupSignal" SG_ 828 PassWindowPosition 1;
BA_ "U_V710_MY2023_Rx" SG_ 330 TrnAout_W_ActlUnfilt 1;
BA_ "U_V713AV_MY2022_Rx" SG_ 330 TrnAout_W_ActlUnfilt 1;
BA_ "U_V713N_MY2022_Rx" SG_ 330 TrnAout_W_ActlUnfilt 1;
BA_ "U_P708_MY2023_Rx" SG_ 512 PtDrvMde_D_Stat 1;
BA_ "U_V713AV_MY2022_Rx" SG_ 512 PtDrvMde_D_Stat 1;
BA_ "U_V713N_MY2022_Rx" SG_ 512 PtDrvMde_D_Stat 1;
BA_ "MetaData" SG_ 512 PrplWhlTotTqRq_No_Cs 1;
BA_ "MetaData" SG_ 512 PrplWhlTotTqRq_No_Cnt 1;
BA_ "MetaData" SG_ 862 ApaSwtch_No_Cnt 1;
BA_ "U_V710_MY2023_Rx" SG_ 862 HvacBlwrFront_D_Stat 1;
BA_ "U_P708_MY2023_Rx" SG_ 862 HvacBlwrFront_D_Stat 1;
BA_ "U_V713N_MY2022_Rx" SG_ 862 HvacBlwrFront_D_Stat 1;
BA_ "U_V710_MY2023_Rx" SG_ 862 HvacBlwrRear_D_Stat 1;
BA_ "U_P708_MY2023_Rx" SG_ 862 HvacBlwrRear_D_Stat 1;
BA_ "U_V713N_MY2022_Rx" SG_ 862 HvacBlwrRear_D_Stat 1;
BA_ "GenSigStartValue" SG_ 862 ClimtThrmlLoad_No_Actl 255;
BA_ "ECGUsedRxSignal" SG_ 862 CabnAmb_Te_Actl 1;
BA_ "U_V710_MY2023_Rx" SG_ 862 CabnAmb_Te_Actl 1;
BA_ "U_P708_MY2023_Rx" SG_ 862 CabnAmb_Te_Actl 1;
BA_ "U_V713AV_MY2022_Rx" SG_ 862 CabnAmb_Te_Actl 1;
BA_ "U_V713N_MY2022_Rx" SG_ 862 CabnAmb_Te_Actl 1;
BA_ "WakeupSignal" SG_ 831 PassMirrorCmd 1;
BA_ "WakeupSignal" SG_ 831 RearPassWindowCmd 1;
BA_ "WakeupSignal" SG_ 831 PassWindowCmd 1;
BA_ "U_V710_MY2023_Rx" SG_ 831 RearDriverWindowPos 1;
BA_ "U_P708_MY2023_Rx" SG_ 831 RearDriverWindowPos 1;
BA_ "U_V713AV_MY2022_Rx" SG_ 831 RearDriverWindowPos 1;
BA_ "U_V713N_MY2022_Rx" SG_ 831 RearDriverWindowPos 1;
BA_ "WakeupSignal" SG_ 831 RearDriverWindowPos 1;
BA_ "U_V710_MY2023_Rx" SG_ 831 DriverWindowPosition 1;
BA_ "U_P708_MY2023_Rx" SG_ 831 DriverWindowPosition 1;
BA_ "U_V713AV_MY2022_Rx" SG_ 831 DriverWindowPosition 1;
BA_ "U_V713N_MY2022_Rx" SG_ 831 DriverWindowPosition 1;
BA_ "WakeupSignal" SG_ 831 DriverWindowPosition 1;
BA_ "MetaData" SG_ 331 TrnAout2ActUflt_No_Cnt 1;
BA_ "MetaData" SG_ 331 TrnAout2ActlUflt_No_Cs 1;
BA_ "U_V710_MY2023_Rx" SG_ 331 TrnAout2_W_ActlUnfilt 1;
BA_ "GenSigStartValue" SG_ 331 TrnAout2_W_ActlUnfilt 65534;
BA_ "U_V710_MY2023_Rx" SG_ 965 TrnkFrontEmgcy_D_Stat 1;
BA_ "GenSigStartValue" SG_ 965 TrnkFrontEmgcy_D_Stat 3;
BA_ "WakeupSignal" SG_ 965 TrnkFrontEmgcy_D_Stat 1;
BA_ "WakeupSignal" SG_ 965 PtWakeupActv4_B_Rq 1;
BA_ "GenSigStartValue" SG_ 965 TrunkFrontOpen_D_Stat 2;
BA_ "WakeupSignal" SG_ 965 TrunkFrontOpen_D_Stat 1;
BA_ "WakeupSignal" SG_ 965 TrunkFrontRolCd_No_Locl 1;
BA_ "U_V710_MY2023_Tx" SG_ 1242 EngExhMdeQuietCstm_D_Rq 1;
BA_ "ECGUsedTxSignal" SG_ 1242 EngExhMdeQuietCstm_D_Rq 1;
BA_ "U_P708_MY2023_Rx" SG_ 1242 EngExhMdeQuietCstm_D_Rq 1;
BA_ "GenSigSendType" SG_ 1242 EngExhMdeQuietCstm_D_Rq 3;
BA_ "U_V710_MY2023_Tx" SG_ 1242 StopStrtCstm_D_Rq 1;
BA_ "ECGUsedTxSignal" SG_ 1242 StopStrtCstm_D_Rq 1;
BA_ "U_P708_MY2023_Rx" SG_ 1242 StopStrtCstm_D_Rq 1;
BA_ "GenSigSendType" SG_ 1242 StopStrtCstm_D_Rq 3;
BA_ "U_V710_MY2023_Tx" SG_ 1242 SelDrvMdeCstmPt_D_Rq 1;
BA_ "ECGUsedTxSignal" SG_ 1242 SelDrvMdeCstmPt_D_Rq 1;
BA_ "GenSigSendType" SG_ 1242 SelDrvMdeCstmPt_D_Rq 3;
BA_ "U_V710_MY2023_Tx" SG_ 1245 RearDiffLckLamp_D_Cstm 1;
BA_ "ECGUsedTxSignal" SG_ 1245 RearDiffLckLamp_D_Cstm 1;
BA_ "U_P708_MY2023_Rx" SG_ 1245 RearDiffLckLamp_D_Cstm 1;
BA_ "GenSigSendType" SG_ 1245 RearDiffLckLamp_D_Cstm 3;
BA_ "U_V710_MY2023_Tx" SG_ 1245 FrontDiffLckLamp_D_Cstm 1;
BA_ "ECGUsedTxSignal" SG_ 1245 FrontDiffLckLamp_D_Cstm 1;
BA_ "U_P708_MY2023_Rx" SG_ 1245 FrontDiffLckLamp_D_Cstm 1;
BA_ "GenSigSendType" SG_ 1245 FrontDiffLckLamp_D_Cstm 3;
BA_ "U_V710_MY2023_Tx" SG_ 1245 AwdMdeCstm_D_RqDrv 1;
BA_ "ECGUsedTxSignal" SG_ 1245 AwdMdeCstm_D_RqDrv 1;
BA_ "U_P708_MY2023_Rx" SG_ 1245 AwdMdeCstm_D_RqDrv 1;
BA_ "GenSigSendType" SG_ 1245 AwdMdeCstm_D_RqDrv 3;
BA_ "U_V710_MY2023_Tx" SG_ 1245 SelDrvMdeAwd2_D_Cstm 1;
BA_ "ECGUsedTxSignal" SG_ 1245 SelDrvMdeAwd2_D_Cstm 1;
BA_ "GenSigSendType" SG_ 1245 SelDrvMdeAwd2_D_Cstm 3;
BA_ "GenSigStartValue" SG_ 1245 SelDrvMdeAwd2_D_Cstm 31;
BA_ "U_P708_MY2023_Rx" SG_ 781 TrlrTireDual_D_Stat 1;
BA_ "U_P708_MY2023_Rx" SG_ 781 TrlrTireThresh_D_Stat 1;
BA_ "U_P708_MY2023_Rx" SG_ 781 TrlrTireSys_D_Stat 1;
BA_ "U_P708_MY2023_Rx" SG_ 781 TrlrTireCnt_D_Stat 1;
BA_ "U_P708_MY2023_Rx" SG_ 781 ChirpRq_No_ActlTrlr 1;
BA_ "U_P708_MY2023_Rx" SG_ 781 Chirp_D_RqTrlr 1;
BA_ "U_P708_MY2023_Rx" SG_ 1022 TrlrTireTSensIRM_D_Stat 1;
BA_ "U_P708_MY2023_Rx" SG_ 1022 TrlrTireTSensIRF_D_Stat 1;
BA_ "U_P708_MY2023_Rx" SG_ 1022 TrlrTireIRR_T_Actl 1;
BA_ "GenSigStartValue" SG_ 1022 TrlrTireIRR_T_Actl 253;
BA_ "U_P708_MY2023_Rx" SG_ 1022 TrlrTireIRM_T_Actl 1;
BA_ "GenSigStartValue" SG_ 1022 TrlrTireIRM_T_Actl 253;
BA_ "U_P708_MY2023_Rx" SG_ 1022 TrlrTireILR_T_Actl 1;
BA_ "GenSigStartValue" SG_ 1022 TrlrTireILR_T_Actl 253;
BA_ "U_P708_MY2023_Rx" SG_ 1022 TrlrTireILM_T_Actl 1;
BA_ "GenSigStartValue" SG_ 1022 TrlrTireILM_T_Actl 253;
BA_ "U_P708_MY2023_Rx" SG_ 1022 TrlrTireILF_T_Actl 1;
BA_ "GenSigStartValue" SG_ 1022 TrlrTireILF_T_Actl 253;
BA_ "U_P708_MY2023_Rx" SG_ 1022 TrlrTireIRF_T_Actl 1;
BA_ "GenSigStartValue" SG_ 1022 TrlrTireIRF_T_Actl 253;
BA_ "U_P708_MY2023_Rx" SG_ 1022 TrlrTireTSensIRR_D_Stat 1;
BA_ "U_P708_MY2023_Rx" SG_ 1022 TrlrTireTSensILR_D_Stat 1;
BA_ "U_P708_MY2023_Rx" SG_ 1022 TrlrTireTSensILM_D_Stat 1;
BA_ "U_P708_MY2023_Rx" SG_ 1022 TrlrTireTSensILF_D_Stat 1;
BA_ "GenSigStartValue" SG_ 1112 BattTrac2_E_Max 4094;
BA_ "GenSigStartValue" SG_ 1112 BattTracDelta_Te_Actl 254;
BA_ "U_V710_MY2023_Rx" SG_ 1112 BattTracHazrd_D_Stat 1;
BA_ "U_P708_MY2023_Rx" SG_ 1112 BattTracHazrd_D_Stat 1;
BA_ "MetaData" SG_ 977 CnvtTop_No_Cnt 1;
BA_ "U_V713AV_MY2022_Rx" SG_ 977 CnvtTopPos_Up_Stat 1;
BA_ "U_V713N_MY2022_Rx" SG_ 977 CnvtTopPos_Up_Stat 1;
BA_ "WakeupSignal" SG_ 977 CnvtTopPos_Up_Stat 1;
BA_ "WakeupSignal" SG_ 977 CnvtTopMsgTxt_D_Rq 1;
BA_ "U_V713AV_MY2022_Rx" SG_ 977 CnvtTopPos_Dn_Stat 1;
BA_ "U_V713N_MY2022_Rx" SG_ 977 CnvtTopPos_Dn_Stat 1;
BA_ "WakeupSignal" SG_ 977 CnvtTopPos_Dn_Stat 1;
BA_ "U_V710_MY2023_Rx" SG_ 530 PiCode_No_Rq 1;
BA_ "U_P708_MY2023_Rx" SG_ 530 PiCode_No_Rq 1;
BA_ "U_V713AV_MY2022_Rx" SG_ 530 PiCode_No_Rq 1;
BA_ "U_V713N_MY2022_Rx" SG_ 530 PiCode_No_Rq 1;
BA_ "U_V710_MY2023_Rx" SG_ 530 StationTypeSel_D_Rq 1;
BA_ "U_P708_MY2023_Rx" SG_ 530 StationTypeSel_D_Rq 1;
BA_ "U_V713AV_MY2022_Rx" SG_ 530 StationTypeSel_D_Rq 1;
BA_ "U_V713N_MY2022_Rx" SG_ 530 StationTypeSel_D_Rq 1;
BA_ "GenSigSendType" SG_ 530 StationTypeSel_D_Rq 3;
BA_ "U_V710_MY2023_Rx" SG_ 530 DabExtndCntryCode_No_Rq 1;
BA_ "U_P708_MY2023_Rx" SG_ 530 DabExtndCntryCode_No_Rq 1;
BA_ "U_V713AV_MY2022_Rx" SG_ 530 DabExtndCntryCode_No_Rq 1;
BA_ "U_V713N_MY2022_Rx" SG_ 530 DabExtndCntryCode_No_Rq 1;
BA_ "U_V710_MY2023_Rx" SG_ 530 DabStationCodeId_No_Rq 1;
BA_ "U_P708_MY2023_Rx" SG_ 530 DabStationCodeId_No_Rq 1;
BA_ "U_V713AV_MY2022_Rx" SG_ 530 DabStationCodeId_No_Rq 1;
BA_ "U_V713N_MY2022_Rx" SG_ 530 DabStationCodeId_No_Rq 1;
BA_ "U_V710_MY2023_Rx" SG_ 530 DabStationId_No_Rq 1;
BA_ "U_P708_MY2023_Rx" SG_ 530 DabStationId_No_Rq 1;
BA_ "U_V713AV_MY2022_Rx" SG_ 530 DabStationId_No_Rq 1;
BA_ "U_V713N_MY2022_Rx" SG_ 530 DabStationId_No_Rq 1;
BA_ "U_V713AV_MY2022_Tx" SG_ 746 Con_BTAud_Shuffle_St 1;
BA_ "U_V713N_MY2022_Tx" SG_ 746 Con_BTAud_Shuffle_St 1;
BA_ "GenSigSendType" SG_ 746 Con_BTAud_Shuffle_St 3;
BA_ "U_V713AV_MY2022_Tx" SG_ 746 Con_BTAud_Repeat_St 1;
BA_ "U_V713N_MY2022_Tx" SG_ 746 Con_BTAud_Repeat_St 1;
BA_ "GenSigSendType" SG_ 746 Con_BTAud_Repeat_St 3;
BA_ "U_V713AV_MY2022_Tx" SG_ 746 Con_BTAud_IntroScan_St 1;
BA_ "U_V713N_MY2022_Tx" SG_ 746 Con_BTAud_IntroScan_St 1;
BA_ "GenSigSendType" SG_ 746 Con_BTAud_IntroScan_St 3;
BA_ "U_V713AV_MY2022_Tx" SG_ 746 Con_BTAud_ActTrNum1_St 1;
BA_ "U_V713N_MY2022_Tx" SG_ 746 Con_BTAud_ActTrNum1_St 1;
BA_ "GenSigSendType" SG_ 746 Con_BTAud_ActTrNum1_St 3;
BA_ "U_V713AV_MY2022_Tx" SG_ 746 Con_ShowBTPINNumb_St 1;
BA_ "U_V713N_MY2022_Tx" SG_ 746 Con_ShowBTPINNumb_St 1;
BA_ "GenSigSendType" SG_ 746 Con_ShowBTPINNumb_St 3;
BA_ "U_V713AV_MY2022_Tx" SG_ 746 Con_BTAud_Error_St 1;
BA_ "U_V713N_MY2022_Tx" SG_ 746 Con_BTAud_Error_St 1;
BA_ "GenSigSendType" SG_ 746 Con_BTAud_Error_St 3;
BA_ "U_V713AV_MY2022_Tx" SG_ 746 Con_BTAud_FunctStats_St 1;
BA_ "U_V713N_MY2022_Tx" SG_ 746 Con_BTAud_FunctStats_St 1;
BA_ "GenSigSendType" SG_ 746 Con_BTAud_FunctStats_St 3;
BA_ "U_V713AV_MY2022_Tx" SG_ 746 Con_BTAud_OpMode_St 1;
BA_ "U_V713N_MY2022_Tx" SG_ 746 Con_BTAud_OpMode_St 1;
BA_ "GenSigSendType" SG_ 746 Con_BTAud_OpMode_St 3;
BA_ "U_V710_MY2023_Rx" SG_ 479 DISP_SetVolume_Rq 1;
BA_ "U_P708_MY2023_Rx" SG_ 479 DISP_SetVolume_Rq 1;
BA_ "U_V713AV_MY2022_Rx" SG_ 479 DISP_SetVolume_Rq 1;
BA_ "U_V713N_MY2022_Rx" SG_ 479 DISP_SetVolume_Rq 1;
BA_ "GenSigSendType" SG_ 479 DISP_SetVolume_Rq 3;
BA_ "GenSigStartValue" SG_ 479 DISP_SetVolume_Rq 30;
BA_ "U_V710_MY2023_Rx" SG_ 479 DISP_SetVol_Source_Rq 1;
BA_ "U_P708_MY2023_Rx" SG_ 479 DISP_SetVol_Source_Rq 1;
BA_ "U_V713AV_MY2022_Rx" SG_ 479 DISP_SetVol_Source_Rq 1;
BA_ "U_V713N_MY2022_Rx" SG_ 479 DISP_SetVol_Source_Rq 1;
BA_ "GenSigSendType" SG_ 479 DISP_SetVol_Source_Rq 3;
BA_ "U_V710_MY2023_Rx" SG_ 479 DISP_SetVol_Level_Rq 1;
BA_ "U_P708_MY2023_Rx" SG_ 479 DISP_SetVol_Level_Rq 1;
BA_ "U_V713AV_MY2022_Rx" SG_ 479 DISP_SetVol_Level_Rq 1;
BA_ "U_V713N_MY2022_Rx" SG_ 479 DISP_SetVol_Level_Rq 1;
BA_ "U_V710_MY2023_Rx" SG_ 479 DISP_Setshaker_Rq 1;
BA_ "U_P708_MY2023_Rx" SG_ 479 DISP_Setshaker_Rq 1;
BA_ "U_V713AV_MY2022_Rx" SG_ 479 DISP_Setshaker_Rq 1;
BA_ "U_V713N_MY2022_Rx" SG_ 479 DISP_Setshaker_Rq 1;
BA_ "GenSigSendType" SG_ 479 DISP_Setshaker_Rq 3;
BA_ "U_V710_MY2023_Rx" SG_ 474 Nav_SetCurrStatMCCh_Rq 1;
BA_ "U_P708_MY2023_Rx" SG_ 474 Nav_SetCurrStatMCCh_Rq 1;
BA_ "U_V713AV_MY2022_Rx" SG_ 474 Nav_SetCurrStatMCCh_Rq 1;
BA_ "U_V713N_MY2022_Rx" SG_ 474 Nav_SetCurrStatMCCh_Rq 1;
BA_ "U_V710_MY2023_Rx" SG_ 474 NAV_SetNEWSMode_Rq 1;
BA_ "U_P708_MY2023_Rx" SG_ 474 NAV_SetNEWSMode_Rq 1;
BA_ "U_V713AV_MY2022_Rx" SG_ 474 NAV_SetNEWSMode_Rq 1;
BA_ "U_V713N_MY2022_Rx" SG_ 474 NAV_SetNEWSMode_Rq 1;
BA_ "GenSigSendType" SG_ 474 NAV_SetNEWSMode_Rq 3;
BA_ "U_V710_MY2023_Rx" SG_ 474 NAV_SetMid_Rq 1;
BA_ "U_P708_MY2023_Rx" SG_ 474 NAV_SetMid_Rq 1;
BA_ "U_V713AV_MY2022_Rx" SG_ 474 NAV_SetMid_Rq 1;
BA_ "U_V713N_MY2022_Rx" SG_ 474 NAV_SetMid_Rq 1;
BA_ "GenSigSendType" SG_ 474 NAV_SetMid_Rq 3;
BA_ "GenSigStartValue" SG_ 474 NAV_SetMid_Rq 15;
BA_ "U_V710_MY2023_Rx" SG_ 474 NAV_SetDSP_Rq 1;
BA_ "U_P708_MY2023_Rx" SG_ 474 NAV_SetDSP_Rq 1;
BA_ "U_V713AV_MY2022_Rx" SG_ 474 NAV_SetDSP_Rq 1;
BA_ "U_V713N_MY2022_Rx" SG_ 474 NAV_SetDSP_Rq 1;
BA_ "GenSigSendType" SG_ 474 NAV_SetDSP_Rq 3;
BA_ "U_V710_MY2023_Rx" SG_ 474 NAV_SetCurrStatFreq_Rq 1;
BA_ "U_P708_MY2023_Rx" SG_ 474 NAV_SetCurrStatFreq_Rq 1;
BA_ "U_V713AV_MY2022_Rx" SG_ 474 NAV_SetCurrStatFreq_Rq 1;
BA_ "U_V713N_MY2022_Rx" SG_ 474 NAV_SetCurrStatFreq_Rq 1;
BA_ "U_V710_MY2023_Rx" SG_ 474 NAV_SetCurrentStatOp_Rq 1;
BA_ "U_P708_MY2023_Rx" SG_ 474 NAV_SetCurrentStatOp_Rq 1;
BA_ "U_V713AV_MY2022_Rx" SG_ 474 NAV_SetCurrentStatOp_Rq 1;
BA_ "U_V713N_MY2022_Rx" SG_ 474 NAV_SetCurrentStatOp_Rq 1;
BA_ "GenSigSendType" SG_ 474 NAV_SetCurrentStatOp_Rq 3;
BA_ "U_V710_MY2023_Rx" SG_ 474 NAV_SetCurrentPICode_Rq 1;
BA_ "U_P708_MY2023_Rx" SG_ 474 NAV_SetCurrentPICode_Rq 1;
BA_ "U_V713AV_MY2022_Rx" SG_ 474 NAV_SetCurrentPICode_Rq 1;
BA_ "U_V713N_MY2022_Rx" SG_ 474 NAV_SetCurrentPICode_Rq 1;
BA_ "U_V710_MY2023_Rx" SG_ 474 NAV_ARReqstrSystem_Rq 1;
BA_ "U_P708_MY2023_Rx" SG_ 474 NAV_ARReqstrSystem_Rq 1;
BA_ "U_V713AV_MY2022_Rx" SG_ 474 NAV_ARReqstrSystem_Rq 1;
BA_ "U_V713N_MY2022_Rx" SG_ 474 NAV_ARReqstrSystem_Rq 1;
BA_ "U_V710_MY2023_Rx" SG_ 474 NAV_ARReqstrPriority_Rq 1;
BA_ "U_P708_MY2023_Rx" SG_ 474 NAV_ARReqstrPriority_Rq 1;
BA_ "U_V713AV_MY2022_Rx" SG_ 474 NAV_ARReqstrPriority_Rq 1;
BA_ "U_V713N_MY2022_Rx" SG_ 474 NAV_ARReqstrPriority_Rq 1;
BA_ "U_V710_MY2023_Rx" SG_ 474 NAV_AROperationType_Rq 1;
BA_ "U_P708_MY2023_Rx" SG_ 474 NAV_AROperationType_Rq 1;
BA_ "U_V713AV_MY2022_Rx" SG_ 474 NAV_AROperationType_Rq 1;
BA_ "U_V713N_MY2022_Rx" SG_ 474 NAV_AROperationType_Rq 1;
BA_ "GenSigSendType" SG_ 474 NAV_AROperationType_Rq 3;
BA_ "U_V710_MY2023_Rx" SG_ 474 NAV_ARAudioSource_Rq 1;
BA_ "U_P708_MY2023_Rx" SG_ 474 NAV_ARAudioSource_Rq 1;
BA_ "U_V713AV_MY2022_Rx" SG_ 474 NAV_ARAudioSource_Rq 1;
BA_ "U_V713N_MY2022_Rx" SG_ 474 NAV_ARAudioSource_Rq 1;
BA_ "U_V710_MY2023_Rx" SG_ 477 NAV_SetTreble_Rq 1;
BA_ "U_P708_MY2023_Rx" SG_ 477 NAV_SetTreble_Rq 1;
BA_ "U_V713AV_MY2022_Rx" SG_ 477 NAV_SetTreble_Rq 1;
BA_ "U_V713N_MY2022_Rx" SG_ 477 NAV_SetTreble_Rq 1;
BA_ "GenSigSendType" SG_ 477 NAV_SetTreble_Rq 3;
BA_ "GenSigStartValue" SG_ 477 NAV_SetTreble_Rq 15;
BA_ "U_V710_MY2023_Rx" SG_ 477 NAV_SetFader_Rq 1;
BA_ "U_P708_MY2023_Rx" SG_ 477 NAV_SetFader_Rq 1;
BA_ "U_V713AV_MY2022_Rx" SG_ 477 NAV_SetFader_Rq 1;
BA_ "U_V713N_MY2022_Rx" SG_ 477 NAV_SetFader_Rq 1;
BA_ "GenSigSendType" SG_ 477 NAV_SetFader_Rq 3;
BA_ "GenSigStartValue" SG_ 477 NAV_SetFader_Rq 15;
BA_ "U_V710_MY2023_Rx" SG_ 477 NAV_SetBass_Rq 1;
BA_ "U_P708_MY2023_Rx" SG_ 477 NAV_SetBass_Rq 1;
BA_ "U_V713AV_MY2022_Rx" SG_ 477 NAV_SetBass_Rq 1;
BA_ "U_V713N_MY2022_Rx" SG_ 477 NAV_SetBass_Rq 1;
BA_ "GenSigSendType" SG_ 477 NAV_SetBass_Rq 3;
BA_ "GenSigStartValue" SG_ 477 NAV_SetBass_Rq 15;
BA_ "U_V710_MY2023_Rx" SG_ 477 NAV_SetBalance_Rq 1;
BA_ "U_P708_MY2023_Rx" SG_ 477 NAV_SetBalance_Rq 1;
BA_ "U_V713AV_MY2022_Rx" SG_ 477 NAV_SetBalance_Rq 1;
BA_ "U_V713N_MY2022_Rx" SG_ 477 NAV_SetBalance_Rq 1;
BA_ "GenSigSendType" SG_ 477 NAV_SetBalance_Rq 3;
BA_ "GenSigStartValue" SG_ 477 NAV_SetBalance_Rq 15;
BA_ "U_V710_MY2023_Rx" SG_ 477 NAV_SetAVC_Rq 1;
BA_ "U_P708_MY2023_Rx" SG_ 477 NAV_SetAVC_Rq 1;
BA_ "U_V713AV_MY2022_Rx" SG_ 477 NAV_SetAVC_Rq 1;
BA_ "U_V713N_MY2022_Rx" SG_ 477 NAV_SetAVC_Rq 1;
BA_ "GenSigSendType" SG_ 477 NAV_SetAVC_Rq 3;
BA_ "GenSigStartValue" SG_ 477 NAV_SetAVC_Rq 15;
BA_ "U_V710_MY2023_Rx" SG_ 477 NAV_SecurtyPINUnlock_Rq 1;
BA_ "U_P708_MY2023_Rx" SG_ 477 NAV_SecurtyPINUnlock_Rq 1;
BA_ "U_V713AV_MY2022_Rx" SG_ 477 NAV_SecurtyPINUnlock_Rq 1;
BA_ "U_V713N_MY2022_Rx" SG_ 477 NAV_SecurtyPINUnlock_Rq 1;
BA_ "GenSigSendType" SG_ 477 NAV_SecurtyPINUnlock_Rq 3;
BA_ "U_V710_MY2023_Rx" SG_ 477 NAV_LoadEjectMode_Rq 1;
BA_ "U_P708_MY2023_Rx" SG_ 477 NAV_LoadEjectMode_Rq 1;
BA_ "U_V713AV_MY2022_Rx" SG_ 477 NAV_LoadEjectMode_Rq 1;
BA_ "U_V713N_MY2022_Rx" SG_ 477 NAV_LoadEjectMode_Rq 1;
BA_ "GenSigSendType" SG_ 477 NAV_LoadEjectMode_Rq 3;
BA_ "U_V710_MY2023_Rx" SG_ 477 NAV_LoadEjectDisc_Rq 1;
BA_ "U_P708_MY2023_Rx" SG_ 477 NAV_LoadEjectDisc_Rq 1;
BA_ "U_V713AV_MY2022_Rx" SG_ 477 NAV_LoadEjectDisc_Rq 1;
BA_ "U_V713N_MY2022_Rx" SG_ 477 NAV_LoadEjectDisc_Rq 1;
BA_ "U_V710_MY2023_Rx" SG_ 260 MFD_SDARS_SetOpMode_Rq 1;
BA_ "U_P708_MY2023_Rx" SG_ 260 MFD_SDARS_SetOpMode_Rq 1;
BA_ "U_V713AV_MY2022_Rx" SG_ 260 MFD_SDARS_SetOpMode_Rq 1;
BA_ "U_V713N_MY2022_Rx" SG_ 260 MFD_SDARS_SetOpMode_Rq 1;
BA_ "GenSigSendType" SG_ 260 MFD_SDARS_SetOpMode_Rq 3;
BA_ "U_V710_MY2023_Rx" SG_ 260 MFD_SDARS_DirectTune_Rq 1;
BA_ "U_P708_MY2023_Rx" SG_ 260 MFD_SDARS_DirectTune_Rq 1;
BA_ "U_V713AV_MY2022_Rx" SG_ 260 MFD_SDARS_DirectTune_Rq 1;
BA_ "U_V713N_MY2022_Rx" SG_ 260 MFD_SDARS_DirectTune_Rq 1;
BA_ "GenSigSendType" SG_ 260 MFD_SDARS_DirectTune_Rq 3;
BA_ "GenSigStartValue" SG_ 260 MFD_SDARS_DirectTune_Rq 255;
BA_ "U_V710_MY2023_Rx" SG_ 260 SDARS_GetESN_Rq 1;
BA_ "U_P708_MY2023_Rx" SG_ 260 SDARS_GetESN_Rq 1;
BA_ "U_V713AV_MY2022_Rx" SG_ 260 SDARS_GetESN_Rq 1;
BA_ "U_V713N_MY2022_Rx" SG_ 260 SDARS_GetESN_Rq 1;
BA_ "GenSigSendType" SG_ 260 SDARS_GetESN_Rq 3;
BA_ "U_V710_MY2023_Rx" SG_ 260 SDARS_SRReplay_Rq 1;
BA_ "U_P708_MY2023_Rx" SG_ 260 SDARS_SRReplay_Rq 1;
BA_ "U_V713AV_MY2022_Rx" SG_ 260 SDARS_SRReplay_Rq 1;
BA_ "U_V713N_MY2022_Rx" SG_ 260 SDARS_SRReplay_Rq 1;
BA_ "GenSigSendType" SG_ 260 SDARS_SRReplay_Rq 3;
BA_ "U_V710_MY2023_Rx" SG_ 260 SDARS_SelectCategory_Rq 1;
BA_ "U_P708_MY2023_Rx" SG_ 260 SDARS_SelectCategory_Rq 1;
BA_ "U_V713AV_MY2022_Rx" SG_ 260 SDARS_SelectCategory_Rq 1;
BA_ "U_V713N_MY2022_Rx" SG_ 260 SDARS_SelectCategory_Rq 1;
BA_ "GenSigSendType" SG_ 260 SDARS_SelectCategory_Rq 3;
BA_ "U_V710_MY2023_Rx" SG_ 260 SDARS_InfoRefChanNum_Rq 1;
BA_ "U_P708_MY2023_Rx" SG_ 260 SDARS_InfoRefChanNum_Rq 1;
BA_ "U_V713AV_MY2022_Rx" SG_ 260 SDARS_InfoRefChanNum_Rq 1;
BA_ "U_V713N_MY2022_Rx" SG_ 260 SDARS_InfoRefChanNum_Rq 1;
BA_ "GenSigSendType" SG_ 260 SDARS_InfoRefChanNum_Rq 3;
BA_ "U_V710_MY2023_Rx" SG_ 260 SDARS_FactoryReset_Rq 1;
BA_ "U_P708_MY2023_Rx" SG_ 260 SDARS_FactoryReset_Rq 1;
BA_ "U_V713AV_MY2022_Rx" SG_ 260 SDARS_FactoryReset_Rq 1;
BA_ "U_V713N_MY2022_Rx" SG_ 260 SDARS_FactoryReset_Rq 1;
BA_ "GenSigSendType" SG_ 260 SDARS_FactoryReset_Rq 3;
BA_ "U_V710_MY2023_Rx" SG_ 476 Nav_SetAudioMixRatio_Rq 1;
BA_ "U_P708_MY2023_Rx" SG_ 476 Nav_SetAudioMixRatio_Rq 1;
BA_ "U_V713AV_MY2022_Rx" SG_ 476 Nav_SetAudioMixRatio_Rq 1;
BA_ "U_V713N_MY2022_Rx" SG_ 476 Nav_SetAudioMixRatio_Rq 1;
BA_ "GenSigSendType" SG_ 476 Nav_SetAudioMixRatio_Rq 3;
BA_ "GenSigStartValue" SG_ 476 Nav_SetAudioMixRatio_Rq 31;
BA_ "U_V710_MY2023_Rx" SG_ 476 NAV_SkipCatalouge_Rq 1;
BA_ "U_P708_MY2023_Rx" SG_ 476 NAV_SkipCatalouge_Rq 1;
BA_ "U_V713AV_MY2022_Rx" SG_ 476 NAV_SkipCatalouge_Rq 1;
BA_ "U_V713N_MY2022_Rx" SG_ 476 NAV_SkipCatalouge_Rq 1;
BA_ "GenSigSendType" SG_ 476 NAV_SkipCatalouge_Rq 3;
BA_ "U_V710_MY2023_Rx" SG_ 476 NAV_SetOperationMode_Rq 1;
BA_ "U_P708_MY2023_Rx" SG_ 476 NAV_SetOperationMode_Rq 1;
BA_ "U_V713AV_MY2022_Rx" SG_ 476 NAV_SetOperationMode_Rq 1;
BA_ "U_V713N_MY2022_Rx" SG_ 476 NAV_SetOperationMode_Rq 1;
BA_ "GenSigSendType" SG_ 476 NAV_SetOperationMode_Rq 3;
BA_ "U_V710_MY2023_Rx" SG_ 476 NAV_SetDSPProgram_Rq 1;
BA_ "U_P708_MY2023_Rx" SG_ 476 NAV_SetDSPProgram_Rq 1;
BA_ "U_V713AV_MY2022_Rx" SG_ 476 NAV_SetDSPProgram_Rq 1;
BA_ "U_V713N_MY2022_Rx" SG_ 476 NAV_SetDSPProgram_Rq 1;
BA_ "GenSigSendType" SG_ 476 NAV_SetDSPProgram_Rq 3;
BA_ "U_V710_MY2023_Rx" SG_ 490 HMI_SetCompression_Rq 1;
BA_ "U_P708_MY2023_Rx" SG_ 490 HMI_SetCompression_Rq 1;
BA_ "U_V713AV_MY2022_Rx" SG_ 490 HMI_SetCompression_Rq 1;
BA_ "U_V713N_MY2022_Rx" SG_ 490 HMI_SetCompression_Rq 1;
BA_ "GenSigSendType" SG_ 490 HMI_SetCompression_Rq 3;
BA_ "U_V710_MY2023_Rx" SG_ 490 HMI_SkipTrack_Rq 1;
BA_ "U_P708_MY2023_Rx" SG_ 490 HMI_SkipTrack_Rq 1;
BA_ "U_V713AV_MY2022_Rx" SG_ 490 HMI_SkipTrack_Rq 1;
BA_ "U_V713N_MY2022_Rx" SG_ 490 HMI_SkipTrack_Rq 1;
BA_ "GenSigSendType" SG_ 490 HMI_SkipTrack_Rq 3;
BA_ "GenSigSendType" SG_ 1916 TesterPhysicalResRACM 3;
BA_ "GenSigSendType" SG_ 1908 TesterPhysicalReqRACM 3;
BA_ "GenSigStartValue" SG_ 1432 RACM_GWOnBoardTester 255;
BA_ "GenSigStartValue" SG_ 1432 RACM_GWNMProxy 255;
BA_ "GenSigStartValue" SG_ 1432 RACM_AutoSarNMReserved4 255;
BA_ "GenSigStartValue" SG_ 1432 RACM_AutoSarNMReserved3 255;
BA_ "GenSigStartValue" SG_ 1432 RACM_AutoSarNMReserved2 255;
BA_ "GenSigStartValue" SG_ 1432 RACM_AutoSarNMReserved1 255;
BA_ "GenSigStartValue" SG_ 1432 RACM_AutoSarNMNodeId 152;
BA_ "GenSigSendType" SG_ 1923 TesterPhysicalReqDSP 3;
BA_ "GenSigSendType" SG_ 1931 TesterPhysicalResDSP 3;
BA_ "GenSigStartValue" SG_ 896 BptDly_T_Actl 62;
BA_ "U_V710_MY2023_Rx" SG_ 896 VehElAvgTrip1_Eff_Dsply 1;
BA_ "GenSigStartValue" SG_ 896 VehElAvgTrip1_Eff_Dsply 126;
BA_ "GenSigStartValue" SG_ 896 Trip1SumDrvE_Pc_Dsply 1022;
BA_ "GenSigStartValue" SG_ 896 Trip1ExtFctrE_Pc_Dsply 1022;
BA_ "GenSigStartValue" SG_ 896 Trip1ClimE_Pc_Dsply 1022;
BA_ "GenSigStartValue" SG_ 896 Trip1BattULoE_Pc_Dsply 1022;
BA_ "U_V710_MY2023_Rx" SG_ 897 VehElAvgTrip2_Eff_Dsply 1;
BA_ "GenSigStartValue" SG_ 897 VehElAvgTrip2_Eff_Dsply 126;
BA_ "GenSigStartValue" SG_ 897 Trip2SumDrvE_Pc_Dsply 1022;
BA_ "GenSigStartValue" SG_ 897 Trip2ExtFctrE_Pc_Dsply 1022;
BA_ "GenSigStartValue" SG_ 897 Trip2ClimE_Pc_Dsply 1022;
BA_ "GenSigStartValue" SG_ 897 Trip2BattULoE_Pc_Dsply 1022;
BA_ "U_V710_MY2023_Rx" SG_ 502 Dsp_StartItemIndexRq 1;
BA_ "U_P708_MY2023_Rx" SG_ 502 Dsp_StartItemIndexRq 1;
BA_ "U_V713AV_MY2022_Rx" SG_ 502 Dsp_StartItemIndexRq 1;
BA_ "U_V713N_MY2022_Rx" SG_ 502 Dsp_StartItemIndexRq 1;
BA_ "U_V710_MY2023_Rx" SG_ 502 Dsp_NbrOfItems2_Rq 1;
BA_ "U_P708_MY2023_Rx" SG_ 502 Dsp_NbrOfItems2_Rq 1;
BA_ "U_V713AV_MY2022_Rx" SG_ 502 Dsp_NbrOfItems2_Rq 1;
BA_ "U_V713N_MY2022_Rx" SG_ 502 Dsp_NbrOfItems2_Rq 1;
BA_ "U_V710_MY2023_Rx" SG_ 502 Dsp_ItemNameLength2_Rq 1;
BA_ "U_P708_MY2023_Rx" SG_ 502 Dsp_ItemNameLength2_Rq 1;
BA_ "U_V713AV_MY2022_Rx" SG_ 502 Dsp_ItemNameLength2_Rq 1;
BA_ "U_V713N_MY2022_Rx" SG_ 502 Dsp_ItemNameLength2_Rq 1;
BA_ "U_V710_MY2023_Rx" SG_ 502 Dsp_FolderNumber2_Rq 1;
BA_ "U_P708_MY2023_Rx" SG_ 502 Dsp_FolderNumber2_Rq 1;
BA_ "U_V713AV_MY2022_Rx" SG_ 502 Dsp_FolderNumber2_Rq 1;
BA_ "U_V713N_MY2022_Rx" SG_ 502 Dsp_FolderNumber2_Rq 1;
BA_ "U_V710_MY2023_Rx" SG_ 502 Dsp_FolderContent_Rq 1;
BA_ "U_P708_MY2023_Rx" SG_ 502 Dsp_FolderContent_Rq 1;
BA_ "U_V713AV_MY2022_Rx" SG_ 502 Dsp_FolderContent_Rq 1;
BA_ "U_V713N_MY2022_Rx" SG_ 502 Dsp_FolderContent_Rq 1;
BA_ "U_V710_MY2023_Rx" SG_ 502 Dsp_CutItem2_Rq 1;
BA_ "U_P708_MY2023_Rx" SG_ 502 Dsp_CutItem2_Rq 1;
BA_ "U_V713AV_MY2022_Rx" SG_ 502 Dsp_CutItem2_Rq 1;
BA_ "U_V713N_MY2022_Rx" SG_ 502 Dsp_CutItem2_Rq 1;
BA_ "U_V710_MY2023_Rx" SG_ 502 Dsp_AudioSourceSel2_Rq 1;
BA_ "U_P708_MY2023_Rx" SG_ 502 Dsp_AudioSourceSel2_Rq 1;
BA_ "U_V713AV_MY2022_Rx" SG_ 502 Dsp_AudioSourceSel2_Rq 1;
BA_ "U_V713N_MY2022_Rx" SG_ 502 Dsp_AudioSourceSel2_Rq 1;
BA_ "GenSigSendType" SG_ 502 Dsp_AudioSourceSel2_Rq 3;
BA_ "U_P708_MY2023_Rx" SG_ 955 Tire_Temp_RF_Data 1;
BA_ "U_V713AV_MY2022_Rx" SG_ 955 Tire_Temp_RF_Data 1;
BA_ "U_V713N_MY2022_Rx" SG_ 955 Tire_Temp_RF_Data 1;
BA_ "GenSigStartValue" SG_ 955 Tire_Temp_RF_Data 253;
BA_ "U_P708_MY2023_Rx" SG_ 955 Tire_Temp_ORR_Data 1;
BA_ "U_V713AV_MY2022_Rx" SG_ 955 Tire_Temp_ORR_Data 1;
BA_ "U_V713N_MY2022_Rx" SG_ 955 Tire_Temp_ORR_Data 1;
BA_ "GenSigStartValue" SG_ 955 Tire_Temp_ORR_Data 253;
BA_ "U_P708_MY2023_Rx" SG_ 955 Tire_Temp_OLR_Data 1;
BA_ "U_V713AV_MY2022_Rx" SG_ 955 Tire_Temp_OLR_Data 1;
BA_ "U_V713N_MY2022_Rx" SG_ 955 Tire_Temp_OLR_Data 1;
BA_ "GenSigStartValue" SG_ 955 Tire_Temp_OLR_Data 253;
BA_ "U_P708_MY2023_Rx" SG_ 955 Tire_Temp_LF_Data 1;
BA_ "U_V713AV_MY2022_Rx" SG_ 955 Tire_Temp_LF_Data 1;
BA_ "U_V713N_MY2022_Rx" SG_ 955 Tire_Temp_LF_Data 1;
BA_ "GenSigStartValue" SG_ 955 Tire_Temp_LF_Data 253;
BA_ "U_P708_MY2023_Rx" SG_ 955 Tire_Temp_IRR_Data 1;
BA_ "U_V713AV_MY2022_Rx" SG_ 955 Tire_Temp_IRR_Data 1;
BA_ "U_V713N_MY2022_Rx" SG_ 955 Tire_Temp_IRR_Data 1;
BA_ "GenSigStartValue" SG_ 955 Tire_Temp_IRR_Data 253;
BA_ "U_P708_MY2023_Rx" SG_ 955 Tire_Temp_ILR_Data 1;
BA_ "U_V713AV_MY2022_Rx" SG_ 955 Tire_Temp_ILR_Data 1;
BA_ "U_V713N_MY2022_Rx" SG_ 955 Tire_Temp_ILR_Data 1;
BA_ "GenSigStartValue" SG_ 955 Tire_Temp_ILR_Data 253;
BA_ "GenSigSendType" SG_ 1116 TrlrAidSetup_D2_Rq 3;
BA_ "GenSigSendType" SG_ 1116 TrlrAidEnbl_D2_Rq 3;
BA_ "U_V710_MY2023_Rx" SG_ 1116 TlightTest_D_Mnu 1;
BA_ "U_V713AV_MY2022_Rx" SG_ 1116 TlightTest_D_Mnu 1;
BA_ "U_V713N_MY2022_Rx" SG_ 1116 TlightTest_D_Mnu 1;
BA_ "ECGUsedRxSignal" SG_ 1116 TlightTest_D_Mnu 1;
BA_ "GenSigSendType" SG_ 1116 TlightTest_D_Mnu 3;
BA_ "GenSigSendType" SG_ 1116 TrlrRvrseCancl_B_Rq 3;
BA_ "GenSigSendType" SG_ 1116 TrlrIdType_D_Stat 3;
BA_ "GenSigSendType" SG_ 1116 TrlrAnOffstDir_D_Mem 3;
BA_ "GenSigStartValue" SG_ 608 EvseDcChrgIso_D_Stat 6;
BA_ "U_P708_MY2023_Rx" SG_ 608 DcChrgSrvcRqd_B_Rq 1;
BA_ "U_V713AV_MY2022_Rx" SG_ 608 DcChrgSrvcRqd_B_Rq 1;
BA_ "U_V713N_MY2022_Rx" SG_ 608 DcChrgSrvcRqd_B_Rq 1;
BA_ "WakeupSignal" SG_ 608 DcChrgWarnLamp_B_Rq 1;
BA_ "GenSigStartValue" SG_ 608 EvseChrg2_Pw_Mx 32766;
BA_ "U_V710_MY2023_Tx" SG_ 838 FohStop_B_Rq 1;
BA_ "GenSigStartValue" SG_ 838 FohStop_B_Rq 3;
BA_ "U_V710_MY2023_Tx" SG_ 838 FohTAllEnable_B_Rq 1;
BA_ "GenSigStartValue" SG_ 838 FohTAllEnable_B_Rq 3;
BA_ "U_V710_MY2023_Tx" SG_ 838 FohT2Mnte_T_Rq 1;
BA_ "U_V710_MY2023_Tx" SG_ 838 FohT2Hr_T_Rq 1;
BA_ "U_V710_MY2023_Tx" SG_ 838 FohT2Enable_B_Rq 1;
BA_ "U_V710_MY2023_Tx" SG_ 838 FohT1Mnte_T_Rq 1;
BA_ "U_V710_MY2023_Tx" SG_ 838 FohT1Hr_T_Rq 1;
BA_ "U_V710_MY2023_Tx" SG_ 838 FohT1Enable_B_Rq 1;
BA_ "U_V710_MY2023_Tx" SG_ 838 FohStrtMnte_T_Rq 1;
BA_ "U_V710_MY2023_Tx" SG_ 838 FohStrtHr_T_Rq 1;
BA_ "U_V710_MY2023_Tx" SG_ 838 FohStrtEnable_B_Rq 1;
BA_ "U_V710_MY2023_Tx" SG_ 838 FohContOn_B_Rq 1;
BA_ "GenSigStartValue" SG_ 838 FohContOn_B_Rq 3;
BA_ "U_P708_MY2023_Rx" SG_ 529 OnbChrgPrflUpdate_B_Rq 1;
BA_ "U_V713AV_MY2022_Rx" SG_ 529 OnbChrgPrflUpdate_B_Rq 1;
BA_ "U_V713N_MY2022_Rx" SG_ 529 OnbChrgPrflUpdate_B_Rq 1;
BA_ "ECGUsedRxSignal" SG_ 529 OnbChrgPrflUpdate_B_Rq 1;
BA_ "GenSigSendType" SG_ 529 OnbChrgPrflUpdate_B_Rq 3;
BA_ "GenSigSendType" SG_ 529 OnbChrgLocIdTrgt_No_Rq 3;
BA_ "MetaData" SG_ 529 OnbChrgLocIdTrgt_No_Rq 1;
BA_ "U_V713N_MY2022_Rx" SG_ 374 GearEngag_D_Actl 1;
BA_ "GenSigStartValue" SG_ 374 TrnRng_D_Rq 14;
BA_ "MetaData" SG_ 374 GearPos_No_Cs 1;
BA_ "MetaData" SG_ 374 GearPos_No_Cnt 1;
BA_ "GenSigStartValue" SG_ 374 GearPos_D_Actl 15;
BA_ "GenSigStartValue" SG_ 374 GearPos_D_Trg 15;
BA_ "U_V710_MY2023_Rx" SG_ 500 Dsp_SourceSetTrack_Rq 1;
BA_ "U_P708_MY2023_Rx" SG_ 500 Dsp_SourceSetTrack_Rq 1;
BA_ "U_V713AV_MY2022_Rx" SG_ 500 Dsp_SourceSetTrack_Rq 1;
BA_ "U_V713N_MY2022_Rx" SG_ 500 Dsp_SourceSetTrack_Rq 1;
BA_ "U_V710_MY2023_Rx" SG_ 500 Dsp_ItemNameLength_Rq 1;
BA_ "U_P708_MY2023_Rx" SG_ 500 Dsp_ItemNameLength_Rq 1;
BA_ "U_V713AV_MY2022_Rx" SG_ 500 Dsp_ItemNameLength_Rq 1;
BA_ "U_V713N_MY2022_Rx" SG_ 500 Dsp_ItemNameLength_Rq 1;
BA_ "U_V710_MY2023_Rx" SG_ 500 Dsp_GetCDTOCDData_Rq 1;
BA_ "U_P708_MY2023_Rx" SG_ 500 Dsp_GetCDTOCDData_Rq 1;
BA_ "U_V713AV_MY2022_Rx" SG_ 500 Dsp_GetCDTOCDData_Rq 1;
BA_ "U_V713N_MY2022_Rx" SG_ 500 Dsp_GetCDTOCDData_Rq 1;
BA_ "GenSigSendType" SG_ 500 Dsp_GetCDTOCDData_Rq 3;
BA_ "U_V710_MY2023_Rx" SG_ 500 Dsp_FolderNumber_Rq 1;
BA_ "U_P708_MY2023_Rx" SG_ 500 Dsp_FolderNumber_Rq 1;
BA_ "U_V713AV_MY2022_Rx" SG_ 500 Dsp_FolderNumber_Rq 1;
BA_ "U_V713N_MY2022_Rx" SG_ 500 Dsp_FolderNumber_Rq 1;
BA_ "U_V710_MY2023_Rx" SG_ 500 Dsp_CutItem_Rq 1;
BA_ "U_P708_MY2023_Rx" SG_ 500 Dsp_CutItem_Rq 1;
BA_ "U_V713AV_MY2022_Rx" SG_ 500 Dsp_CutItem_Rq 1;
BA_ "U_V713N_MY2022_Rx" SG_ 500 Dsp_CutItem_Rq 1;
BA_ "U_V710_MY2023_Rx" SG_ 500 Dsp_AudioSourceSel_Rq 1;
BA_ "U_P708_MY2023_Rx" SG_ 500 Dsp_AudioSourceSel_Rq 1;
BA_ "U_V713AV_MY2022_Rx" SG_ 500 Dsp_AudioSourceSel_Rq 1;
BA_ "U_V713N_MY2022_Rx" SG_ 500 Dsp_AudioSourceSel_Rq 1;
BA_ "GenSigSendType" SG_ 500 Dsp_AudioSourceSel_Rq 3;
BA_ "U_V710_MY2023_Rx" SG_ 503 Dsp_PlayFrstTrInFldr_Rq 1;
BA_ "U_P708_MY2023_Rx" SG_ 503 Dsp_PlayFrstTrInFldr_Rq 1;
BA_ "U_V713AV_MY2022_Rx" SG_ 503 Dsp_PlayFrstTrInFldr_Rq 1;
BA_ "U_V713N_MY2022_Rx" SG_ 503 Dsp_PlayFrstTrInFldr_Rq 1;
BA_ "U_V710_MY2023_Rx" SG_ 503 Dsp_ItemIndex_Rq 1;
BA_ "U_P708_MY2023_Rx" SG_ 503 Dsp_ItemIndex_Rq 1;
BA_ "U_V713AV_MY2022_Rx" SG_ 503 Dsp_ItemIndex_Rq 1;
BA_ "U_V713N_MY2022_Rx" SG_ 503 Dsp_ItemIndex_Rq 1;
BA_ "U_V710_MY2023_Rx" SG_ 503 Dsp_FolderNumber3_Rq 1;
BA_ "U_P708_MY2023_Rx" SG_ 503 Dsp_FolderNumber3_Rq 1;
BA_ "U_V713AV_MY2022_Rx" SG_ 503 Dsp_FolderNumber3_Rq 1;
BA_ "U_V713N_MY2022_Rx" SG_ 503 Dsp_FolderNumber3_Rq 1;
BA_ "U_V710_MY2023_Rx" SG_ 503 Dsp_AudioSourceSel3_Rq 1;
BA_ "U_P708_MY2023_Rx" SG_ 503 Dsp_AudioSourceSel3_Rq 1;
BA_ "U_V713AV_MY2022_Rx" SG_ 503 Dsp_AudioSourceSel3_Rq 1;
BA_ "U_V713N_MY2022_Rx" SG_ 503 Dsp_AudioSourceSel3_Rq 1;
BA_ "GenSigSendType" SG_ 503 Dsp_AudioSourceSel3_Rq 3;
VAL_ 1204 DcacElPwScnd_D_Stat 3 "NotUsed" 2 "High" 1 "Low" 0 "Off" ;
VAL_ 1204 DcacEngOnMsgTxt_D2_Rq 15 "NotUsed_10" 14 "NotUsed_9" 13 "NotUsed_8" 12 "NotUsed_7" 11 "NotUsed_6" 10 "NotUsed_5" 9 "NotUsed_4" 8 "NotUsed_3" 7 "NotUsed_2" 6 "NotUsed_1" 5 "AeisFinalMinutesWarning" 4 "AeisDoorAjarWarning" 3 "AeisManualOverrideWarning" 2 "DisplayQuestion" 1 "DisplayWarning" 0 "Ok" ;
VAL_ 1204 DcacOutScnd_Pw_DsplyMx 1023 "Faulty" ;
VAL_ 1204 DcacOutScnd_Pw2_Dsply 8191 "Faulty" 8190 "NoDataExists" ;
VAL_ 1204 DcacZone3Pw_B_Stat 1 "On" 0 "Off" ;
VAL_ 1204 DcacZone2Pw_B_Stat 1 "On" 0 "Off" ;
VAL_ 826 Memory_3_Sw_Stat 1 "Pressed" 0 "Null" ;
VAL_ 826 Memory_2_Sw_Stat 1 "Pressed" 0 "Null" ;
VAL_ 826 Memory_1_Sw_Stat 1 "Pressed" 0 "Null" ;
VAL_ 826 Mirror_Manual_Override 1 "Override" 0 "Null" ;
VAL_ 1159 FourthRowBucklePsngr2 7 "Faulty" 6 "OccupiedBelted" 5 "SeatAbsent" 4 "EmptyUnbelted" 3 "OccupiedUnbelted" 2 "BatteryLow" 1 "NotDetermined" 0 "EmptyBelted" ;
VAL_ 1159 FourthRowBuckleMid2 7 "Faulty" 6 "OccupiedBelted" 5 "SeatAbsent" 4 "EmptyUnbelted" 3 "OccupiedUnbelted" 2 "BatteryLow" 1 "NotDetermined" 0 "EmptyBelted" ;
VAL_ 1159 FourthRowBuckleDriver2 7 "Faulty" 6 "OccupiedBelted" 5 "SeatAbsent" 4 "EmptyUnbelted" 3 "OccupiedUnbelted" 2 "BatteryLow" 1 "NotDetermined" 0 "EmptyBelted" ;
VAL_ 1159 ThirdRowBucklePsngr2 7 "Faulty" 6 "OccupiedBelted" 5 "SeatAbsent" 4 "EmptyUnbelted" 3 "OccupiedUnbelted" 2 "BatteryLow" 1 "NotDetermined" 0 "EmptyBelted" ;
VAL_ 1159 ThirdRowBuckleMid2 7 "Faulty" 6 "OccupiedBelted" 5 "SeatAbsent" 4 "EmptyUnbelted" 3 "OccupiedUnbelted" 2 "BatteryLow" 1 "NotDetermined" 0 "EmptyBelted" ;
VAL_ 1159 ThirdRowBuckleDriver2 7 "Faulty" 6 "OccupiedBelted" 5 "SeatAbsent" 4 "EmptyUnbelted" 3 "OccupiedUnbelted" 2 "BatteryLow" 1 "NotDetermined" 0 "EmptyBelted" ;
VAL_ 1159 SecondRowBucklePsngr2 7 "Faulty" 6 "OccupiedBelted" 5 "SeatAbsent" 4 "EmptyUnbelted" 3 "OccupiedUnbelted" 2 "BatteryLow" 1 "NotDetermined" 0 "EmptyBelted" ;
VAL_ 1159 SecondRowBuckleMid2 7 "Faulty" 6 "OccupiedBelted" 5 "SeatAbsent" 4 "EmptyUnbelted" 3 "OccupiedUnbelted" 2 "BatteryLow" 1 "NotDetermined" 0 "EmptyBelted" ;
VAL_ 1159 SecondRowBuckleDriver2 7 "Faulty" 6 "OccupiedBelted" 5 "SeatAbsent" 4 "EmptyUnbelted" 3 "OccupiedUnbelted" 2 "BatteryLow" 1 "NotDetermined" 0 "EmptyBelted" ;
VAL_ 1040 ElCmpr2Enbl_B_Rq 1 "Enable" 0 "Disable" ;
VAL_ 1040 BattTrac_I2_EstVsc 262143 "Faulty" 262142 "NoDataExists" ;
VAL_ 1040 ElCmprEnbl_B_Rq 1 "Enable" 0 "Disable" ;
VAL_ 630 TrfcLghtUturnType_D_St 3 "Faulty" 2 "DirectionalArrow" 1 "RoundBall" 0 "Inactive" ;
VAL_ 630 TrfcLghtUturnOn_D_Stat 7 "Faulty" 6 "NoDataExists" 5 "NotUsed" 4 "FocusedBlink" 3 "FocusedOn" 2 "Blink" 1 "On" 0 "Inactive" ;
VAL_ 630 TrfcLghtUturnColr_D_St 7 "Faulty" 6 "NoDataExists" 5 "NotUsed_2" 4 "NotUsed_1" 3 "Green" 2 "Orange" 1 "Red" 0 "Inactive" ;
VAL_ 630 TrfcLghtUturn_T_Actl 255 "Faulty" 254 "NoDataExists" ;
VAL_ 630 TrfcLghtRightType_D_St 3 "Faulty" 2 "DirectionalArrow" 1 "RoundBall" 0 "Inactive" ;
VAL_ 630 TrfcLghtRightOn_D_Stat 7 "Faulty" 6 "NoDataExists" 5 "NotUsed" 4 "FocusedBlink" 3 "FocusedOn" 2 "Blink" 1 "On" 0 "Inactive" ;
VAL_ 630 TrfcLghtRightColr_D_St 7 "Faulty" 6 "NoDataExists" 5 "NotUsed_2" 4 "NotUsed_1" 3 "Green" 2 "Orange" 1 "Red" 0 "Inactive" ;
VAL_ 630 TrfcLghtRight_T_Actl 255 "Faulty" 254 "NoDataExists" ;
VAL_ 630 TrfcLghtLeftType_D_Stat 3 "Faulty" 2 "DirectionalArrow" 1 "RoundBall" 0 "Inactive" ;
VAL_ 630 TrfcLghtLeftOn_D_Stat 7 "Faulty" 6 "NoDataExists" 5 "NotUsed" 4 "FocusedBlink" 3 "FocusedOn" 2 "Blink" 1 "On" 0 "Inactive" ;
VAL_ 630 TrfcLghtLeftColr_D_Stat 7 "Faulty" 6 "NoDataExists" 5 "NotUsed_2" 4 "NotUsed_1" 3 "Green" 2 "Orange" 1 "Red" 0 "Inactive" ;
VAL_ 630 TrfcLghtLeft_T_Actl 255 "Faulty" 254 "NoDataExists" ;
VAL_ 630 TrfcLghtStrghtType_D_St 3 "Faulty" 2 "DirectionalArrow" 1 "RoundBall" 0 "Inactive" ;
VAL_ 630 TrfcLghtStrghtOn_D_Stat 7 "Faulty" 6 "NoDataExists" 5 "NotUsed" 4 "FocusedBlink" 3 "FocusedOn" 2 "Blink" 1 "On" 0 "Inactive" ;
VAL_ 630 TrfcLghtStrghtColr_D_St 7 "Faulty" 6 "NoDataExists" 5 "NotUsed_2" 4 "NotUsed_1" 3 "Green" 2 "Orange" 1 "Red" 0 "Inactive" ;
VAL_ 630 TrfcLghtStrght_T_Actl 255 "Faulty" 254 "NoDataExists" ;
VAL_ 627 VehToInfrstrctr_D_Stat 3 "SubComponentUnknownError" 2 "LostConnection" 1 "InServiceWithoutV2IData" 0 "InServiceFunctionOK" 7 "Faulty" 6 "NoDataExists" 5 "NotUsed_2" 4 "NotUsed_1" ;
VAL_ 627 RoadStopLineL_B_Avail 1 "On" 0 "Off" ;
VAL_ 627 RoadStopLine_L_Est 65535 "Faulty" 65534 "NoDataExists" ;
VAL_ 627 RoadSignInfo1_D_Dsply 255 "Faulty" 254 "NoDataExists" 253 "NotUsed_219" 35 "NotUsed_1" 34 "DangerRoadAhead" 33 "WaterPipeBreak" 32 "WaterOnRoad" 31 "VehiclesInQue" 30 "VehicleBreak" 29 "TunnelInWaterAhead" 28 "TrafficControlAhead" 27 "TrafficAccidentAhead" 26 "Speedlimit_120" 25 "Speedlimit_110" 24 "Speedlimit_100" 23 "Speedlimit_90" 22 "Speedlimit_80" 21 "Speedlimit_70" 20 "Speedlimit_60" 19 "Speedlimit_50" 18 "Speedlimit_40" 17 "Speedlimit_30" 16 "Speedlimit_20" 15 "Speedlimit_10" 14 "SlipperyRoad" 13 "SandstormAhead" 12 "FrozenRoad" 11 "FireAlarmOnRoad" 10 "RoadCrack" 9 "RainOrSnowRoad" 8 "Pedestrian" 7 "GoodsDrop" 6 "GasPipeLeakWarning" 5 "FogAhead" 4 "DriveWrongWay" 3 "CrossWindAhead" 2 "RoadWorksAhead" 1 "SlowTrafficAhead" 0 "Inactive" ;
VAL_ 627 TrfcLghtWarnActv_B_Stat 1 "On" 0 "Off" ;
VAL_ 627 TrfcLghtVActv_B_Stat 1 "On" 0 "Off" ;
VAL_ 627 TrfcLghtDir_D_Stat 7 "Faulty" 6 "NoDataExists" 5 "NotUsed" 4 "UtrunActivated" 3 "RightActivated" 2 "LeftActivated" 1 "StraightActivated" 0 "Inactive" ;
VAL_ 627 TrfcLghtDecel_A_Dsply 127 "Faulty" 126 "NoDataExists" ;
VAL_ 627 TrfcLght_V_Mx 255 "Faulty" 254 "NoDataExists" ;
VAL_ 627 TrfcLght_V_Mn 255 "Faulty" 254 "NoDataExists" ;
VAL_ 627 TrfcLght_D_Stat 7 "Faulty" 6 "NoDataExists" 5 "NotUsed" 4 "Four" 3 "Three" 2 "Two" 1 "One" 0 "OffOrNoMatchedLight" ;
VAL_ 874 E_Rr_Btn_Status_2nd 31 "NotUsed15" 30 "NotUsed14" 29 "NotUsed13" 28 "NotUsed12" 27 "NotUsed11" 26 "NotUsed10" 25 "NotUsed9" 24 "Third_Synch_Pressed" 23 "Third_Rr_Pwr_Pressed" 22 "Third_Auto_Pressed" 21 "Third_Pnl_Flr_Pressed" 20 "Third_Floor_Pressed" 19 "Third_Panel_Pressed" 18 "Third_Blwr_Dec_Pressed" 17 "Third_Blwr_Inc_Pressed" 16 "Rear_Lock_Pressed" 15 "RHS_Cld_Seat_Pressed" 14 "LHS_Cld_Seat_Pressed" 13 "RHS_Htd_Seat_Pressed" 12 "LHS_Htd_Seat_Pressed" 11 "Rear_Power_Pressed" 10 "AUTO_Pressed" 9 "Blwr_Dec_Pressed" 8 "Blwr_Inc_Pressed" 7 "RHS_Temp_Dec_Pressed" 6 "RHS_Temp_Inc_Pressed" 5 "LHS_Temp_Dec_Pressed" 4 "LHS_Temp_Inc_Pressed" 3 "Floor_Pressed" 2 "Panel_Floor_Pressed" 1 "Panel_Pressed" 0 "None_Pressed" ;
VAL_ 874 E_Rr_Btn_Status_1st 31 "NotUsed15" 30 "NotUsed14" 29 "NotUsed13" 28 "NotUsed12" 27 "NotUsed11" 26 "NotUsed10" 25 "NotUsed9" 24 "Third_Synch_Pressed" 23 "Third_Rr_Pwr_Pressed" 22 "Third_Auto_Pressed" 21 "Third_Pnl_Flr_Pressed" 20 "Third_Floor_Pressed" 19 "Third_Panel_Pressed" 18 "Third_Blwr_Dec_Pressed" 17 "Third_Blwr_Inc_Pressed" 16 "Rear_Lock_Pressed" 15 "RHS_Cld_Seat_Pressed" 14 "LHS_Cld_Seat_Pressed" 13 "RHS_Htd_Seat_Pressed" 12 "LHS_Htd_Seat_Pressed" 11 "Rear_Power_Pressed" 10 "AUTO_Pressed" 9 "Blwr_Dec_Pressed" 8 "Blwr_Inc_Pressed" 7 "RHS_Temp_Dec_Pressed" 6 "RHS_Temp_Inc_Pressed" 5 "LHS_Temp_Dec_Pressed" 4 "LHS_Temp_Inc_Pressed" 3 "Floor_Pressed" 2 "Panel_Floor_Pressed" 1 "Panel_Pressed" 0 "None_Pressed" ;
VAL_ 874 E_Frt_Btn_Status_2nd 63 "NotUsed_10" 62 "NotUsed_9" 61 "NotUsed_8" 60 "NotUsed_7" 59 "NotUsed_6" 58 "NotUsed_5" 57 "NotUsed_4" 56 "NotUsed_3" 55 "NotUsed_2" 54 "NotUsed_1" 53 "RHS_Cld_Seat3_Pressed" 52 "RHS_Cld_Seat2_Pressed" 51 "RHS_Cld_Seat1_Pressed" 50 "LHS_Cld_Seat3_Pressed" 49 "LHS_Cld_Seat2_Pressed" 48 "LHS_Cld_Seat1_Pressed" 47 "RHS_Auto_Seat_Pressed" 46 "RHS_Htd_Seat3_Pressed" 45 "RHS_Htd_Seat2_Pressed" 44 "RHS_Htd_Seat1_Pressed" 43 "RHS_Seat_Off_Pressed" 42 "LHS_Auto_Seat_Pressed" 41 "LHS_Htd_Seat3_Pressed" 40 "LHS_Htd_Seat2_Pressed" 39 "LHS_Htd_Seat1_Pressed" 38 "LHS_Seat_Off_Pressed" 37 "DrvrFcsdMde_Pressed" 36 "MdeMnu_Pressed" 35 "AAR_Pressed" 34 "Heat_Pressed" 33 "RearMnu_Pressed" 32 "FrontMnu_Pressed" 31 "Defrost_Pressed" 30 "Htg_Strg_Whl_Pressed" 29 "RHS_Cld_Seat_Pressed" 28 "LHS_Cld_Seat_Pressed" 27 "RHS_Htd_Seat_Pressed" 26 "LHS_Htd_Seat_Pressed" 25 "Max_Defrost_Pressed" 24 "My_Temp_Pressed" 23 "Front_Power_Pressed" 22 "Rear_Defrost_Pressed" 21 "Pnl_Flr_Ws_Pressed" 20 "Pnl_Ws_Pressed" 19 "Windscreen_Pressed" 18 "Htd_Frt_Wsh_Pressed" 17 "Auto_Recirc_Pressed" 16 "Outside_Pressed" 15 "Recirc_Pressed" 14 "Max_AC_Pressed" 13 "Auto_Pressed" 12 "Blwr_Dec_Pressed" 11 "Blwr_Inc_Pressed" 10 "RHS_Temp_Dec_Pressed" 9 "RHS_Temp_Inc_Pressed" 8 "LHS_Temp_Dec_Pressed" 7 "LHS_Temp_Inc_Pressed" 6 "Dual_Pressed" 5 "AC_Pressed" 4 "Floor_Ws_Pressed" 3 "Floor_Pressed" 2 "Panel_Floor_Pressed" 1 "Panel_Pressed" 0 "None_Pressed" ;
VAL_ 874 E_Frt_Btn_Status_1st 63 "NotUsed_10" 62 "NotUsed_9" 61 "NotUsed_8" 60 "NotUsed_7" 59 "NotUsed_6" 58 "NotUsed_5" 57 "NotUsed_4" 56 "NotUsed_3" 55 "NotUsed_2" 54 "NotUsed_1" 53 "RHS_Cld_Seat3_Pressed" 52 "RHS_Cld_Seat2_Pressed" 51 "RHS_Cld_Seat1_Pressed" 50 "LHS_Cld_Seat3_Pressed" 49 "LHS_Cld_Seat2_Pressed" 48 "LHS_Cld_Seat1_Pressed" 47 "RHS_Auto_Seat_Pressed" 46 "RHS_Htd_Seat3_Pressed" 45 "RHS_Htd_Seat2_Pressed" 44 "RHS_Htd_Seat1_Pressed" 43 "RHS_Seat_Off_Pressed" 42 "LHS_Auto_Seat_Pressed" 41 "LHS_Htd_Seat3_Pressed" 40 "LHS_Htd_Seat2_Pressed" 39 "LHS_Htd_Seat1_Pressed" 38 "LHS_Seat_Off_Pressed" 37 "DrvrFcsdMde_Pressed" 36 "MdeMnu_Pressed" 35 "AAR_Pressed" 34 "Heat_Pressed" 33 "RearMnu_Pressed" 32 "FrontMnu_Pressed" 31 "Defrost_Pressed" 30 "Htg_Strg_Whl_Pressed" 29 "RHS_Cld_Seat_Pressed" 28 "LHS_Cld_Seat_Pressed" 27 "RHS_Htd_Seat_Pressed" 26 "LHS_Htd_Seat_Pressed" 25 "Max_Defrost_Pressed" 24 "My_Temp_Pressed" 23 "Front_Power_Pressed" 22 "Rear_Defrost_Pressed" 21 "Pnl_Flr_Ws_Pressed" 20 "Pnl_Ws_Pressed" 19 "Windscreen_Pressed" 18 "Htd_Frt_Wsh_Pressed" 17 "Auto_Recirc_Pressed" 16 "Outside_Pressed" 15 "Recirc_Pressed" 14 "Max_AC_Pressed" 13 "Auto_Pressed" 12 "Blwr_Dec_Pressed" 11 "Blwr_Inc_Pressed" 10 "RHS_Temp_Dec_Pressed" 9 "RHS_Temp_Inc_Pressed" 8 "LHS_Temp_Dec_Pressed" 7 "LHS_Temp_Inc_Pressed" 6 "Dual_Pressed" 5 "AC_Pressed" 4 "Floor_Ws_Pressed" 3 "Floor_Pressed" 2 "Panel_Floor_Pressed" 1 "Panel_Pressed" 0 "None_Pressed" ;
VAL_ 663 BptDchrg_Pw_Dsply 1023 "Faulty" 1022 "NoDataExists" ;
VAL_ 663 Bpt_I_Est 1023 "Faulty" 1022 "NoDataExists" ;
VAL_ 663 Bpt_Pw_Allw 65535 "Faulty" 65534 "NoDataExists" ;
VAL_ 663 BptDchrg_T_Rmng 32767 "Faulty" 32766 "NoDataExists" ;
VAL_ 663 BptMnSoc_L_Actl 8191 "Faulty" 8190 "NoDataExists" ;
VAL_ 1161 BattTracUMxArry_No_Actl 31 "Faulty" ;
VAL_ 1161 BattTracCellUMx_No_Actl 255 "Faulty" 254 "NoDataExists" ;
VAL_ 1161 BattChrgUMx_B_Falt 1 "Yes" 0 "No" ;
VAL_ 1161 BattTracCellUMn_No_Actl 255 "Faulty" 254 "NoDataExists" ;
VAL_ 1161 BattTracCellCnt_No_Actl 255 "Faulty" 254 "NoDataExists" ;
VAL_ 1161 BattChrgIsltn_B_Falt 1 "Yes" 0 "No" ;
VAL_ 1161 BattTracCellDiff_B_Falt 1 "Yes" 0 "No" ;
VAL_ 1161 BattChrgSocMx_B_Falt 1 "Yes" 0 "No" ;
VAL_ 1161 BattChrgSocMn_B_Falt 1 "Yes" 0 "No" ;
VAL_ 1161 BattChrgSocErrtc_B_Falt 1 "Yes" 0 "No" ;
VAL_ 1161 BattTracUMx_B_Falt 1 "Yes" 0 "No" ;
VAL_ 1161 BattTracUMn_B_Falt 1 "Yes" 0 "No" ;
VAL_ 1161 BattTracTeMx_No_Actl 255 "Faulty" 254 "NoDataExists" ;
VAL_ 1161 BattTracTeMx_B_Falt 1 "Yes" 0 "No" ;
VAL_ 1161 BattTracTeMn_No_Actl 255 "Faulty" 254 "NoDataExists" ;
VAL_ 1161 BattTracTeDelta_B_Falt 1 "Yes" 0 "No" ;
VAL_ 1161 BattTracTeCnt_No_Actl 255 "Faulty" 254 "NoDataExists" ;
VAL_ 1161 BattTracSoftware_B_Falt 1 "Yes" 0 "No" ;
VAL_ 1121 OffRdSwtch_D_RqMnu 3 "Faulty" 2 "NoRequest" 1 "On" 0 "Off" ;
VAL_ 1121 SelDrvMdeSwtchOk_D_Stat 3 "Faulty" 2 "Pressed" 1 "NotPressed" 0 "Null" ;
VAL_ 1121 AutoHoldSwtch_D_Stat2 3 "Faulty" 2 "NotUsed" 1 "Pressed" 0 "Not_Pressed" ;
VAL_ 1121 PrkAidSwtch_D_RqDrv3 1 "Pressed" 0 "Not_Pressed" ;
VAL_ 1121 ApaSwtch_D_RqDrv3 3 "NotUsed2" 2 "NotUsed1" 1 "Pressed" 0 "Not_Pressed" ;
VAL_ 1121 StopStrtDrvMde_B_RqBtn2 1 "Pressed" 0 "Not_Pressed" ;
VAL_ 1121 SelDrvMdeSwtch_D_Stat 3 "Faulty" 2 "SwitchState2" 1 "SwitchState1" 0 "NotPressed" ;
VAL_ 1121 SelDrvMdeCnt_D_Stat 4 "FourCounts" 3 "ThreeCounts" 2 "TwoCounts" 1 "OneCount" 0 "ZeroCounts" 7 "SevenOrMoreCounts" 6 "SixCounts" 5 "FiveCounts" ;
VAL_ 669 DrHandleOuterRr_D_Stat 7 "NotUsed" 6 "Transition" 5 "FlushFault" 4 "DeployFault2" 3 "DeployFault1" 2 "Flush" 1 "Deploy" 0 "None" ;
VAL_ 669 DrHandleOuterFr_D_Stat 7 "NotUsed" 6 "Transition" 5 "FlushFault" 4 "DeployFault2" 3 "DeployFault1" 2 "Flush" 1 "Deploy" 0 "None" ;
VAL_ 571 VehFalr_Pc_Est 127 "Faulty" 126 "NoDataExists" ;
VAL_ 571 TrlrTngLoad_Pc_Est 127 "Faulty" 126 "NoDataExists" ;
VAL_ 571 TrlrTngLoad_M_Est 2047 "Faulty" 2046 "NoDataExists" ;
VAL_ 571 VehPayloadAdd_M_Est 2047 "Faulty" 2046 "NoDataExists" ;
VAL_ 571 VehPayload_Pc_Est 127 "Faulty" 126 "NoDataExists" ;
VAL_ 571 VehPayload_M_Est 1023 "Faulty" 1022 "NoDataExists" ;
VAL_ 118 ApaBrkErr_D_Stat 3 "Faulty" 2 "NoDataExists" 1 "Yes" 0 "No" ;
VAL_ 118 BrkCtrFnd_B_Stat 1 "Yes" 0 "No" ;
VAL_ 118 BrkTerrMdeChng_D_Rdy 7 "Fault" 6 "Undefined_2" 5 "Undefined_1" 4 "ModeUnavailDrInputRqd" 3 "SpOpModes_NotSupported" 2 "ModeUnavailDynamicCond" 1 "Module_In_Initialization" 0 "Mode_Change_Available" ;
VAL_ 118 BrkTerrMde_D_Actl 7 "Fail_Safe_Default" 6 "Dynamic_Mode" 5 "Rock_Crawl_Mode" 4 "Mud_Ruts_Mode" 3 "Sand_Mode" 2 "Undefined" 1 "Low_Mu_Mode" 0 "Special_Operating_Mode_Off" ;
VAL_ 118 DrvSte_D_Stat 15 "NotUsed10" 14 "NotUsed9" 13 "NotUsed8" 12 "NotUsed7" 11 "NotUsed6" 10 "NotUsed5" 9 "NotUsed4" 8 "NotUsed3" 7 "NotUsed2" 6 "NotUsed1" 5 "Request_Active" 4 "Ignition_Off" 3 "DSR_in_Normal_Idle_Mode" 2 "EPAS_Comm_Disturbed" 1 "DSR_Request_Not_Applicable" 0 "DSR_Deactivated" ;
VAL_ 118 DrvSte_Tq_Rq 255 "Invalid" 254 "Unknown" ;
VAL_ 118 EmgcyBrkLamp_D_Rq 3 "NotUsed" 2 "Active_at_standstill" 1 "Active_at_speed" 0 "Inactive" ;
VAL_ 118 StopLamp_B_RqBrk 1 "Active" 0 "Inactive" ;
VAL_ 118 SteWhlCompAnEst_D_Qf 3 "OK" 2 "Not_Within_Specifications" 1 "No_Data_Exists" 0 "Faulty" ;
VAL_ 868 E_Frt_Btn_Status_2nd 63 "NotUsed_10" 62 "NotUsed_9" 61 "NotUsed_8" 60 "NotUsed_7" 59 "NotUsed_6" 58 "NotUsed_5" 57 "NotUsed_4" 56 "NotUsed_3" 55 "NotUsed_2" 54 "NotUsed_1" 53 "RHS_Cld_Seat3_Pressed" 52 "RHS_Cld_Seat2_Pressed" 51 "RHS_Cld_Seat1_Pressed" 50 "LHS_Cld_Seat3_Pressed" 49 "LHS_Cld_Seat2_Pressed" 48 "LHS_Cld_Seat1_Pressed" 47 "RHS_Auto_Seat_Pressed" 46 "RHS_Htd_Seat3_Pressed" 45 "RHS_Htd_Seat2_Pressed" 44 "RHS_Htd_Seat1_Pressed" 43 "RHS_Seat_Off_Pressed" 42 "LHS_Auto_Seat_Pressed" 41 "LHS_Htd_Seat3_Pressed" 40 "LHS_Htd_Seat2_Pressed" 39 "LHS_Htd_Seat1_Pressed" 38 "LHS_Seat_Off_Pressed" 37 "DrvrFcsdMde_Pressed" 36 "MdeMnu_Pressed" 35 "AAR_Pressed" 34 "Heat_Pressed" 33 "RearMnu_Pressed" 32 "FrontMnu_Pressed" 31 "Defrost_Pressed" 30 "Htg_Strg_Whl_Pressed" 29 "RHS_Cld_Seat_Pressed" 28 "LHS_Cld_Seat_Pressed" 27 "RHS_Htd_Seat_Pressed" 26 "LHS_Htd_Seat_Pressed" 25 "Max_Defrost_Pressed" 24 "My_Temp_Pressed" 23 "Front_Power_Pressed" 22 "Rear_Defrost_Pressed" 21 "Pnl_Flr_Ws_Pressed" 20 "Pnl_Ws_Pressed" 19 "Windscreen_Pressed" 18 "Htd_Frt_Wsh_Pressed" 17 "Auto_Recirc_Pressed" 16 "Outside_Pressed" 15 "Recirc_Pressed" 14 "Max_AC_Pressed" 13 "Auto_Pressed" 12 "Blwr_Dec_Pressed" 11 "Blwr_Inc_Pressed" 10 "RHS_Temp_Dec_Pressed" 9 "RHS_Temp_Inc_Pressed" 8 "LHS_Temp_Dec_Pressed" 7 "LHS_Temp_Inc_Pressed" 6 "Dual_Pressed" 5 "AC_Pressed" 4 "Floor_Ws_Pressed" 3 "Floor_Pressed" 2 "Panel_Floor_Pressed" 1 "Panel_Pressed" 0 "None_Pressed" ;
VAL_ 868 E_Frt_Btn_Status_1st 63 "NotUsed_10" 62 "NotUsed_9" 61 "NotUsed_8" 60 "NotUsed_7" 59 "NotUsed_6" 58 "NotUsed_5" 57 "NotUsed_4" 56 "NotUsed_3" 55 "NotUsed_2" 54 "NotUsed_1" 53 "RHS_Cld_Seat3_Pressed" 52 "RHS_Cld_Seat2_Pressed" 51 "RHS_Cld_Seat1_Pressed" 50 "LHS_Cld_Seat3_Pressed" 49 "LHS_Cld_Seat2_Pressed" 48 "LHS_Cld_Seat1_Pressed" 47 "RHS_Auto_Seat_Pressed" 46 "RHS_Htd_Seat3_Pressed" 45 "RHS_Htd_Seat2_Pressed" 44 "RHS_Htd_Seat1_Pressed" 43 "RHS_Seat_Off_Pressed" 42 "LHS_Auto_Seat_Pressed" 41 "LHS_Htd_Seat3_Pressed" 40 "LHS_Htd_Seat2_Pressed" 39 "LHS_Htd_Seat1_Pressed" 38 "LHS_Seat_Off_Pressed" 37 "DrvrFcsdMde_Pressed" 36 "MdeMnu_Pressed" 35 "AAR_Pressed" 34 "Heat_Pressed" 33 "RearMnu_Pressed" 32 "FrontMnu_Pressed" 31 "Defrost_Pressed" 30 "Htg_Strg_Whl_Pressed" 29 "RHS_Cld_Seat_Pressed" 28 "LHS_Cld_Seat_Pressed" 27 "RHS_Htd_Seat_Pressed" 26 "LHS_Htd_Seat_Pressed" 25 "Max_Defrost_Pressed" 24 "My_Temp_Pressed" 23 "Front_Power_Pressed" 22 "Rear_Defrost_Pressed" 21 "Pnl_Flr_Ws_Pressed" 20 "Pnl_Ws_Pressed" 19 "Windscreen_Pressed" 18 "Htd_Frt_Wsh_Pressed" 17 "Auto_Recirc_Pressed" 16 "Outside_Pressed" 15 "Recirc_Pressed" 14 "Max_AC_Pressed" 13 "Auto_Pressed" 12 "Blwr_Dec_Pressed" 11 "Blwr_Inc_Pressed" 10 "RHS_Temp_Dec_Pressed" 9 "RHS_Temp_Inc_Pressed" 8 "LHS_Temp_Dec_Pressed" 7 "LHS_Temp_Inc_Pressed" 6 "Dual_Pressed" 5 "AC_Pressed" 4 "Floor_Ws_Pressed" 3 "Floor_Pressed" 2 "Panel_Floor_Pressed" 1 "Panel_Pressed" 0 "None_Pressed" ;
VAL_ 868 Rr_Blower_Indicate_Stat 15 "Display_Blank" 14 "14_Indicators_On" 13 "13_Indicators_On" 12 "12_Indicators_On" 11 "11_Indicators_On" 10 "10_Indicators_On" 9 "9_Indicators_On" 8 "8_Indicators_On" 7 "7_Indicators_On" 6 "6_Indicators_On" 5 "5_Indicators_On" 4 "4_Indicators_On" 3 "3_Indicators_On" 2 "2_Indicators_On" 1 "1_Indicator_On" 0 "Indicators_Off" ;
VAL_ 836 FohFalt_D_Stat 15 "NotUsed4" 14 "NotUsed3" 13 "NotUsed2" 12 "NotUsed1" 11 "FuelTypeDoesNotMatchFOH" 10 "Lifecycle_ModeNotSet" 9 "AuxElectricCoolantPumpInop" 8 "TimeDelayAvoidExcessCycl" 7 "Fuel_Level_OutofRange" 6 "External_Fault" 5 "Internal_Fault" 4 "Voltage_limitation" 3 "Impact_Event" 2 "CoolantTemp_OutofRange" 1 "AmbientTemp_OutofRange" 0 "No_Disable" ;
VAL_ 836 FohEnbl_B_RqDrv 1 "On" 0 "Off" ;
VAL_ 836 FohRqRun_B_Rq 1 "SubmitRequest_toRun" 0 "DoesNotSubmitRequest_toRun" ;
VAL_ 836 HvacPrecondMode_D_Rq 15 "NotUsed4" 14 "NotUsed3" 13 "NotUsed2" 12 "NotUsed1" 11 "Last_User_Settings" 10 "Auto" 9 "Max_Defrost" 8 "Windshield_Panel_Floor" 7 "Windshield_Panel" 6 "Windshield" 5 "Windshield_Floor" 4 "Floor" 3 "Panel_Floor" 2 "Panel" 1 "MAX_AC" 0 "Off" ;
VAL_ 836 HvacPrecondBlwr_D_Rq 15 "NotUsed6" 14 "NotUsed5" 13 "NotUsed4" 12 "NotUsed3" 11 "NotUsed2" 10 "NotUsed1" 9 "Last_User_Setting" 8 "Auto" 7 "Speed7" 6 "Speed6" 5 "Speed5" 4 "Speed4" 3 "Speed3" 2 "Speed2" 1 "Speed1" 0 "Off" ;
VAL_ 836 Foh_D_Stat 7 "Unused3" 6 "Unused2" 5 "Unused1" 4 "Stopping" 3 "Running" 2 "Starting" 1 "Prestart" 0 "Off" ;
VAL_ 836 EngClnt_Te_ActlFoh 255 "Fault" ;
VAL_ 613 BeltWarnThres_D_Stat 7 "Faulty" 6 "No_Data_Exists" 5 "NotUsed3" 4 "NotUsed2" 3 "NotUsed1" 2 "Over_Threshold" 1 "Under_Threshold" 0 "NotSupported" ;
VAL_ 613 VehicleMYCalibrationId 255 "Invalid" ;
VAL_ 613 VehicleCalibrationId 255 "Invalid" ;
VAL_ 613 OCSSensrDataUpperLim 255 "Invalid" ;
VAL_ 613 OCSSensrDataLowerLim 255 "Invalid" ;
VAL_ 613 OCSLevel2Error 1 "Yes" 0 "No" ;
VAL_ 613 ObjectEntrapped 1 "Yes" 0 "No" ;
VAL_ 613 OCSLevel1Error 1 "Yes" 0 "No" ;
VAL_ 1084 BattULoState_D_Qlty 3 "OK" 2 "Not_Within_Specifications" 1 "Eval_In_Progress" 0 "Fault" ;
VAL_ 1084 BSFault 1 "Fault" 0 "No_Fault" ;
VAL_ 1084 BattULo2_Te_Actl 127 "Fault" ;
VAL_ 1059 EngStrtInhbt_B_RqBatt 1 "Start_Inhibit" 0 "Dont_Care" ;
VAL_ 1059 BattULoChrg_D_Rq 3 "Low_Battery_Temperature" 2 "Charging_Requested" 1 "Chrg_Requested_HighCurrent" 0 "No_Request" ;
VAL_ 1059 PwSysULoFalt_D_Stat 15 "Not_Used_6" 14 "LowBatterySOC" 13 "PSS_Shed2_Contin" 12 "Not_Used_4" 11 "Not_Used_3" 10 "Not_Used_2" 9 "BattMonitoringSensorFault" 8 "LowBattVoltDuringPwSrcOn" 7 "LowBatt2_PowerSaveMode" 6 "LowBatt1_Warning" 5 "Overvoltage" 4 "Fault_NoOutput" 3 "Fault_ReducedOutput" 2 "Fault_Nonspecific" 1 "Cluster_Proveout" 0 "No_Fault" ;
VAL_ 1059 Shed_T_Eng_Off_B 1 "Active" 0 "Inactive" ;
VAL_ 1059 Shed_Feature_Group_ID 16 "PtcHeater" 30 "NotUsed_7" 29 "NotUsed_6" 28 "NotUsed_5" 27 "NotUsed_4" 26 "NotUsed_3" 25 "NotUsed_2" 24 "NotUsed_1" 23 "Dcac" 22 "UpFitter_6" 21 "UpFitter_5" 20 "UpFitter_4" 19 "UpFitter_3" 18 "UpFitter_2" 17 "UpFitter_1" 14 "HtdMirr" 13 "HvacRearBlwr_Third" 12 "HvacRearBlwr_Second" 11 "HvacRearBlwr_First" 31 "All LSHED1 Features" 10 "Htd_Windscrn" 9 "SpltHtdBcklight_HtdMirr" 8 "HtdBcklight_HtdMirr" 7 "HtdCoolSeat_FrtDriver" 6 "HtdCoolSeat_FrtPass" 5 "HtdCoolSeat_RearPass" 4 "HtdCoolSeat_RearDriver" 3 "SmartTrlrTowBattCharge" 2 "Htd_StrWhl" 1 "Htd_Washer_Fluid" 0 "No_LSHED1_Features" 15 "Engine_Coolant_Fan" ;
VAL_ 1059 Shed_Drain_Eng_Off_B 1 "Active" 0 "Inactive" ;
VAL_ 1059 Shed_Level_Req 7 "SHED3" 6 "Loads_On" 5 "SHED_ENG_OFF" 4 "SOON_ENG_OFF" 3 "SHED2_CONTIN" 2 "SHED2_TRANS" 1 "SHED1" 0 "NO_SHED" ;
VAL_ 1059 ULoRgenTestMde_B_Rq 1 "Request" 0 "NoRequest" ;
VAL_ 1059 ChargeMode 7 "Undefined_2" 6 "Undefined_1" 5 "Battery_Identify" 4 "Battery_Refresh" 3 "SlowRegenAllowNoDischarge" 2 "Fast_Regen_Allowed" 1 "Slow_Regen_Allowed" 0 "Conventional_Charging" ;
VAL_ 1059 IdleSpeedIncrease_El 1 "Yes" 0 "No" ;
VAL_ 1059 Batt_Lo_SoC_B 1 "Active" 0 "Inactive" ;
VAL_ 1059 PeriodicElLoad_B_Stat 1 "Active" 0 "Inactive" ;
VAL_ 1059 Batt_Crit_SoC_B 1 "Active" 0 "Inactive" ;
VAL_ 131 HeadLghtHiCtrl_D_RqAhb 7 "NotUsed2" 6 "NotUsed1" 5 "Auto_HiBeam" 4 "Auto_LoBeam" 3 "Flash" 2 "Man_HiBeam" 1 "Man_LoBeam" 0 "Null" ;
VAL_ 131 AhbStat_B_Dsply 1 "On" 0 "Off" ;
VAL_ 131 WiprFrontSwtch_D_Stat 15 "NotUsed6" 14 "NotUsed5" 13 "NotUsed4" 12 "NotUsed3" 11 "NotUsed2" 10 "NotUsed1" 9 "PositionNotDetermined" 8 "High" 7 "Low" 6 "Position6" 5 "Position5" 4 "Position4" 3 "Position3" 2 "Position2" 1 "Position1" 0 "Off" ;
VAL_ 131 HeadLghtHiOn_B_StatAhb 1 "On" 0 "Off" ;
VAL_ 131 HeadLghtHiFlash_D_Actl 3 "NotUsed" 2 "High" 1 "Flash_to_Pass" 0 "Null" ;
VAL_ 131 TjaButtnOnOffPress 1 "Pressed" 0 "Not_Pressed" ;
VAL_ 131 AccButtnGapTogglePress 1 "Pressed" 0 "Not_Pressed" ;
VAL_ 131 WiprFront_D_Stat 15 "NO_DATA_EXISTS" 14 "STALLED" 13 "RESERVED" 12 "AUTO_ADJUST" 11 "COURTESYWIPE" 10 "AUTO_HIGH" 9 "AUTO_LOW" 8 "WASH" 7 "MIST_FLICK" 6 "MAN_HIGH" 5 "MAN_LOW" 4 "MAN_INT_ON" 3 "MAN_INT_OFF" 2 "OFF_MOVING" 1 "AUTO_OFF" 0 "OFF" ;
VAL_ 131 TurnLghtSwtch_D_Stat 3 "Unused_Treat_As_Off" 2 "Right" 1 "Left" 0 "Off" ;
VAL_ 131 LghtAmb_D_Sns 7 "No_Data_Exists" 6 "Unused2" 5 "Unused1" 4 "Tunnel_Off" 3 "Tunnel_On" 2 "Twilight" 1 "Light" 0 "Dark" ;
VAL_ 131 AccButtnGapIncPress 1 "Button_Pressed" 0 "Button_Not_Pressed" ;
VAL_ 131 AccButtnGapDecPress 1 "Button_Pressed" 0 "Button_Not_Pressed" ;
VAL_ 131 AslButtnOnOffPress 1 "Button_Pressed" 0 "Button_Not_Pressed" ;
VAL_ 131 AslButtnOnOffCnclPress 1 "Button_Pressed" 0 "Button_Not_Pressed" ;
VAL_ 131 CcButtnOnPress 1 "Button_Pressed" 0 "Button_Not_Pressed" ;
VAL_ 131 CcButtnOnOffPress 1 "Button_Pressed" 0 "Button_Not_Pressed" ;
VAL_ 131 CcButtnOnOffCnclPress 1 "Button_Pressed" 0 "Button_Not_Pressed" ;
VAL_ 131 CcButtnOffPress 1 "Button_Pressed" 0 "Button_Not_Pressed" ;
VAL_ 131 CcAsllButtnResPress 1 "Button_Pressed" 0 "Button_Not_Pressed" ;
VAL_ 131 CcAslButtnSetPress 1 "Button_Pressed" 0 "Button_Not_Pressed" ;
VAL_ 131 CcAslButtnSetIncPress 1 "Button_Pressed" 0 "Button_Not_Pressed" ;
VAL_ 131 CcAslButtnSetDecPress 1 "Button_Pressed" 0 "Button_Not_Pressed" ;
VAL_ 131 CcAslButtnResIncPress 1 "Button_Pressed" 0 "Button_Not_Pressed" ;
VAL_ 131 CcAslButtnResDecPress 1 "Button_Pressed" 0 "Button_Not_Pressed" ;
VAL_ 131 CcAslButtnOnPress 1 "Button_Pressed" 0 "Button_Not_Pressed" ;
VAL_ 131 CcAslButtnOnOffCncl 1 "Button_Pressed" 0 "Button_Not_Pressed" ;
VAL_ 131 CcAslButtnOffCnclPress 1 "Button_Pressed" 0 "Button_Not_Pressed" ;
VAL_ 131 CcAslButtnIndxIncPress 1 "Button_Pressed" 0 "Button_Not_Pressed" ;
VAL_ 131 CcAslButtnIndxDecPress 1 "Button_Pressed" 0 "Button_Not_Pressed" ;
VAL_ 131 CcAslButtnDeny_B_Actl 1 "Yes" 0 "No" ;
VAL_ 131 CcAslButtnCnclResPress 1 "Button_Pressed" 0 "Button_Not_Pressed" ;
VAL_ 131 CcAslButtnCnclPress 1 "Button_Pressed" 0 "Button_Not_Pressed" ;
VAL_ 131 LaSwtchPos_D_Stat 3 "Fault" 2 "Unused" 1 "Pressed" 0 "Open" ;
VAL_ 931 VehOnSrc_D_Stat 15 "NotUsed_11" 14 "NotUsed_10" 13 "NotUsed_9" 12 "NotUsed_8" 11 "NotUsed_7" 10 "NotUsed_6" 9 "EsclRssd" 8 "AutonomousVehicle" 7 "SecureIdle" 6 "FleetVehicleInhibit" 5 "StolenVehicleInhibit" 4 "OverTheAir" 3 "RemoteParkAssist" 2 "RemoteStart" 1 "Manual" 0 "Off" ;
VAL_ 931 EngStrtActv_B_Stat 1 "Active" 0 "Inactive" ;
VAL_ 931 EngStrt_B_Rq 1 "Request" 0 "NoRequest" ;
VAL_ 931 DrvInCtl_B_Stat 1 "Yes" 0 "No" ;
VAL_ 931 PtWakeReas_D_Stat 15 "NotUsed_9" 14 "NotUsed_8" 13 "NotUsed_7" 12 "NotUsed_6" 11 "NotUsed_5" 10 "NotUsed_4" 9 "NotUsed_3" 8 "NotUsed_2" 7 "NotUsed_1" 6 "ElapsedTime" 5 "ThirdPartyWakeup" 4 "DoorAjar" 3 "EarlyWake" 2 "NonMotiveStart" 1 "MotiveStart" 0 "Null" ;
VAL_ 931 CrnkInhbt_B_Stat 1 "Inhibit" 0 "NoInhibit" ;
VAL_ 931 IgnPreOffActv_B_Stat 1 "Active" 0 "Inactive" ;
VAL_ 618 PaakLoclzd_D_Stat 15 "NotUsed_12" 14 "NotUsed_11" 13 "NotUsed_10" 12 "NotUsed_9" 11 "NotUsed_8" 10 "NotUsed_7" 9 "NotUsed_6" 8 "NotUsed_5" 7 "NotUsed_4" 6 "NotUsed_3" 5 "NotUsed_2" 4 "NotUsed_1" 3 "FullLoc" 2 "PausedLoc" 1 "MaintainLink" 0 "BackgroundScan" ;
VAL_ 618 IgnPsswrdSetup_B_Rq 1 "Active" 0 "Inactive" ;
VAL_ 618 IgnPsswrdLckout_B_Stat 1 "Active" 0 "Inactive" ;
VAL_ 618 PaakCtlType_D_Stat 3 "NotUsed" 2 "Valid" 1 "Invalid" 0 "Null" ;
VAL_ 618 PaakCtlData_D_Stat 7 "NotUsed_3" 6 "NotUsed_2" 5 "NotUsed_1" 4 "Response" 3 "EchoTargetIdBlock1" 2 "RequestTargetIdBlock2" 1 "RequestTargetIdBlock1" 0 "Idle" ;
VAL_ 621 IgnPsswrdActv_B_Stat 1 "Active" 0 "Inactive" ;
VAL_ 621 FobTrgtZone_D_Rq 15 "NotUsed_9" 14 "NotUsed_8" 13 "NotUsed_7" 12 "NotUsed_6" 11 "NotUsed_5" 10 "NotUsed_4" 9 "NotUsed_3" 8 "NotUsed_2" 7 "NotUsed_1" 6 "Approach" 5 "RearInterior" 4 "RearExterior" 3 "Passenger" 2 "Driver" 1 "Interior" 0 "Null" ;
VAL_ 621 FobTrgtType_D_Rq 7 "NotUsed_4" 6 "NotUsed_3" 5 "NotUsed_2" 4 "NotUsed_1" 3 "Polling" 2 "Registry" 1 "Crypto" 0 "Null" ;
VAL_ 621 RmtCtlRjctAutoCfg_B_Rq 1 "Yes" 0 "No" ;
VAL_ 621 RmtCtlSelSlot_D_Rq 7 "NotUsed_3" 6 "NotUsed_2" 5 "NotUsed_1" 4 "Right" 3 "Left" 2 "Rear" 1 "Front" 0 "None" ;
VAL_ 621 RmtCtlSelPrkMde_D_Rq 3 "NotUsed" 2 "FreeDrive" 1 "ParkIn" 0 "None" ;
VAL_ 621 RmtCtlSelMoveDir_D_Rq 3 "NotUsed" 2 "Backward" 1 "Forward" 0 "None" ;
VAL_ 1016 ChrgGoTElement_B_Dsply 1 "Yes" 0 "No" ;
VAL_ 1016 ChrgGoTTouchEnbl_B_Rq 1 "Request" 0 "NoRequest" ;
VAL_ 1016 ChrgGoTTouch_B_Stat 1 "On" 0 "Off" ;
VAL_ 1016 ChrgGoTPrcond_D_Stat 3 "High" 2 "Medium" 1 "Low" 0 "Off" ;
VAL_ 1016 ChrgGoTMnte_D_Stat 15 "NotUsed_4" 14 "NotUsed_3" 13 "NotUsed_2" 12 "NotUsed_1" 11 "Minute_55" 10 "Minute_50" 9 "Minute_45" 8 "Minute_40" 7 "Minute_35" 6 "Minute_30" 5 "Minute_25" 4 "Minute_20" 3 "Minute_15" 2 "Minute_10" 1 "Minute_5" 0 "Minute_0" ;
VAL_ 1016 ChrgGoTHr_T_Stat 31 "Faulty" 30 "NoDataExists" ;
VAL_ 1016 ChrgGoTExtHtrEnbl_B_Rq 1 "Request" 0 "NoRequest" ;
VAL_ 1016 ChrgGoTExtHtr_B_Stat 1 "On" 0 "Off" ;
VAL_ 1016 ChrgGoTAllOn_B_Stat 1 "On" 0 "Off" ;
VAL_ 773 StmsScrnPsngrOn_B_Rq 1 "On" 0 "Off" ;
VAL_ 773 SeatScrnPsngrOn_B_Rq 1 "On" 0 "Off" ;
VAL_ 773 SeatPsngrMem_D_Cmd 15 "NotUsed_7" 14 "NotUsed_6" 13 "NotUsed_5" 12 "NotUsed_4" 11 "NotUsed_3" 10 "NotUsed_2" 9 "NotUsed_1" 8 "RECALL_4" 7 "RECALL_3" 6 "RECALL_2" 5 "RECALL_1" 4 "STORE_4" 3 "STORE_3" 2 "STORE_2" 1 "STORE_1" 0 "Null" ;
VAL_ 773 MemSwtchPsngrFdbck_B_Rq 1 "Yes" 0 "No" ;
VAL_ 389 HtrnSrvcRqd_B_Dsply 1 "On" 0 "Off" ;
VAL_ 389 HtrnOvrTeLamp_B_Dsply 1 "On" 0 "Off" ;
VAL_ 389 HtrnMil_D_Rq 3 "Not_Used" 2 "Flash" 1 "On" 0 "Off" ;
VAL_ 389 HtrnAin_UHi_Actl 1023 "Fault" 1022 "Unknown" ;
VAL_ 389 HtrnHvilOpen_B_Actl 1 "HVIL_is_Open" 0 "Normal_Operation" ;
VAL_ 389 PtWakeupDeltaT_T_Rq 2047 "Fault" 2046 "NoDataExists" ;
VAL_ 389 PreCondActv_B_Actl 1 "On" 0 "Off" ;
VAL_ 389 DrvCondTpRrDefrs_B_Rq 1 "On" 0 "Off" ;
VAL_ 389 BattTrac_I_EstVsc 32767 "Fault" 32766 "NoDataExists" ;
VAL_ 1128 DgtlCommGtwyMde_D_Rq 15 "NotUsed_10" 14 "NotUsed_9" 13 "NotUsed_8" 12 "NotUsed_7" 11 "NotUsed_6" 10 "NotUsed_5" 9 "NotUsed_4" 8 "NotUsed_3" 7 "NotUsed_2" 6 "NotUsed_1" 5 "AcPnC" 4 "AcEIM" 3 "DcPnC" 2 "DcEIM" 1 "AttemptDgtlComm" 0 "NoDgtlComm" ;
VAL_ 1128 ChrgrDcOvrVolt_B_Falt 1 "Yes" 0 "No" ;
VAL_ 1128 ChrgrDcOvrCurnt_B_Falt 1 "Yes" 0 "No" ;
VAL_ 1128 ExtChrgNowButtn_B_Rq 1 "Request" 0 "NoRequest" ;
VAL_ 1128 CoolFanChrgr_D_Rq 3 "High" 2 "Medium" 1 "Low" 0 "Off" ;
VAL_ 1128 ChrgrPncEnbl_D_Stat 3 "NotUsed" 2 "Enable" 1 "Disable" 0 "Null" ;
VAL_ 1128 ChrgrClntFlw_D_Rq 3 "High" 2 "Medium" 1 "Low" 0 "Off" ;
VAL_ 1128 PlgStatEvnt_B_Stat 1 "Active" 0 "Inactive" ;
VAL_ 1128 ChrgrCnnctPwr_B_Stat 1 "Asserted" 0 "NotAsserted" ;
VAL_ 1128 ChrgrAvailEvnt_B_Stat 1 "Active" 0 "Inactive" ;
VAL_ 1128 ChrgrSrvcRqd_B_Rq 1 "On" 0 "Off" ;
VAL_ 1128 ChrgrS2Swtch_B_Stat 1 "Close" 0 "Open" ;
VAL_ 1128 ChrgChngEvnt_B_Stat 1 "Active" 0 "Inactive" ;
VAL_ 1128 ChrgrCc2Cnnct_B_Falt 1 "Yes" 0 "No" ;
VAL_ 1128 ChrgPortDcTeMx_B_Falt 1 "Yes" 0 "No" ;
VAL_ 1128 ChrgCordLck_D_Stat 7 "Faulty" 6 "LockFail" 5 "UnlockFail" 4 "LockInProgress" 3 "UnlockInProgress" 2 "Lock" 1 "Unlock" 0 "Retain" ;
VAL_ 1128 ChrgrInPwMde_D_Actl 15 "NotUsed_5" 14 "NotUsed_4" 13 "NotUsed_3" 12 "NotUsed_2" 11 "NotUsed_1" 10 "DcBpt" 9 "DigitalCommEnd" 8 "EvseFault" 7 "EvseNotCompatible" 6 "IcCharging" 5 "DcCharging" 4 "AcDigital" 3 "AcBasic" 2 "DigitalCommDetected" 1 "EvsePaused" 0 "EvseNotDetected" ;
VAL_ 1128 ChrgPortDrOpen_B_Stat 1 "True" 0 "False" ;
VAL_ 1128 AcChrgRdy_B_Stat 1 "True" 0 "False" ;
VAL_ 1128 BptTgl_B_Complt 1 "Yes" 0 "No" ;
VAL_ 1128 ChrgCrdLck_D_Falt 3 "NotUsed" 2 "HardwareFault" 1 "CsiFault" 0 "NoFault" ;
VAL_ 594 HvacAirFlw_B_RqBatt 1 "Request" 0 "NoRequest" ;
VAL_ 594 BattChrgRdyStat_D_Actl 7 "NotUsed2" 6 "NotUsed1" 5 "Faulted" 4 "ChargeComplete" 3 "Charging" 2 "BatteryChargeReady" 1 "ChargeWait" 0 "NotReady" ;
VAL_ 594 BattTracSoc_Pc_Dsply 255 "Faulty" 254 "NoDataExists" ;
VAL_ 594 BattTracSoc2_Pc_Actl 16383 "Faulty" 16382 "NoDataExists" ;
VAL_ 594 BattTracCool_D_Falt 3 "NotUsed" 2 "CoolSysPartialyOperational" 1 "Cooling_System_Faulted" 0 "Cooling_System_Operational" ;
VAL_ 594 BattTracClntIn_Te_Actl 255 "Fault" ;
VAL_ 594 BattTrac_Te_Actl 1023 "Fault" 1022 "Unknown" ;
VAL_ 594 HvacRec_D_RqMxBatt 15 "NotUsed5" 14 "NotUsed4" 13 "NotUsed3" 12 "NotUsed2" 11 "NotUsed1" 10 "No_Override" 9 "90Percent_RecircMax" 8 "80Percent_RecircMax" 7 "70Percent_RecircMax" 6 "60Percent_RecircMax" 5 "50Percent_RecircMax" 4 "40Percent_RecircMax" 3 "30Percent_RecircMax" 2 "20Percent_RecircMax" 1 "10Percent_RecircMax" 0 "0Percent_RecircFullOpen" ;
VAL_ 594 HvacAir_Flw_EstBatt 255 "Invalid" ;
VAL_ 932 RmtCtlBattMntr_B_Falt 1 "Yes" 0 "No" ;
VAL_ 932 VehStrtInhbt_D_Stat 1 "Inhibit" 0 "NoInhibit" ;
VAL_ 932 VehOnCtl_D_Stat 3 "NotUsed" 2 "On" 1 "Off" 0 "Null" ;
VAL_ 932 VehOnSrc2_D_Stat 15 "NotUsed_11" 14 "NotUsed_10" 13 "NotUsed_9" 12 "NotUsed_8" 11 "NotUsed_7" 10 "NotUsed_6" 9 "EsclRssd" 8 "AutonomousVehicle" 7 "SecureIdle" 6 "FleetVehicleInhibit" 5 "StolenVehicleInhibit" 4 "OverTheAir" 3 "RemoteParkAssist" 2 "RemoteStart" 1 "Manual" 0 "Off" ;
VAL_ 932 VehInhbtMde_D_Stat 7 "NotUsed_3" 6 "NotUsed_2" 5 "NotUsed_1" 4 "FullVehicleOta" 3 "Iviota" 2 "SyncOta" 1 "NoOtaSupport" 0 "Unconfigured" ;
VAL_ 528 TireInflateMsgTxt_B_Rq 1 "Yes" 0 "No" ;
VAL_ 528 OffRoadMde_D_Stat 7 "NotUsed_5" 6 "NotUsed_4" 5 "NotUsed_3" 4 "NotUsed_2" 3 "NotUsed_1" 2 "Off_Road2" 1 "Off_Road1" 0 "On_Road" ;
VAL_ 591 BattTrac_U_Nom 1023 "Faulty" 1022 "NoDataExists" ;
VAL_ 591 BattTrac_E_Nom 4095 "Faulty" 4094 "NoDataExists" ;
VAL_ 591 BattTrac_Ah_Nom 4095 "Faulty" ;
VAL_ 591 BattTracType_D_Actl 15 "NotUsed_7" 14 "NotUsed_6" 13 "NotUsed_5" 12 "NotUsed_4" 11 "NotUsed_3" 10 "NotUsed_2" 9 "NotUsed_1" 8 "Other" 7 "LithiumTitanateOxide" 6 "LithiumIonPolymer" 5 "TernaryMaterial" 4 "LithiumCobaltOxide" 3 "LithiumManganese" 2 "LithiumIronPhosphate" 1 "NickelMetalHydride" 0 "LeadAcid" ;
VAL_ 591 BattChrgRqd_E_Actl 4095 "Faulty" 4094 "NoDataExists" ;
VAL_ 595 DrvIdMde_D_Rq 7 "Faulty" 6 "NotUsed_2" 5 "NotUsed_1" 4 "DeleteMid" 3 "ClearAll" 2 "Enroll" 1 "Recognize" 0 "Disable" ;
VAL_ 596 DrvIdMde_D_Stat 7 "NotUsed_3" 6 "NotUsed_2" 5 "NotUsed_1" 4 "DeleteMid" 3 "ClearAll" 2 "Enroll" 1 "Recognize" 0 "Null" ;
VAL_ 596 DrvIdActn_D_Stat 3 "NotUsed" 2 "Success" 1 "Fail" 0 "Null" ;
VAL_ 596 DrvId_D_Stat 7 "NotUsed_3" 6 "NotUsed_2" 5 "NotUsed_1" 4 "FailTimeout" 3 "FailWeakMatch" 2 "OkNoMatch" 1 "OkMatched" 0 "Null" ;
VAL_ 596 DrvExpression_D_Stat 15 "NotUsed_5" 14 "NotUsed_4" 13 "NotUsed_3" 12 "NotUsed_2" 11 "NotUsed_1" 10 "HasRegister" 9 "ConstraintsOk" 8 "NotAFace" 7 "PoorTrackingQuality" 6 "EyesNotVisible" 5 "FaceBlockage" 4 "MouthOpen" 3 "OutsidePoseLimits" 2 "TooManyFaces" 1 "FaceNotInView" 0 "Null" ;
VAL_ 966 NfcDevc_D_Dsply 15 "Message 15" 14 "Message 14" 13 "Message 13" 12 "Message 12" 11 "Message 11" 10 "Message 10" 9 "Message 9" 8 "Message 8" 7 "Message 7" 6 "Message 6" 5 "Message 5" 4 "Message 4" 3 "Message 3" 2 "Message 2" 1 "Message 1" 0 "No message" ;
VAL_ 966 PwTrnkFrntRelay_B_Stat 1 "Inhibit" 0 "NoInhibit" ;
VAL_ 966 PwTrnkFrontRleas_D_Src 15 "NotUsed_5" 14 "NotUsed_4" 13 "NotUsed_3" 12 "NotUsed_2" 11 "NotUsed_1" 10 "SelfTest" 9 "Diagnostics" 8 "EmergencyReleaseSwitch" 7 "ManualCinch" 6 "ExteriorSwitch" 5 "IpSwitch" 4 "Cpp" 3 "Sync" 2 "Keypad" 1 "Remote" 0 "PowerOff" ;
VAL_ 966 TrnkFrontScnd_B_Falt 1 "Fault" 0 "NoFault" ;
VAL_ 966 ExtLghtRear_D_RqBody 3 "NotUsed" 2 "On" 1 "Off" 0 "Null" ;
VAL_ 966 TrnkFrontInhbt_B_Stat 1 "Inhibit" 0 "NoInhibit" ;
VAL_ 966 TrnkFrontRleas_D_Src 7 "NotUsed_3" 6 "NotUsed_2" 5 "NotUsed_1" 4 "Cpp" 3 "Sync" 2 "Keypad" 1 "Remote" 0 "Null" ;
VAL_ 966 VehHorn_D_RqAlrt 3 "NotUsed" 2 "Null" 1 "On" 0 "Off" ;
VAL_ 966 VehHorn_D_Rq 15 "NotUsed_7" 14 "NotUsed_6" 13 "NotUsed_5" 12 "NotUsed_4" 11 "NotUsed_3" 10 "NotUsed_2" 9 "NotUsed_1" 8 "Chirp_3" 7 "ManualOn" 6 "Honk" 5 "ChirpHonk" 4 "Chirp_2H" 3 "Chirp_2" 2 "Chirp_1" 1 "Null" 0 "Off" ;
VAL_ 966 ScrtyHornActv_B_Rq 1 "Active" 0 "Inactive" ;
VAL_ 1104 DrvEngageLevel_D_Stat 7 "Faulty" 6 "NotUsed_2" 5 "NotUsed_1" 4 "Disengaged" 3 "Distracted" 2 "Attentive" 1 "Invalid" 0 "NotDetermined" ;
VAL_ 1104 DrvImpLvlConfid_D_Stat 7 "Faulty" 6 "NotUsed" 5 "High" 4 "MediumHigh" 3 "Medium" 2 "LowMedium" 1 "Low" 0 "NotDetermined" ;
VAL_ 1104 DrvImpairLvl_D_Stat 15 "Faulty" 14 "NotUsed_5" 13 "NotUsed_4" 12 "NotUsed_3" 11 "NotUsed_2" 10 "NotUsed_1" 9 "Incapacitated" 8 "Asleep" 7 "Microsleep" 6 "MostDrowsy" 5 "Drowsy_4" 4 "Drowsy_3" 3 "Drowsy_2" 2 "LeastDrowsy" 1 "Alert" 0 "NotDetermined" ;
VAL_ 1104 DrvEngLvlConfid_D_Stat 7 "Faulty" 6 "NotUsed" 5 "High" 4 "MediumHigh" 3 "Medium" 2 "LowMedium" 1 "Low" 0 "NotDetermined" ;
VAL_ 1104 DrvCamPassIR_D_Stat 3 "Faulty" 2 "Blocked" 1 "Ok" 0 "TemporaryUnavailable" ;
VAL_ 1104 DrvCamera_D_Stat 3 "Faulty" 2 "Blocked" 1 "Ok" 0 "TemporaryUnavailable" ;
VAL_ 1104 DrvCamDrvIR_D_Stat 3 "Faulty" 2 "Blocked" 1 "Ok" 0 "TemporaryUnavailable" ;
VAL_ 1104 DrvAttentZone_D_Stat 15 "Faulty" 14 "NotUsed_5" 13 "NotUsed_4" 12 "NotUsed_3" 11 "NotConfigured" 10 "DriverLap" 9 "PassengerSideWindow" 8 "DriverSideWindow" 7 "DriverSideMirror" 6 "RearviewMirror" 5 "PassengerSideMirror" 4 "Infotainment" 3 "Cluster" 2 "FrontWindshield" 1 "Other" 0 "NotDetermined" ;
VAL_ 1104 DrvAlertSt_D_Stat 3 "Faulty" 2 "EyesOffRoad" 1 "EyesOnRoad" 0 "NotDetermined" ;
VAL_ 303 DrStatHood_D2_Actl 5 "NotUsed_2" 4 "NotUsed_1" 3 "Disabled" 2 "Ajar" 1 "Closed" 0 "NotDetermined" 7 "Faulty" 6 "NotUsed_3" ;
VAL_ 662 Third_Rear_Set_Temp 31 "HI" 30 "29_5" 29 "29_0" 28 "28_5" 27 "28_0" 26 "27_5" 25 "27_0" 24 "26_5" 23 "26_0" 22 "25_5" 21 "25_0" 20 "24_5" 19 "24_0" 18 "23_5" 17 "23_0" 16 "22_5" 15 "22_0" 14 "21_5" 13 "21_0" 12 "20_5" 11 "20_0" 10 "19_5" 9 "19_0" 8 "18_5" 7 "18_0" 6 "17_5" 5 "17_0" 4 "16_5" 3 "16_0" 2 "15_5" 1 "LO" 0 "No_Request" ;
VAL_ 662 Third_Rear_Blower_Speed 15 "NotUsed_6" 14 "NotUsed_5" 13 "NotUsed_4" 12 "NotUsed_3" 11 "NotUsed_2" 10 "Zero_Blower" 9 "Max_Blower" 8 "Min_Blower" 7 "Blower_Speed_7" 6 "Blower_Speed_6" 5 "Blower_Speed_5" 4 "Blower_Speed_4" 3 "Blower_Speed_3" 2 "Blower_Speed_2" 1 "Blower_Speed_1" 0 "No_Request" ;
VAL_ 662 Rear_Temp 15 "NotUsed_6" 14 "NotUsed_5" 13 "NotUsed_4" 12 "NotUsed_3" 11 "NotUsed_2" 10 "NotUsed_1" 9 "Max_Heating" 8 "Level_3_Heating" 7 "Level_2_Heating" 6 "Level_1_Heating" 5 "No_Heating_Cooling" 4 "Level_1_Cooling" 3 "Level_2_Cooling" 2 "Level_3_Cooling" 1 "Max_Cooling" 0 "No_Request" ;
VAL_ 662 Rear_Set_Temp 31 "HI" 30 "29_5" 29 "29_0" 28 "28_5" 27 "28_0" 26 "27_5" 25 "27_0" 24 "26_5" 23 "26_0" 22 "25_5" 21 "25_0" 20 "24_5" 19 "24_0" 18 "23_5" 17 "23_0" 16 "22_5" 15 "22_0" 14 "21_5" 13 "21_0" 12 "20_5" 11 "20_0" 10 "19_5" 9 "19_0" 8 "18_5" 7 "18_0" 6 "17_5" 5 "17_0" 4 "16_5" 3 "16_0" 2 "15_5" 1 "LO" 0 "No_Request" ;
VAL_ 662 Rear_Blower_Speed 15 "NotUsed_6" 14 "NotUsed_5" 13 "NotUsed_4" 12 "NotUsed_3" 11 "NotUsed_2" 10 "Zero_Blower" 9 "Max_Blower" 8 "Min_Blower" 7 "Blower_Speed_7" 6 "Blower_Speed_6" 5 "Blower_Speed_5" 4 "Blower_Speed_4" 3 "Blower_Speed_3" 2 "Blower_Speed_2" 1 "Blower_Speed_1" 0 "No_Request" ;
VAL_ 662 Running_Board_Cmd2 3 "Unused" 2 "Manually_Deployed" 1 "All_Enabled" 0 "All_Disabled" ;
VAL_ 513 BptRngeRsrvMet_B_Stat 1 "Yes" 0 "No" ;
VAL_ 513 BptPwOut_B_Dsply 1 "Yes" 0 "No" ;
VAL_ 513 BptStrtStop_D_Stat 3 "NotUsed_1" 2 "Start" 1 "Stop" 0 "NoRequest" ;
VAL_ 513 BptComm_D_RqHtrn 9 "EnergyTransferFault" 8 "EnergyTransferEnd" 7 "VehicleEnergyTransferActv" 6 "VehicleEnergyTransferReady" 5 "VehiclePreChargeReady" 4 "VehicleEnergyTransferWait" 3 "ConfirmConnection" 2 "VehicleReadyToToggle" 1 "AttemptDgtlCommunication" 0 "NoDigitalCommunication" 15 "NotUsed_6" 14 "NotUsed_5" 13 "NotUsed_4" 12 "NotUsed_3" 11 "NotUsed_2" 10 "NotUsed_1" ;
VAL_ 513 BptMde_D_Stat 7 "NotUsed_4" 6 "NotUsed_3" 5 "NotUsed_2" 4 "NotUsed_1" 3 "Automatic" 2 "Manual" 1 "Off" 0 "Null" ;
VAL_ 513 Bpt_D_StatHtrn 15 "Faulty" 14 "NotUsed_8" 13 "NotUsed_7" 12 "NotUsed_6" 11 "NotUsed_5" 10 "NotUsed_4" 9 "NotUsed_3" 8 "NotUsed_2" 7 "NotUsed_1" 6 "VehicleFault" 5 "EvseFault" 4 "BptActive" 3 "Precharge" 2 "BptReady" 1 "Initialization" 0 "NotReady" ;
VAL_ 513 BptSustn_B_Rq 1 "Active" 0 "Inactive" ;
VAL_ 513 GridSrvc01_B_Stat 1 "On" 0 "Off" ;
VAL_ 513 BattTracTeColr_D_Dsply 3 "NotUsed" 2 "ColorForSeverlyLimited" 1 "ColorForLimited" 0 "ColorForNormal" ;
VAL_ 513 MtrTracTeColr_D_Dsply 3 "NotUsed" 2 "ColorForSeverlyLimited" 1 "ColorForLimited" 0 "ColorForNormal" ;
VAL_ 148 VehYawWActl_D_Qf 3 "OK" 2 "Not_Within_Specifications" 1 "No_Data_Exists" 0 "Faulty" ;
VAL_ 148 VehRolWActl_D_Qf 3 "OK" 2 "Not_Within_Specifications" 1 "No_Data_Exists" 0 "Faulty" ;
VAL_ 148 VehYaw_W_Actl 65535 "Faulty" 65534 "NoDataExists" ;
VAL_ 148 VehRol_W_Actl 65535 "Faulty" 65534 "NoDataExists" ;
VAL_ 1042 VehRol_An_Dsply 127 "Faulty" 126 "NoDataExists" ;
VAL_ 1042 RearDiffLck_Tq_RqMn 4095 "Faulty" ;
VAL_ 1042 VehPtch_An_Dsply 127 "Faulty" 126 "NoDataExists" ;
VAL_ 828 DrvSpotLight_B_Rq 1 "Yes" 0 "No" ;
VAL_ 828 SpotLghtRight_D_Stat 1 "On" 0 "Off" ;
VAL_ 828 RearPassWindowPos 7 "Unused2" 6 "Unused1" 5 "Fully_Open" 4 "Bet60Percent_FullyOpen" 3 "Bet10Percent_60Percent" 2 "BetFully_10PercentOpen" 1 "Fully_Closed" 0 "Undefined" ;
VAL_ 828 PassWindowPosition 7 "Unused2" 6 "Unused1" 5 "Fully_Open" 4 "Bet60Percent_FullyOpen" 3 "Bet10Percent_60Percent" 2 "BetFully_10PercentOpen" 1 "Fully_Closed" 0 "Undefined" ;
VAL_ 828 SpotLghtLeft_D_Stat 1 "On" 0 "Off" ;
VAL_ 330 TrnFaltOpenClu_B_Stat 1 "MayOpenClutch" 0 "Normal" ;
VAL_ 330 TrnAout_W_ActlUnfilt 32767 "Fault" 32766 "Unknown" ;
VAL_ 512 PtDrvMde_D_Stat 15 "Faulty" 14 "NotUsed11" 13 "NotUsed10" 12 "NotUsed9" 11 "NotUsed8" 10 "NotUsed7" 9 "NotUsed6" 8 "Track" 7 "Drag" 6 "Rock" 5 "Baja" 4 "Sand" 3 "TowHaulGradeAssist" 2 "SnowWet" 1 "Sport" 0 "Normal" ;
VAL_ 862 TwHlGrdAsst_B_RqTrn 1 "On" 0 "Off" ;
VAL_ 862 ApaSwtch_D_RqDrv 3 "NotUsed2" 2 "NotUsed1" 1 "Pressed" 0 "Not_Pressed" ;
VAL_ 862 HvacBlwrFront_D_Stat 31 "Not_Used" 20 "Full_On" 19 "95_Percent" 18 "90_Percent" 17 "85_Percent" 16 "80_Percent" 15 "75_Percent" 14 "70_Percent" 13 "65_Percent" 12 "60_Percent" 11 "55_Percent" 10 "50_Percent" 9 "45_Percent" 8 "40_Percent" 7 "35_Percent" 6 "30_Percent" 5 "25_Percent" 4 "20_Percent" 3 "15_Percent" 2 "10_Percent" 1 "5_Percent" 0 "Off" ;
VAL_ 862 HvacBlwrRear_D_Stat 31 "Not_Used" 20 "Full_On" 19 "95_Percent" 18 "90_Percent" 17 "85_Percent" 16 "80_Percent" 15 "75_Percent" 14 "70_Percent" 13 "65_Percent" 12 "60_Percent" 11 "55_Percent" 10 "50_Percent" 9 "45_Percent" 8 "40_Percent" 7 "35_Percent" 6 "30_Percent" 5 "25_Percent" 4 "20_Percent" 3 "15_Percent" 2 "10_Percent" 1 "5_Percent" 0 "Off" ;
VAL_ 862 EcoMde_D_RqDrv 3 "Faulty" 2 "On" 1 "Off" 0 "Null" ;
VAL_ 862 ClimtThrmlLoad_No_Actl 255 "Fault" ;
VAL_ 862 CamraDefog_B_Actl 1 "On" 0 "Off" ;
VAL_ 862 CabnAmb_Te_Actl 255 "Fault" ;
VAL_ 862 AutoStpHvacDelta_I_Est 255 "Fault" ;
VAL_ 831 PassMirrorCmd 7 "Unused" 6 "Unfold" 5 "Fold" 4 "Right" 3 "Left" 2 "Down" 1 "Up" 0 "Idle" ;
VAL_ 831 DipMirrorPosPassenger 1 "Dipped" 0 "Off" ;
VAL_ 831 MirrorTelescopic_D_Rq 3 "NotUsed" 2 "Retract" 1 "Extend" 0 "Null" ;
VAL_ 831 RearPassWindowLockCmd 1 "Enable" 0 "Disable" ;
VAL_ 831 RearPassWindowCmd 7 "Unused2" 6 "Unused1" 5 "NotDefined" 4 "Audo_Down" 3 "Manual_Down" 2 "Auto_Up" 1 "Manual_Up" 0 "Idle" ;
VAL_ 831 PassWindowCmd 7 "Unused2" 6 "Unused1" 5 "NotDefined" 4 "Audo_Down" 3 "Manual_Down" 2 "Auto_Up" 1 "Manual_Up" 0 "Idle" ;
VAL_ 831 ActiveStoragePassenger 7 "Unused3" 6 "Unused2" 5 "Unused1" 4 "StoreDipMemoryButton4" 3 "StoreDipMemoryButton3" 2 "StoreDipMemoryButton2" 1 "StoreDipMemoryButton1" 0 "Off" ;
VAL_ 831 RearDriverWindowPos 7 "Unused2" 6 "Unused1" 5 "Fully_Open" 4 "Bet60Percent_FullyOpen" 3 "Bet10Percent_60Percent" 2 "BetFully_10PercentOpen" 1 "Fully_Closed" 0 "Undefined" ;
VAL_ 831 DriverWindowPosition 7 "Unused2" 6 "Unused1" 5 "Fully_Open" 4 "Bet60Percent_FullyOpen" 3 "Bet10Percent_60Percent" 2 "BetFully_10PercentOpen" 1 "Fully_Closed" 0 "Undefined" ;
VAL_ 331 TrnAout2_W_ActlUnfilt 65535 "Fault" 65534 "NoDataExists" ;
VAL_ 331 CmbbEngTqMn_B_ActlHtrn 1 "Active" 0 "Inactive" ;
VAL_ 331 CmbbDeny_B_ActlHtrn 1 "Yes" 0 "No" ;
VAL_ 965 TrnkFrontPrim_B_Falt 1 "Fault" 0 "NoFault" ;
VAL_ 965 TrnkFrontEmgcy_D_Stat 3 "NotDetermined" 2 "SwitchState2" 1 "SwitchState1" 0 "NotPressed" ;
VAL_ 965 PtWakeupActv4_B_Rq 1 "On" 0 "Off" ;
VAL_ 965 TrunkFrontOpen_D_Stat 3 "NotUsed" 2 "NotRestricted" 1 "Restricted" 0 "Null" ;
VAL_ 1242 EngExhMdeQuietCstm_D_Rq 7 "Faulty" 6 "NotUsed_2" 5 "NotUsed_1" 4 "Track" 3 "Sport" 2 "Normal" 1 "Stealth" 0 "Null" ;
VAL_ 1242 StopStrtCstm_D_Rq 3 "Faulty" 2 "On" 1 "Off" 0 "NotAvailable" ;
VAL_ 1242 SelDrvMdeCstmPt_D_Rq 31 "Faulty" 30 "NotUsed15" 29 "NotUsed14" 28 "NotUsed13" 27 "NotUsed12" 26 "NotUsed11" 25 "NotUsed10" 24 "NotUsed9" 23 "NotUsed8" 22 "NotUsed7" 21 "CustomMode" 20 "TrackMode" 19 "OnePedalDrive" 18 "EvLaterChargerMode" 17 "EvNowMode" 16 "DragMode" 15 "HighSpeedDesertMode_Baja" 14 "SportAdaptiveMode" 13 "NotAvailable_13" 12 "NotAvailable_12" 11 "NotAvailable_11" 10 "NotAvailable_10" 9 "RockCrawlMode" 8 "MudRutsMode" 7 "SandMode" 6 "EconomyMode" 5 "GrassGravelSnow" 4 "NotAvailable_04" 3 "TowHaulMode" 2 "NotAvailable_02" 1 "SportMode" 0 "NormalMode" ;
VAL_ 1245 RearDiffLckLamp_D_Cstm 3 "Not_Used" 2 "Flash" 1 "On" 0 "Off" ;
VAL_ 1245 FrontDiffLckLamp_D_Cstm 3 "Fast_Flash" 2 "Slow_Flash" 1 "On" 0 "Off" ;
VAL_ 1245 AwdMdeCstm_D_RqDrv 7 "Faulty" 6 "NotUsed_3" 5 "NotUsed_2" 4 "NotUsed_1" 3 "FourByFourLow" 2 "FourByFourHigh" 1 "FourByFourAuto" 0 "FourByTwo" ;
VAL_ 1245 SelDrvMdeAwd2_D_Cstm 31 "Faulty" 30 "NotUsed_17" 29 "NotUsed_16" 28 "NotUsed_15" 27 "NotUsed_14" 26 "NotUsed_13" 25 "NotUsed_12" 24 "NotUsed_11" 23 "NotUsed_10" 22 "NotUsed_9" 21 "NotUsed_8" 20 "CustomMode" 19 "OnePedalDrive" 18 "DragMode" 17 "EvLaterChargeMode" 16 "EvNowMode" 15 "TrackMode" 14 "RoughRoadMode" 13 "NotAvailable" 12 "HighSpeedDesertMode_Baja" 11 "SportAdaptiveMode" 10 "RockCrawlMode" 9 "MudRutsMode" 8 "SandMode" 7 "EconomyMode" 6 "GrassGravelSnow" 5 "TowHaulMode" 4 "SportMode" 3 "Normal_4L" 2 "Normal_4A" 1 "Normal_2H" 0 "NormalMode" ;
VAL_ 781 TrlrTireDual_D_Stat 15 "NotUsed_11" 14 "NotUsed_10" 13 "NotUsed_9" 12 "NotUsed_8" 11 "NotUsed_7" 10 "NotUsed_6" 9 "NotUsed_5" 8 "NotUsed_4" 7 "NotUsed_3" 6 "NotUsed_2" 5 "NotUsed_1" 4 "NotSupported" 3 "Invalid" 2 "InnerTire" 1 "OuterTire" 0 "SystemUnknown" ;
VAL_ 781 TrlrTireSys_D_Stat 15 "NotUsed" 14 "TiresNotTrained" 13 "TrainingComplete" 12 "TrainLMTire" 11 "TrainLRTire" 10 "TrainRMTire" 9 "TrainRRTire" 8 "TrainRFTire" 7 "TrainLFTire" 6 "RequestPressureThresh" 5 "RequestTireCount" 4 "SystemActive" 3 "TireLow" 2 "SensorFault" 1 "System Fault" 0 "SystemUnknown" ;
VAL_ 781 TrlrTireCnt_D_Stat 7 "Faulty" 6 "TwelveTire" 5 "EightTire" 4 "FourTireOneAxle" 3 "SixTire" 2 "FourTire" 1 "TwoTire" 0 "Unconfigured" ;
VAL_ 781 Chirp_D_RqTrlr 3 "NotUsed" 2 "Chirp_2" 1 "Chirp_1" 0 "NoRequest" ;
VAL_ 1022 TrlrTireTSensIRM_D_Stat 3 "Faulty" 2 "HighTempWarning" 1 "Normal" 0 "NotAvailable" ;
VAL_ 1022 TrlrTireTSensIRF_D_Stat 3 "Faulty" 2 "HighTempWarning" 1 "Normal" 0 "NotAvailable" ;
VAL_ 1022 TrlrTireIRR_T_Actl 255 "NotSupported" 254 "Invalid" ;
VAL_ 1022 TrlrTireIRM_T_Actl 255 "NotSupported" 254 "Invalid" ;
VAL_ 1022 TrlrTireILR_T_Actl 255 "NotSupported" 254 "Invalid" ;
VAL_ 1022 TrlrTireILM_T_Actl 255 "NotSupported" 254 "Invalid" ;
VAL_ 1022 TrlrTireILF_T_Actl 255 "NotSupported" 254 "Invalid" ;
VAL_ 1022 TrlrTireIRF_T_Actl 255 "NotSupported" 254 "Invalid" ;
VAL_ 1022 TrlrTireTSensIRR_D_Stat 3 "Faulty" 2 "HighTempWarning" 1 "Normal" 0 "NotAvailable" ;
VAL_ 1022 TrlrTireTSensILR_D_Stat 3 "Faulty" 2 "HighTempWarning" 1 "Normal" 0 "NotAvailable" ;
VAL_ 1022 TrlrTireTSensILM_D_Stat 3 "Faulty" 2 "HighTempWarning" 1 "Normal" 0 "NotAvailable" ;
VAL_ 1022 TrlrTireTSensILF_D_Stat 3 "Faulty" 2 "HighTempWarning" 1 "Normal" 0 "NotAvailable" ;
VAL_ 903 AprSnd_D_Rq 63 "NotUsed_24" 62 "NotUsed_23" 61 "NotUsed_22" 60 "NotUsed_21" 59 "NotUsed_20" 58 "NotUsed_19" 57 "NotUsed_18" 56 "NotUsed_17" 55 "NotUsed_16" 54 "NotUsed_15" 53 "NotUsed_14" 52 "NotUsed_13" 51 "NotUsed_12" 50 "NotUsed_11" 49 "NotUsed_10" 48 "NotUsed_9" 47 "NotUsed_8" 46 "NotUsed_7" 45 "NotUsed_6" 44 "NotUsed_5" 43 "NotUsed_4" 42 "NotUsed_3" 41 "NotUsed_2" 40 "ROpenDoor" 39 "MgMercOpenDoor" 38 "MgRecAuthFail_Max" 37 "RCustCareCalling" 36 "MgRecCustCareCalling" 35 "RCallCustCare" 34 "MgRecCallCustCare" 33 "RItemDetection" 32 "MgRecItemDetection" 31 "MgMercItemDetection" 30 "MgRecOpenDoor" 29 "MgMercLoadOrder" 28 "MgRecBarcodeError" 27 "MgRecBarcode" 26 "RAuthFailMax" 25 "MgMercAuthFailMax" 24 "RAuthFail" 23 "MgMercAuthFail" 22 "R_6ft" 21 "MgRec_6ft" 20 "RAuthSucc" 19 "MgRecAuthSucc" 18 "MgMercAuthSucc" 17 "RMaxTime" 16 "MgRecMaxTime" 15 "MgMercMaxTime" 14 "RExtendTimeUnloading" 13 "RExtendTimeLoading" 12 "MgReciExtendTime" 11 "MgMercExtendTime" 10 "RTimeOutLoading" 9 "RTimeOutUnloading" 8 "MgMercTimeOut" 7 "MgRecTimeOut" 6 "RBttnPressKeypad" 5 "MgRecBttnPressKeypad" 4 "MgMercBttnPressKeypad" 3 "MgMercBttnPressOrder" 2 "RNudge" 1 "MgMercNudge" 0 "NoSound" ;
VAL_ 901 AplSnd_D_Rq 63 "NotUsed_24" 62 "NotUsed_23" 61 "NotUsed_22" 60 "NotUsed_21" 59 "NotUsed_20" 58 "NotUsed_19" 57 "NotUsed_18" 56 "NotUsed_17" 55 "NotUsed_16" 54 "NotUsed_15" 53 "NotUsed_14" 52 "NotUsed_13" 51 "NotUsed_12" 50 "NotUsed_11" 49 "NotUsed_10" 48 "NotUsed_9" 47 "NotUsed_8" 46 "NotUsed_7" 45 "NotUsed_6" 44 "NotUsed_5" 43 "NotUsed_4" 42 "NotUsed_3" 41 "NotUsed_2" 40 "ROpenDoor" 39 "MgMercOpenDoor" 38 "MgRecAuthFail_Max" 37 "RCustCareCalling" 36 "MgRecCustCareCalling" 35 "RCallCustCare" 34 "MgRecCallCustCare" 33 "RItemDetection" 32 "MgRecItemDetection" 31 "MgMercItemDetection" 30 "MgRecOpenDoor" 29 "MgMercLoadOrder" 28 "MgRecBarcodeError" 27 "MgRecBarcode" 26 "RAuthFailMax" 25 "MgMercAuthFailMax" 24 "RAuthFail" 23 "MgMercAuthFail" 22 "R_6ft" 21 "MgRec_6ft" 20 "RAuthSucc" 19 "MgRecAuthSucc" 18 "MgMercAuthSucc" 17 "RMaxTime" 16 "MgRecMaxTime" 15 "MgMercMaxTime" 14 "RExtendTimeUnloading" 13 "RExtendTimeLoading" 12 "MgReciExtendTime" 11 "MgMercExtendTime" 10 "RTimeOutLoading" 9 "RTimeOutUnloading" 8 "MgMercTimeOut" 7 "MgRecTimeOut" 6 "RBttnPressKeypad" 5 "MgRecBttnPressKeypad" 4 "MgMercBttnPressKeypad" 3 "MgMercBttnPressOrder" 2 "RNudge" 1 "MgMercNudge" 0 "NoSound" ;
VAL_ 1112 BattTracIsoDis_B_Stat 1 "Yes" 0 "No" ;
VAL_ 1112 BattTrac2_E_Max 4095 "Faulty" 4094 "NoDataExists" ;
VAL_ 1112 BattTracHeat_D_Rq 3 "Faulty" 2 "NotUsed" 1 "On" 0 "Off" ;
VAL_ 1112 BattTracDcFstSustn_B_Rq 1 "Active" 0 "Inactive" ;
VAL_ 1112 BattDcCnnct_D_Cmd 7 "NotUsed_3" 6 "NotUsed_2" 5 "NotUsed_1" 4 "WeldCheck" 3 "OkToDischarge" 2 "Closed" 1 "Precharge" 0 "Open" ;
VAL_ 1112 BattTrac2_E_Avail 4095 "Faulty" 4094 "NoDataExists" ;
VAL_ 1112 BattTracCnnct_D_Cmd 7 "NotUsed_3" 6 "NotUsed_2" 5 "NotUsed_1" 4 "WeldCheck" 3 "OkToDischarge" 2 "Closed" 1 "Precharge" 0 "Open" ;
VAL_ 1112 BattTracHvilOpen_B_Stat 1 "Open" 0 "Closed" ;
VAL_ 1112 BattTracCoolLvl_D_Rq 7 "Faulty" 6 "NotUsed" 5 "ChillerCoolingBattFirst" 4 "ChillerCoolingCabinFirst" 3 "ForcedCoolingRadiator" 2 "OpportunisticCoolingRad" 1 "CoolantFlowBypassLine" 0 "Off" ;
VAL_ 1112 BattTracTeSustn_B_Rq 1 "Active" 0 "Inactive" ;
VAL_ 1112 BattTracTeEvnt_B_Stat 1 "Active" 0 "Inactive" ;
VAL_ 1112 BattTracDcdcDis_B_Rq 1 "Yes" 0 "No" ;
VAL_ 1112 BattChrgTrgtEvnt_B_Stat 1 "Active" 0 "Inactive" ;
VAL_ 1112 BattTracDiagClr_B_Rq 1 "On" 0 "Off" ;
VAL_ 1112 BattTracChrgSustn_B_Rq 1 "Active" 0 "Inactive" ;
VAL_ 1112 HtrnClntPump_D_Stat 3 "Faulty" 2 "No_Data_Exists" 1 "On" 0 "Off" ;
VAL_ 1112 BattTracDelta_Te_Actl 255 "Faulty" 254 "NoDataExists" ;
VAL_ 1112 BattTracClntPmp_D_Stat 3 "Faulty" 2 "No_Data_Exists" 1 "On" 0 "Off" ;
VAL_ 1112 BattTracHazrd_D_Stat 3 "Disabled" 2 "HazardConfirmed" 1 "ExternalMonitoringRequired" 0 "NoHazardDetected" ;
VAL_ 977 CnvtTopTrgt_D_Rq 7 "NotUsed4" 6 "NotUsed3" 5 "NotUsed2" 4 "NotUsed1" 3 "OpenTarget" 2 "OpenPosition" 1 "ClosePosition" 0 "CloseTarget" ;
VAL_ 977 CnvtTopSleepActv_B_Rq 1 "Active" 0 "Inactive" ;
VAL_ 977 CnvtTopPar_D_Rq 7 "NotUsed" 6 "ForceIncrease3" 5 "ForceIncrease2" 4 "ForceIncrease1" 3 "NoAdapt" 2 "Teach" 1 "NoPwmNoAp" 0 "Normal" ;
VAL_ 977 CnvtTopBrkActv_B_Rq 1 "Active" 0 "Inactive" ;
VAL_ 977 CnvtTop_D_Rq 7 "NotUsed" 6 "ResetErrorFlags" 5 "DiscardNormalization" 4 "SetNormalization" 3 "DirectDriveClose" 2 "DirectDriveOpen" 1 "DirectPosition" 0 "Stop" ;
VAL_ 977 CnvtTopPos_Up_Stat 1 "Up" 0 "Not_Up" ;
VAL_ 977 CnvtTopMsgTxt_D_Rq 3 "NotSecure" 2 "NotAvailable" 1 "RemoveCaps" 0 "NoWarning" ;
VAL_ 977 WndwCnvtTopDrop_B_Cmd 1 "Yes" 0 "No" ;
VAL_ 977 CnvtTopPos_Dn_Stat 1 "Down" 0 "Not_Down" ;
VAL_ 530 StationTypeSel_D_Rq 0 "Inactive" 1 "PI_Code" 2 "SCIDI_SID_ECC" 3 "NotUsed_1" ;
VAL_ 746 Con_BTAud_Shuffle_St 3 "OnTheFolderSelGroup" 2 "OnTheDevice" 1 "Off" 0 "Invalid" ;
VAL_ 746 Con_BTAud_Repeat_St 7 "Reserved3" 6 "Reserved2" 5 "Reserved1" 4 "RepeatOnDevice" 3 "RepeatOnFolder" 2 "RepeatOnTrack" 1 "Off" 0 "Invalid" ;
VAL_ 746 Con_BTAud_IntroScan_St 3 "OnTheFolderSelGroup" 2 "OnTheDevice" 1 "Off" 0 "Invalid" ;
VAL_ 746 Con_BTAud_Error_St 8 "NoDataInFolder" 7 "NoRespFromDevice" 6 "UnableToRead" 5 "NoDataOnDevice" 4 "FileSysNotSupported" 3 "DeviceNotSupported" 2 "InvalidFile" 1 "NoError" 0 "Invalid" ;
VAL_ 746 Con_BTAud_FunctStats_St 7 "Reserved2" 6 "Reserved1" 5 "Reserved" 4 "Reading" 3 "Ready" 2 "Initilization" 1 "Free" 0 "Invalid" ;
VAL_ 746 Con_BTAud_OpMode_St 7 "FastRewind20" 6 "FastRewind10" 5 "FastForward20" 4 "FastForward10" 3 "Pause" 2 "Play" 1 "Stop" 0 "Invalid" ;
VAL_ 479 DISP_SetVol_Source_Rq 5 "SetAudioVolume" 4 "SetVRvolume" 3 "SetPhoneVolume" 2 "SetPromptVolume" 1 "SetTAVolume" 0 "Inactive" ;
VAL_ 479 DISP_Setshaker_Rq 2 "On" 1 "Off" 0 "Inactive" ;
VAL_ 474 Nav_SetCurrStatMCCh_Rq 7 "MCChannel7" 6 "MCChannel6" 5 "MCChannel5" 4 "MCChannel4" 3 "MCChannel3" 2 "MCChannel2" 1 "MCChannel1" 0 "Inactive" ;
VAL_ 474 NAV_SetNEWSMode_Rq 0 "Inactive" 1 "NewsOn" 2 "NewsOff" ;
VAL_ 474 NAV_SetDSP_Rq 9 "Convertible" 8 "RearSeats" 7 "FrontSeats" 6 "Reserved3" 5 "Reserved2" 4 "Reserved1" 15 "Reserved" 0 "Inactive" 1 "All" 2 "Driver" 3 "Passenger" ;
VAL_ 474 NAV_SetCurrentStatOp_Rq 0 "Inactive" 1 "SetCurrentFrequency" 2 "SetCurrentPiCode" 3 "SetCurrentStation" ;
VAL_ 474 NAV_ARReqstrSystem_Rq 0 "FrontRequester" 1 "RearRequester" ;
VAL_ 474 NAV_ARReqstrPriority_Rq 0 "EmergencyServ" 1 "TelService" 2 "AutoAnswer" 3 "Ta" 4 "PttMutevoice" 5 "NavUserVoiceCmd" 6 "NavSysVoiceCmd" 7 "Radio" 8 "Disc" 9 "Alarm" 10 "Ptynews" 11 "Aux_ExtSource" 12 "BT_BTNavAndTelMute" 13 "ManualAudioMute" 14 "NotReq" ;
VAL_ 474 NAV_AROperationType_Rq 0 "Inactive" 1 "Requestaudioresource" 2 "Releaseaudioresource" 3 "Releaseallaudioresouces" 4 "Getresourceupdate" 5 "Getallresourceupdates" ;
VAL_ 474 NAV_ARAudioSource_Rq 15 "iPod" 14 "USB" 13 "BTAudio" 0 "AmfmRadio" 1 "FrontDisc" 2 "SDARS_DAB" 3 "InDashCdChanger" 4 "VoiceRecogniser" 5 "TelematicUnit" 6 "BluetoothPhone" 7 "RearDisc" 8 "APIM" 9 "FrontAuxInput" 10 "Navigation" 11 "RearAux" 12 "NotReq" ;
VAL_ 477 NAV_LoadEjectMode_Rq 0 "Inactive" 1 "Load" 2 "Eject" 3 "EndloadMode" ;
VAL_ 477 NAV_LoadEjectDisc_Rq 0 "Inactive" 1 "Disc1" 2 "Disc2" 3 "Disc3" 4 "Disc4" 5 "Disc5" 6 "Disc6" 7 "All" ;
VAL_ 260 MFD_SDARS_SetOpMode_Rq 7 "FastRewindSpeed2" 6 "FastRewindSpeed1" 5 "FastForwardSpeed2" 4 "FastForwardSpeed1" 3 "Pause" 2 "Play" 1 "Stop" 0 "Invalid" ;
VAL_ 260 SDARS_GetESN_Rq 1 "RequestESN" 0 "Invalid" ;
VAL_ 260 SDARS_SRReplay_Rq 2 "Disable" 1 "Enable" 0 "Inactive" ;
VAL_ 260 SDARS_FactoryReset_Rq 1 "ResetFactoryDefaults" 0 "Invalid" ;
VAL_ 476 Nav_SetAudioMixRatio_Rq 31 "Inactive" ;
VAL_ 476 NAV_SkipCatalouge_Rq 0 "Inactive" 1 "NextCatalouge" 2 "PerviousCatalouge" ;
VAL_ 476 NAV_SetOperationMode_Rq 7 "FastRewind20" 6 "FastRewind10" 5 "FastForward20" 4 "FastForward10" 3 "Pause" 2 "Play" 1 "Stop" 0 "Inactive" ;
VAL_ 476 NAV_SetDSPProgram_Rq 7 "Reserved2" 6 "Reserved1" 5 "Voice" 4 "Rock" 0 "Inactive" 1 "Normal" 2 "Pop" 3 "Classical" ;
VAL_ 490 HMI_SetCompression_Rq 0 "Inactive" 1 "Off" 2 "On" 3 "NotUsed" ;
VAL_ 490 HMI_SkipTrack_Rq 3 "NotUsed" 2 "Decrement" 1 "Increment" 0 "Inactive" ;
VAL_ 896 BptDly_T_Actl 63 "Faulty" 62 "NoDataExists" ;
VAL_ 896 VehElAvgTrip1_Eff_Dsply 127 "Faulty" 126 "NoDataExists" ;
VAL_ 896 Trip1SumDrvE_Pc_Dsply 1023 "Faulty" 1022 "NoDataExists" ;
VAL_ 896 Trip1ExtFctrE_Pc_Dsply 1023 "Faulty" 1022 "NoDataExists" ;
VAL_ 896 Trip1ClimE_Pc_Dsply 1023 "Faulty" 1022 "NoDataExists" ;
VAL_ 896 Trip1BattULoE_Pc_Dsply 1023 "Faulty" 1022 "NoDataExists" ;
VAL_ 897 VehElAvgTrip2_Eff_Dsply 127 "Faulty" 126 "NoDataExists" ;
VAL_ 897 Trip2SumDrvE_Pc_Dsply 1023 "Faulty" 1022 "NoDataExists" ;
VAL_ 897 Trip2ExtFctrE_Pc_Dsply 1023 "Faulty" 1022 "NoDataExists" ;
VAL_ 897 Trip2ClimE_Pc_Dsply 1023 "Faulty" 1022 "NoDataExists" ;
VAL_ 897 Trip2BattULoE_Pc_Dsply 1023 "Faulty" 1022 "NoDataExists" ;
VAL_ 502 Dsp_FolderContent_Rq 2 "Inactive" 1 "RequestContentFromParentF" 0 "RequestContentFromParamet" ;
VAL_ 502 Dsp_CutItem2_Rq 3 "Inactive" 2 "ThreeQuarterFromTheBeginn" 1 "End" 0 "Beginning" ;
VAL_ 502 Dsp_AudioSourceSel2_Rq 4 "Reserved" 3 "USB" 2 "BTAudio" 1 "CD" 0 "Inactive" ;
VAL_ 955 Tire_Temp_RF_Data 255 "NotSupported" 254 "Invalid" ;
VAL_ 955 Tire_Temp_ORR_Data 255 "NotSupported" 254 "Invalid" ;
VAL_ 955 Tire_Temp_OLR_Data 255 "NotSupported" 254 "Invalid" ;
VAL_ 955 Tire_Temp_LF_Data 255 "NotSupported" 254 "Invalid" ;
VAL_ 955 Tire_Temp_IRR_Data 255 "NotSupported" 254 "Invalid" ;
VAL_ 955 Tire_Temp_ILR_Data 255 "NotSupported" 254 "Invalid" ;
VAL_ 1116 TrlrAidSetup_D2_Rq 15 "NotUsed_9" 14 "NotUsed_8" 13 "NotUsed_7" 12 "NotUsed_6" 11 "NotUsed_5" 10 "NotUsed_4" 9 "NotUsed_3" 8 "NotUsed_2" 7 "NotUsed_1" 6 "CompleteSetup" 5 "ReturnToSetup" 4 "StickerNotCircled" 3 "ConfirmSetup" 2 "EndSetup" 1 "BeginSetup" 0 "Inactive" ;
VAL_ 1116 TrlrAidEnbl_D2_Rq 7 "NotUsed_4" 6 "NotUsed_3" 5 "NotUsed_2" 4 "NotUsed_1" 3 "Deactivate" 2 "ActivateTrg" 1 "ActivateTba" 0 "Inactive" ;
VAL_ 1116 TlightTest_D_Mnu 3 "TestEndAcknowledge" 2 "StartTest" 1 "StopTest" 0 "Null" ;
VAL_ 1116 TrlrRvrseCancl_B_Rq 1 "Cancel" 0 "Null" ;
VAL_ 1116 TrlrIdType_D_Stat 3 "Gooseneck" 2 "FifthWheel" 1 "Conventional" 0 "Null" ;
VAL_ 1116 TrlrAnOffstDir_D_Mem 3 "NotUSed" 2 "Right" 1 "Left_or_Center" 0 "Null" ;
VAL_ 608 EvseDcChrgIso_D_Stat 7 "Faulty" 6 "NoDataExists" 5 "NotUsed_3" 4 "NotUsed_2" 3 "NotUsed_1" 2 "Valid" 1 "Warning" 0 "Invalid" ;
VAL_ 608 DcChrgSrvcRqd_B_Rq 1 "On" 0 "Off" ;
VAL_ 608 DcChrgWarnLamp_B_Rq 1 "On" 0 "Off" ;
VAL_ 608 EvseChrgIso_D_Stat 3 "Faulty" 2 "Warning" 1 "Valid" 0 "Invalid" ;
VAL_ 608 DgtlCommGtwy_D_Falt 127 "NotUsed_63" 65 "NotUsed_1" 64 "EvseGbtCommTimeout" 63 "EvseGbtCrgVoltMismatch" 62 "EvseGbtChrgCurrntMismatch" 61 "EvseGbtOtherFalt" 60 "EvseGbtEmergShutdown" 59 "EvseGbtEnergyTransFalt" 58 "EvseGbtIntOverTemp" 57 "EvseGbtConnectorFalt" 56 "EvseGbtOverTemp" 55 "EvseResCpsRootCaCertRev" 54 "EvseResSubCA2CertRev" 53 "EvseResSubCA1CertRev" 52 "EvseResCpsProvCertRev" 51 "EvseResRootCaCertRev" 50 "EvseResMoSubCa2CertRev" 49 "EvseResMoSubCa1CertRev" 48 "EvseResMoProvCertRev" 47 "EvseResOemSubCa2CertRev" 46 "EvseResOemSubCa1CertRev" 45 "EvseResOemProvCertRev" 44 "EvseResMoUnknown" 43 "EvseResContractNotAccept" 42 "EvseResNoSuppAppProt" 41 "EvseResCertNotAllowed" 40 "EvseResContractErr" 39 "EvseResNoChrgSvcSelect" 38 "EvseResMeterSignNotVld" 37 "EvseResPwrDelNotApplied" 36 "EvseResTrfSelectInvld" 35 "EvseResChrgProfileInvld" 34 "EvseResWrongChrgParam" 33 "EvseResWrongEnrgyTransMde" 32 "EvseResChlgInvld" 31 "EvseResContractCancel" 30 "EvseResCertChainErr" 29 "EvseResNoCertAvail" 28 "EvseResCertRvk" 27 "EvseResCertExp" 26 "EvseResPymtSelectInvld" 25 "EvseResSvcldInvld" 24 "EvseResUnknownSession" 23 "EvseResSignErr" 22 "EvseResSeqErr" 21 "EvseResFailed" 20 "EvsePreChrgTimeout" 19 "EvseCableCheckTimeout" 18 "EvseCommSetupTimeout" 17 "EvseMsgTimeout" 16 "EvseTlsUnknownCA" 15 "EvseTlsCertExpired" 14 "EvseTlsBadCert" 13 "EvseTlsHandshakeFail" 12 "EvseTlsDecryptFail" 11 "EvseTlsBadRecordMac" 10 "EvseTlsUnexpectedMsg" 9 "EvseTlsFail" 8 "EvseTcpCnnctFail" 7 "EvseUpdErr" 6 "EvseSlaacErr" 5 "EvseStopNotification" 4 "EvseMalfunction" 3 "EvseEmergShutdown" 2 "EvseStatUtilityIntrpt" 1 "EvseStatShutdown" 0 "NoFault" ;
VAL_ 608 EvseChrg2_Pw_Mx 32767 "Faulty" 32766 "NoDataExists" ;
VAL_ 608 DcChrgRdy_D_Stat 15 "Faulty" 14 "NotUsed_4" 13 "NotUsed_3" 12 "NotUsed_2" 11 "CableCheck" 10 "EvseFault" 9 "EvseNotCompatible" 8 "EvsePaused" 7 "GbtPrecharge" 6 "ChargeComplete" 5 "Charging" 4 "Precharge" 3 "WeldCheck" 2 "ChargeReady" 1 "Initialization" 0 "NotReady" ;
VAL_ 608 DgtlCommGtwyMde_D_Stat 11 "NotUsed_3" 10 "DgtlCommFailed" 9 "DgtlCommEstablished" 8 "Inactive" 7 "RestartRequest" 6 "AcPnc_Eim" 5 "AcPnc" 4 "AcEim" 3 "DcPnc_Eim" 2 "DcPnc" 1 "DcEim" 0 "NotDetected" 15 "NotUsed_7" 14 "NotUsed_6" 13 "NotUsed_5" 12 "NotUsed_4" ;
VAL_ 608 DgtlCommPnc_D_Stat 7 "Faulty" 6 "NotUsed_3" 5 "NotUsed_2" 4 "NotUsed_1" 3 "Enable" 2 "Disable" 1 "NoContractsInstalled" 0 "Null" ;
VAL_ 608 BattTracIsoDis_B_Rq 1 "Yes" 0 "No" ;
VAL_ 838 FohStrtDay_T_Rq 7 "Sunday" 6 "Saturday" 5 "Friday" 4 "Thursday" 3 "Wednesday" 2 "Tuesday" 1 "Monday" 0 "NotUsed" ;
VAL_ 838 FohStop_B_Rq 3 "Unknown" 2 "NotUsed" 1 "Enable" 0 "Disable" ;
VAL_ 838 FohTAllEnable_B_Rq 3 "Unknown" 2 "NotUsed" 1 "Enable" 0 "Disable" ;
VAL_ 838 FohT2Enable_B_Rq 1 "Enable" 0 "Disable" ;
VAL_ 838 FohT1Enable_B_Rq 1 "Enable" 0 "Disable" ;
VAL_ 838 FohStrtEnable_B_Rq 1 "Enable" 0 "Disable" ;
VAL_ 838 FohContOn_B_Rq 3 "Unknown" 2 "NotUsed" 1 "Enable" 0 "Disable" ;
VAL_ 1255 BalrRight4Threat_D_Stat 1 "Yes" 0 "No" ;
VAL_ 1255 BalrRight4Fast_B_Stat 1 "Yes" 0 "No" ;
VAL_ 1255 BalrRight4Dsply_B_Stat 1 "Yes" 0 "No" ;
VAL_ 1254 BalrRight3Threat_D_Stat 1 "Yes" 0 "No" ;
VAL_ 1254 BalrRight3Fast_B_Stat 1 "Yes" 0 "No" ;
VAL_ 1254 BalrRight3Dsply_B_Stat 1 "Yes" 0 "No" ;
VAL_ 1253 BalrRight2Threat_D_Stat 1 "Yes" 0 "No" ;
VAL_ 1253 BalrRight2Fast_B_Stat 1 "Yes" 0 "No" ;
VAL_ 1253 BalrRight2Dsply_B_Stat 1 "Yes" 0 "No" ;
VAL_ 1252 BalrRight1Threat_D_Stat 1 "Yes" 0 "No" ;
VAL_ 1252 BalrRight1Fast_B_Stat 1 "Yes" 0 "No" ;
VAL_ 1252 BalrRight1Dsply_B_Stat 1 "Yes" 0 "No" ;
VAL_ 1251 BalrLeft4Threat_D_Stat 1 "Yes" 0 "No" ;
VAL_ 1251 BalrLeft4Fast_B_Stat 1 "Yes" 0 "No" ;
VAL_ 1251 BalrLeft4Dsply_B_Stat 1 "Yes" 0 "No" ;
VAL_ 1250 BalrLeft3Threat_D_Stat 1 "Yes" 0 "No" ;
VAL_ 1250 BalrLeft3Fast_B_Stat 1 "Yes" 0 "No" ;
VAL_ 1250 BalrLeft3Dsply_B_Stat 1 "Yes" 0 "No" ;
VAL_ 1249 BalrLeft2Threat_D_Stat 1 "Yes" 0 "No" ;
VAL_ 1249 BalrLeft2Fast_B_Stat 1 "Yes" 0 "No" ;
VAL_ 1249 BalrLeft2Dsply_B_Stat 1 "Yes" 0 "No" ;
VAL_ 1248 BalrLeft1Threat_D_Stat 1 "Yes" 0 "No" ;
VAL_ 1248 BalrLeft1Fast_B_Stat 1 "Yes" 0 "No" ;
VAL_ 1248 BalrLeft1Dsply_B_Stat 1 "Yes" 0 "No" ;
VAL_ 529 OnbChrgToPcWknd_D_Actl 7 "Percent_50" 6 "Percent_60" 5 "Percent_70" 4 "Percent_80" 3 "Percent_85" 2 "Percent_90" 1 "Percent_95" 0 "Percent_100" ;
VAL_ 529 OnbChrgToPcWkdy_D_Actl 7 "Percent_50" 6 "Percent_60" 5 "Percent_70" 4 "Percent_80" 3 "Percent_85" 2 "Percent_90" 1 "Percent_95" 0 "Percent_100" ;
VAL_ 529 OnbChrgSetNow_D_Rq 3 "NotUsed" 2 "On" 1 "Off" 0 "Null" ;
VAL_ 529 OnbChrgSetDelete_B_Rq 1 "Request" 0 "NoRequest" ;
VAL_ 529 OnbChrgPrflUpdate_B_Rq 1 "Request" 0 "NoRequest" ;
VAL_ 529 OnbChrgLocIdUns_B_Rq 1 "Request" 0 "NoRequest" ;
VAL_ 374 GearEngag_D_Actl 7 "Undefined" 6 "Fwd_Clutch_Fully_Engaged" 5 "Neutral_Idle" 4 "Disengaged_to_Neutral_Idle" 3 "Disengaged_to_Neutral_Park" 2 "Engagement_in_Progress" 1 "InitializeFwdClutchEngagmt" 0 "Park_Neutral" ;
VAL_ 374 TrnRng_D_Rq 15 "Fault" 14 "Unknown_Position" 13 "NotUsed_2" 12 "NotUsed_1" 11 "Range6" 10 "Range5" 9 "Range4" 8 "Range3_M3_L3" 7 "Range2_M2_L2" 6 "Range1_M1_L1" 5 "Low" 4 "Sport_DriveSport_Mposition" 3 "Drive" 2 "Neutral" 1 "Reverse" 0 "Park" ;
VAL_ 374 TrnPrkSys_D_Actl 15 "Faulty" 14 "NotUsed_5" 13 "NotUsed_4" 12 "NotUsed_3" 11 "NotUsed_2" 10 "NotUsed_1" 9 "FrequencyError" 8 "OutOfRangeHigh" 7 "OutOfRangeLow" 6 "Override" 5 "OutOfPark" 4 "TransitionCloseToOutOfPark" 3 "AtNoSpring" 2 "TransitionCloseToPark" 1 "Park" 0 "NotKnown" ;
VAL_ 374 GearPos_D_Actl 15 "Unknown" 14 "Reverse" 13 "Undefined_5" 12 "Undefined_4" 11 "Undefined_3" 10 "Tenth" 9 "Ninth" 8 "Eighth" 7 "Seventh" 6 "Sixth" 5 "Fifth" 4 "Fourth" 3 "Third" 2 "Second" 1 "First" 0 "Neutral" ;
VAL_ 374 GearPos_D_Trg 15 "Unknown" 14 "Reverse" 13 "Undefined_5" 12 "Undefined_4" 11 "Undefined_3" 10 "Tenth" 9 "Ninth" 8 "Eighth" 7 "Seventh" 6 "Sixth" 5 "Fifth" 4 "Fourth" 3 "Third" 2 "Second" 1 "First" 0 "Neutral" ;
VAL_ 374 GearLvr_D_ActlDrv 15 "Fault" 14 "Unknown_Position" 13 "NotUsed_2" 12 "NotUsed_1" 11 "Range6" 10 "Range5" 9 "Range4" 8 "Range3_M3_L3" 7 "Range2_M2_L2" 6 "Range1_M1_L1" 5 "Low" 4 "Sport_DriveSport_Mposition" 3 "Drive" 2 "Neutral" 1 "Reverse" 0 "Park" ;
VAL_ 500 Dsp_GetCDTOCDData_Rq 0 "Inactive" 2 "Off" 1 "TOC" ;
VAL_ 500 Dsp_CutItem_Rq 3 "Inactive" 2 "ThreeQuarterFromTheBeginn" 1 "End" 0 "Beginning" ;
VAL_ 500 Dsp_AudioSourceSel_Rq 5 "SDCard" 4 "Reserved" 3 "USB" 2 "BTAudio" 1 "CD" 0 "Inactive" ;
VAL_ 503 Dsp_AudioSourceSel3_Rq 3 "USB" 2 "BTAudio" 1 "CD" 0 "Inactive" ;
SIG_GROUP_ 932 Profile1A_SigGroup_FD1_3A4_Copy_ 1 : VehOnSrc2_D_Stat VehOnCtl_D_Stat VehStrtInhbt_D_Stat CanMsg3A4_No_Cnt VehInhbtMde_D_Stat CanMsg3A4_No_Crc;
